VERSION "HNNBNNNYNNNNNNNNNNNNNNNNNNNNNNNNNNNNNNNNNN/4/%%%/4/'%**4NNN///"

NS_ :

BS_:

BU_: AWC BAP_Tester BMC_MLBevo BMS_MV BMS_NV DCDC_800V_PAG DCDC_HV DCDC_HV_02 DCDC_IHEV FCU_MLBevo_FCEV Gateway Gateway_PAG Ladegeraet_2 Ladegeraet_Konzern LE1 LE2 LE2_3_MLBevo_LB LE_MLBevo LE_MLBevo_LB Sub_Gateway TME

BO_ 2589283856 DC_MV_Komponentenfehler_03: 8 DCDC_IHEV
 SG_ DC_MV_Komponentenfehler_63 : 0|2@1+ (1,0) [0|3] "" Vector__XXX
 SG_ DC_MV_Komponentenfehler_64 : 2|2@1+ (1,0) [0|3] "" Vector__XXX
 SG_ DC_MV_Komponentenfehler_65 : 4|2@1+ (1,0) [0|3] "" Vector__XXX
 SG_ DC_MV_Komponentenfehler_66 : 6|2@1+ (1,0) [0|3] "" Vector__XXX
 SG_ DC_MV_Komponentenfehler_67 : 8|2@1+ (1,0) [0|3] "" Vector__XXX
 SG_ DC_MV_Komponentenfehler_68 : 10|2@1+ (1,0) [0|3] "" Vector__XXX
 SG_ DC_MV_Komponentenfehler_69 : 12|2@1+ (1,0) [0|3] "" Vector__XXX
 SG_ DC_MV_Komponentenfehler_70 : 14|2@1+ (1,0) [0|3] "" Vector__XXX
 SG_ DC_MV_Komponentenfehler_71 : 16|2@1+ (1,0) [0|3] "" Vector__XXX
 SG_ DC_MV_Komponentenfehler_72 : 18|2@1+ (1,0) [0|3] "" Vector__XXX
 SG_ DC_MV_Komponentenfehler_73 : 20|2@1+ (1,0) [0|3] "" Vector__XXX
 SG_ DC_MV_Komponentenfehler_74 : 22|2@1+ (1,0) [0|3] "" Vector__XXX
 SG_ DC_MV_Komponentenfehler_75 : 24|2@1+ (1,0) [0|3] "" Vector__XXX
 SG_ DC_MV_Komponentenfehler_76 : 26|2@1+ (1,0) [0|3] "" Vector__XXX
 SG_ DC_MV_Komponentenfehler_77 : 28|2@1+ (1,0) [0|3] "" Vector__XXX
 SG_ DC_MV_Komponentenfehler_78 : 30|2@1+ (1,0) [0|3] "" Vector__XXX
 SG_ DC_MV_Komponentenfehler_79 : 32|2@1+ (1,0) [0|3] "" Vector__XXX
 SG_ DC_MV_Komponentenfehler_80 : 34|2@1+ (1,0) [0|3] "" Vector__XXX
 SG_ DC_MV_Komponentenfehler_81 : 36|2@1+ (1,0) [0|3] "" Vector__XXX
 SG_ DC_MV_Komponentenfehler_82 : 38|2@1+ (1,0) [0|3] "" Vector__XXX
 SG_ DC_MV_Komponentenfehler_83 : 40|2@1+ (1,0) [0|3] "" Vector__XXX
 SG_ DC_MV_Komponentenfehler_84 : 42|2@1+ (1,0) [0|3] "" Vector__XXX
 SG_ DC_MV_Komponentenfehler_85 : 44|2@1+ (1,0) [0|3] "" Vector__XXX
 SG_ DC_MV_Komponentenfehler_86 : 46|2@1+ (1,0) [0|3] "" Vector__XXX
 SG_ DC_MV_Komponentenfehler_87 : 48|2@1+ (1,0) [0|3] "" Vector__XXX
 SG_ DC_MV_Komponentenfehler_88 : 50|2@1+ (1,0) [0|3] "" Vector__XXX
 SG_ DC_MV_Komponentenfehler_89 : 52|2@1+ (1,0) [0|3] "" Vector__XXX
 SG_ DC_MV_Komponentenfehler_90 : 54|2@1+ (1,0) [0|3] "" Vector__XXX
 SG_ DC_MV_Komponentenfehler_91 : 56|2@1+ (1,0) [0|3] "" Vector__XXX
 SG_ DC_MV_Komponentenfehler_92 : 58|2@1+ (1,0) [0|3] "" Vector__XXX
 SG_ DC_MV_Komponentenfehler_93 : 60|2@1+ (1,0) [0|3] "" Vector__XXX

BO_ 2589283857 DC_MV_Komponentenfehler_04: 8 DCDC_IHEV
 SG_ DC_MV_Komponentenfehler_94 : 0|2@1+ (1,0) [0|3] "" Vector__XXX
 SG_ DC_MV_Komponentenfehler_95 : 2|2@1+ (1,0) [0|3] "" Vector__XXX
 SG_ DC_MV_Komponentenfehler_96 : 4|2@1+ (1,0) [0|3] "" Vector__XXX
 SG_ DC_MV_Komponentenfehler_97 : 6|2@1+ (1,0) [0|3] "" Vector__XXX
 SG_ DC_MV_Komponentenfehler_98 : 8|2@1+ (1,0) [0|3] "" Vector__XXX
 SG_ DC_MV_Komponentenfehler_99 : 10|2@1+ (1,0) [0|3] "" Vector__XXX
 SG_ DC_MV_Komponentenfehler_100 : 12|2@1+ (1,0) [0|3] "" Vector__XXX
 SG_ DC_MV_Komponentenfehler_101 : 14|2@1+ (1,0) [0|3] "" Vector__XXX
 SG_ DC_MV_Komponentenfehler_102 : 16|2@1+ (1,0) [0|3] "" Vector__XXX
 SG_ DC_MV_Komponentenfehler_103 : 18|2@1+ (1,0) [0|3] "" Vector__XXX
 SG_ DC_MV_Komponentenfehler_104 : 20|2@1+ (1,0) [0|3] "" Vector__XXX
 SG_ DC_MV_Komponentenfehler_105 : 22|2@1+ (1,0) [0|3] "" Vector__XXX
 SG_ DC_MV_Komponentenfehler_106 : 24|2@1+ (1,0) [0|3] "" Vector__XXX
 SG_ DC_MV_Komponentenfehler_107 : 26|2@1+ (1,0) [0|3] "" Vector__XXX
 SG_ DC_MV_Komponentenfehler_108 : 28|2@1+ (1,0) [0|3] "" Vector__XXX
 SG_ DC_MV_Komponentenfehler_109 : 30|2@1+ (1,0) [0|3] "" Vector__XXX
 SG_ DC_MV_Komponentenfehler_110 : 32|2@1+ (1,0) [0|3] "" Vector__XXX
 SG_ DC_MV_Komponentenfehler_111 : 34|2@1+ (1,0) [0|3] "" Vector__XXX
 SG_ DC_MV_Komponentenfehler_112 : 36|2@1+ (1,0) [0|3] "" Vector__XXX
 SG_ DC_MV_Komponentenfehler_113 : 38|2@1+ (1,0) [0|3] "" Vector__XXX
 SG_ DC_MV_Komponentenfehler_114 : 40|2@1+ (1,0) [0|3] "" Vector__XXX
 SG_ DC_MV_Komponentenfehler_115 : 42|2@1+ (1,0) [0|3] "" Vector__XXX
 SG_ DC_MV_Komponentenfehler_116 : 44|2@1+ (1,0) [0|3] "" Vector__XXX
 SG_ DC_MV_Komponentenfehler_117 : 46|2@1+ (1,0) [0|3] "" Vector__XXX
 SG_ DC_MV_Komponentenfehler_118 : 48|2@1+ (1,0) [0|3] "" Vector__XXX
 SG_ DC_MV_Komponentenfehler_119 : 50|2@1+ (1,0) [0|3] "" Vector__XXX
 SG_ DC_MV_Komponentenfehler_120 : 52|2@1+ (1,0) [0|3] "" Vector__XXX
 SG_ DC_MV_Komponentenfehler_121 : 54|2@1+ (1,0) [0|3] "" Vector__XXX
 SG_ DC_MV_Komponentenfehler_122 : 56|2@1+ (1,0) [0|3] "" Vector__XXX
 SG_ DC_MV_Komponentenfehler_123 : 58|2@1+ (1,0) [0|3] "" Vector__XXX
 SG_ DC_MV_Komponentenfehler_124 : 60|2@1+ (1,0) [0|3] "" Vector__XXX

BO_ 2589283858 DC_MV_Komponentenfehler_05: 8 DCDC_IHEV
 SG_ DC_MV_Komponentenfehler_125 : 0|2@1+ (1,0) [0|3] "" Vector__XXX
 SG_ DC_MV_Komponentenfehler_126 : 2|2@1+ (1,0) [0|3] "" Vector__XXX
 SG_ DC_MV_Komponentenfehler_127 : 4|2@1+ (1,0) [0|3] "" Vector__XXX
 SG_ DC_MV_Komponentenfehler_128 : 6|2@1+ (1,0) [0|3] "" Vector__XXX
 SG_ DC_MV_Komponentenfehler_129 : 8|2@1+ (1,0) [0|3] "" Vector__XXX
 SG_ DC_MV_Komponentenfehler_130 : 10|2@1+ (1,0) [0|3] "" Vector__XXX
 SG_ DC_MV_Komponentenfehler_131 : 12|2@1+ (1,0) [0|3] "" Vector__XXX
 SG_ DC_MV_Komponentenfehler_132 : 14|2@1+ (1,0) [0|3] "" Vector__XXX
 SG_ DC_MV_Komponentenfehler_133 : 16|2@1+ (1,0) [0|3] "" Vector__XXX
 SG_ DC_MV_Komponentenfehler_134 : 18|2@1+ (1,0) [0|3] "" Vector__XXX
 SG_ DC_MV_Komponentenfehler_135 : 20|2@1+ (1,0) [0|3] "" Vector__XXX
 SG_ DC_MV_Komponentenfehler_136 : 22|2@1+ (1,0) [0|3] "" Vector__XXX
 SG_ DC_MV_Komponentenfehler_137 : 24|2@1+ (1,0) [0|3] "" Vector__XXX
 SG_ DC_MV_Komponentenfehler_138 : 26|2@1+ (1,0) [0|3] "" Vector__XXX
 SG_ DC_MV_Komponentenfehler_139 : 28|2@1+ (1,0) [0|3] "" Vector__XXX
 SG_ DC_MV_Komponentenfehler_140 : 30|2@1+ (1,0) [0|3] "" Vector__XXX
 SG_ DC_MV_Komponentenfehler_141 : 32|2@1+ (1,0) [0|3] "" Vector__XXX
 SG_ DC_MV_Komponentenfehler_142 : 34|2@1+ (1,0) [0|3] "" Vector__XXX
 SG_ DC_MV_Komponentenfehler_143 : 36|2@1+ (1,0) [0|3] "" Vector__XXX
 SG_ DC_MV_Komponentenfehler_144 : 38|2@1+ (1,0) [0|3] "" Vector__XXX
 SG_ DC_MV_Komponentenfehler_145 : 40|2@1+ (1,0) [0|3] "" Vector__XXX

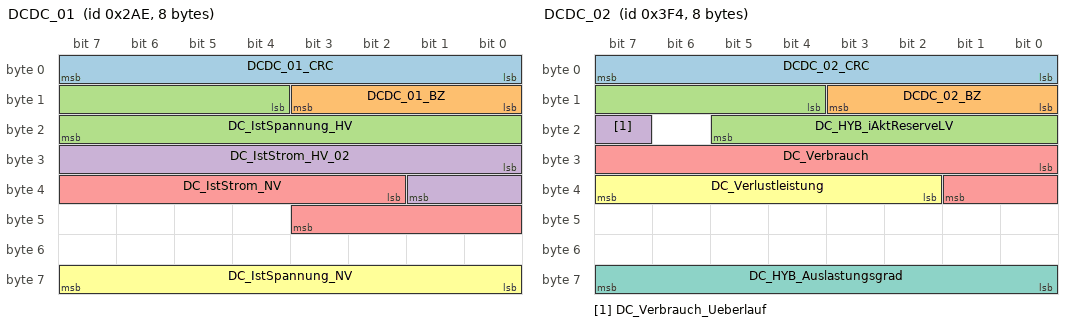
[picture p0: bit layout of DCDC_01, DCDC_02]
BO_ 686 DCDC_01: 8 DCDC_800V_PAG
 SG_ DCDC_01_CRC : 0|8@1+ (1,0) [0|255] ""  Gateway,Gateway_PAG
 SG_ DCDC_01_BZ : 8|4@1+ (1,0) [0|15] ""  Gateway,Gateway_PAG
 SG_ DC_IstSpannung_HV : 12|12@1+ (0.25,0) [0|1023.25] "Unit_Volt"  BMC_MLBevo,DCDC_HV_02,Gateway,Gateway_PAG,TME
 SG_ DC_IstStrom_HV_02 : 24|10@1+ (0.4,-204) [-204|204] "Unit_Amper"  DCDC_HV_02,Gateway,Gateway_PAG,Ladegeraet_Konzern,TME
 SG_ DC_IstStrom_NV : 34|10@1+ (1,-511) [-511|510] "Unit_Amper"  Gateway,Gateway_PAG
 SG_ DC_IstSpannung_NV : 56|8@1+ (0.1,0) [0|25.3] "Unit_Volt"  AWC,Gateway,Gateway_PAG,Ladegeraet_2,Ladegeraet_Konzern

BO_ 1012 DCDC_02: 8 DCDC_800V_PAG
 SG_ DCDC_02_CRC : 0|8@1+ (1,0) [0|255] ""  Gateway,Gateway_PAG
 SG_ DCDC_02_BZ : 8|4@1+ (1,0) [0|15] ""  Gateway,Gateway_PAG
 SG_ DC_HYB_iAktReserveLV : 12|10@1+ (1,-511) [-511|510] "Unit_Amper"  Gateway,Gateway_PAG
 SG_ DC_Verbrauch_Ueberlauf : 23|1@1+ (1,0) [0|1] ""  Gateway,Gateway_PAG
 SG_ DC_Verbrauch : 24|10@1+ (1,0) [0|1023] "Unit_WattSecond"  Gateway,Gateway_PAG
 SG_ DC_Verlustleistung : 34|6@1+ (5,0) [0|305] "Unit_Watt"  Gateway,Gateway_PAG,TME
 SG_ DC_HYB_Auslastungsgrad : 56|8@1+ (0.4,0) [0|100] "Unit_PerCent"  Gateway,Gateway_PAG,TME

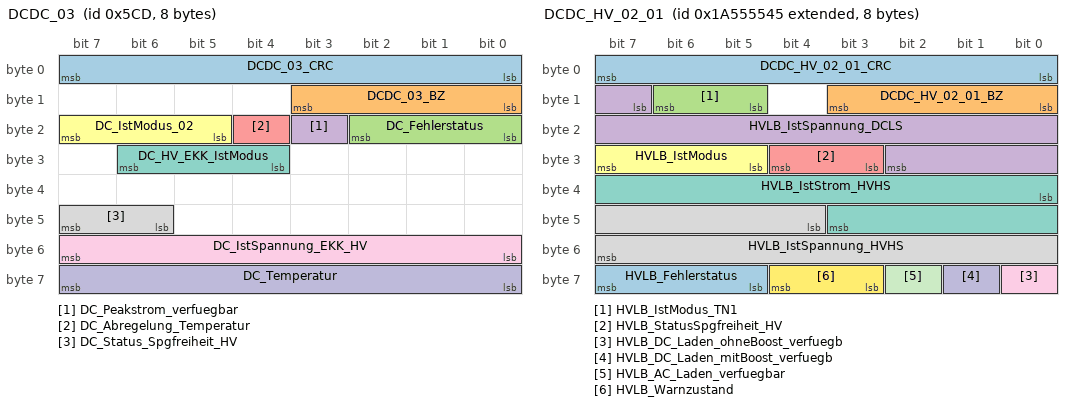
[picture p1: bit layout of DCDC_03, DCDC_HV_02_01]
BO_ 1485 DCDC_03: 8 DCDC_800V_PAG
 SG_ DCDC_03_CRC : 0|8@1+ (1,0) [0|255] ""  Gateway,Gateway_PAG,Sub_Gateway
 SG_ DCDC_03_BZ : 8|4@1+ (1,0) [0|15] ""  Gateway,Gateway_PAG,Sub_Gateway
 SG_ DC_Fehlerstatus : 16|3@1+ (1,0) [0|7] ""  Gateway,Gateway_PAG,Sub_Gateway
 SG_ DC_Peakstrom_verfuegbar : 19|1@1+ (1,0) [0|1] ""  Gateway,Gateway_PAG,Sub_Gateway
 SG_ DC_Abregelung_Temperatur : 20|1@1+ (1,0) [0|1] ""  Gateway_PAG,Sub_Gateway,TME
 SG_ DC_IstModus_02 : 21|3@1+ (1,0) [0|7] ""  DCDC_HV_02,Gateway,Gateway_PAG,Ladegeraet_Konzern,Sub_Gateway,TME
 SG_ DC_HV_EKK_IstModus : 28|3@1+ (1,0) [0|7] ""  Gateway,Gateway_PAG,Sub_Gateway,TME
 SG_ DC_Status_Spgfreiheit_HV : 46|2@1+ (1,0) [0|3] ""  Gateway,Gateway_PAG,Sub_Gateway
 SG_ DC_IstSpannung_EKK_HV : 48|8@1+ (2,0) [0|508] "Unit_Volt"  Gateway,Gateway_PAG,Sub_Gateway
 SG_ DC_Temperatur : 56|8@1+ (1,-40) [-40|213] "Unit_DegreCelsi"  Gateway,Gateway_PAG,Sub_Gateway,TME

BO_ 2527679744 DCDC_FC_03: 8 FCU_MLBevo_FCEV
 SG_ DCDC_FC_IstModus : 12|4@1+ (1,0) [0|15] "" Vector__XXX
 SG_ DCDC_FC_Abschaltung_Ges : 16|1@1+ (1,0) [0|1] "" Vector__XXX
 SG_ DCDC_FC_Abschaltung_Prim : 17|1@1+ (1,0) [0|1] "" Vector__XXX
 SG_ DCDC_FC_Anf_Abschaltung_Ges : 18|1@1+ (1,0) [0|1] "" Vector__XXX
 SG_ DCDC_FC_Anf_Abschaltung_Prim : 19|1@1+ (1,0) [0|1] "" Vector__XXX
 SG_ DCDC_FC_Begrenz_MaxSpannung_Prim : 20|1@1+ (1,0) [0|1] "" Vector__XXX
 SG_ DCDC_FC_Begrenz_MaxSpannung_Sek : 21|1@1+ (1,0) [0|1] "" Vector__XXX
 SG_ DCDC_FC_Begrenz_MaxStrom_Prim : 22|1@1+ (1,0) [0|1] "" Vector__XXX
 SG_ DCDC_FC_Begrenz_MaxStrom_Sek : 23|1@1+ (1,0) [0|1] "" Vector__XXX
 SG_ DCDC_FC_Begrenz_MinSpannung_Prim : 24|1@1+ (1,0) [0|1] "" Vector__XXX
 SG_ DCDC_FC_Begrenz_MinSpannung_Sek : 25|1@1+ (1,0) [0|1] "" Vector__XXX
 SG_ DCDC_FC_Begrenz_MinStrom_Prim : 26|1@1+ (1,0) [0|1] "" Vector__XXX
 SG_ DCDC_FC_Begrenz_Temp : 27|1@1+ (1,0) [0|1] "" Vector__XXX
 SG_ DCDC_FC_Diodenbetrieb : 28|1@1+ (1,0) [0|1] "" Vector__XXX
 SG_ DCDC_FC_Fehlerstatus : 29|3@1+ (1,0) [0|7] "" Vector__XXX
 SG_ DCDC_FC_Status_HVSwitch : 32|3@1+ (1,0) [0|7] "" Vector__XXX
 SG_ DCDC_FC_Status_Interlock : 35|2@1+ (1,0) [0|3] ""  Gateway
 SG_ DCDC_FC_Status_Isowaechter_Netz2 : 37|3@1+ (1,0) [0|7] ""  Gateway
 SG_ DCDC_FC_Status_Kl15c : 40|2@1+ (1,0) [0|3] "" Vector__XXX
 SG_ DCDC_FC_Status_Kl30C : 42|2@1+ (1,0) [0|3] "" Vector__XXX
 SG_ DCDC_FC_Temperatur : 56|8@1+ (1,-40) [-40|213] "Unit_DegreCelsi"  TME

BO_ 2589283653 DCDC_HV_02_01: 8 DCDC_HV_02
 SG_ DCDC_HV_02_01_CRC : 0|8@1+ (1,0) [0|255] ""  Gateway,Gateway_PAG,Ladegeraet_Konzern
 SG_ DCDC_HV_02_01_BZ : 8|4@1+ (1,0) [0|15] ""  Gateway,Gateway_PAG,Ladegeraet_Konzern
 SG_ HVLB_IstModus_TN1 : 13|2@1+ (1,0) [0|3] ""  Gateway,Gateway_PAG
 SG_ HVLB_IstSpannung_DCLS : 15|12@1+ (0.25,0) [0|1023.25] "Unit_Volt"  Ladegeraet_Konzern
 SG_ HVLB_StatusSpgfreiheit_HV : 27|2@1+ (1,0) [0|3] ""  Gateway,Gateway_PAG
 SG_ HVLB_IstModus : 29|3@1+ (1,0) [0|7] ""  Ladegeraet_Konzern,TME
 SG_ HVLB_IstStrom_HVHS : 32|12@1+ (0.25,-512) [-512|511.25] "Unit_Amper"  Ladegeraet_Konzern
 SG_ HVLB_IstSpannung_HVHS : 44|12@1+ (0.25,0) [0|1023.25] "Unit_Volt"  Gateway,Gateway_PAG,Ladegeraet_Konzern
 SG_ HVLB_DC_Laden_ohneBoost_verfuegb : 56|1@1+ (1,0) [0|1] ""  Ladegeraet_Konzern
 SG_ HVLB_DC_Laden_mitBoost_verfuegb : 57|1@1+ (1,0) [0|1] ""  Ladegeraet_Konzern
 SG_ HVLB_AC_Laden_verfuegbar : 58|1@1+ (1,0) [0|1] ""  Ladegeraet_Konzern
 SG_ HVLB_Warnzustand : 59|2@1+ (1,0) [0|3] ""  Ladegeraet_Konzern
 SG_ HVLB_Fehlerstatus : 61|3@1+ (1,0) [0|7] ""  Gateway,Gateway_PAG,Ladegeraet_Konzern

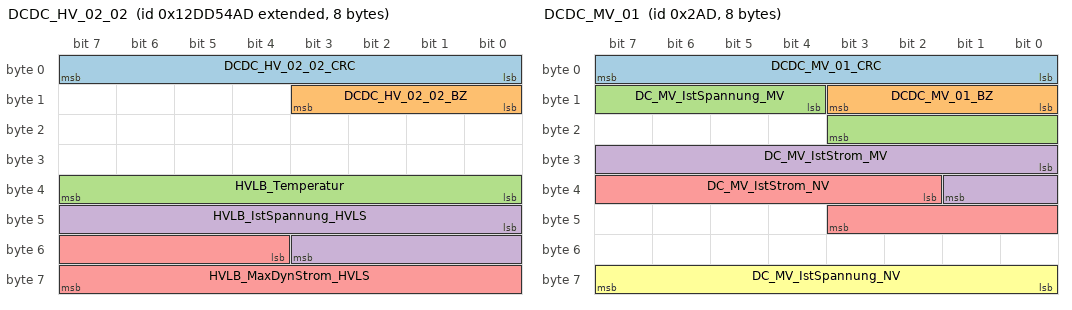
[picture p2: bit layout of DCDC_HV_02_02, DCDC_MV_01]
BO_ 2463978669 DCDC_HV_02_02: 8 DCDC_HV_02
 SG_ DCDC_HV_02_02_CRC : 0|8@1+ (1,0) [0|255] ""  Gateway_PAG,Ladegeraet_Konzern
 SG_ DCDC_HV_02_02_BZ : 8|4@1+ (1,0) [0|15] ""  Gateway_PAG,Ladegeraet_Konzern
 SG_ HVLB_Temperatur : 32|8@1+ (1,-40) [-40|213] "Unit_DegreCelsi"  Gateway_PAG,TME
 SG_ HVLB_IstSpannung_HVLS : 40|12@1+ (0.25,0) [0|1023.25] "Unit_Volt"  Gateway_PAG,Ladegeraet_Konzern
 SG_ HVLB_MaxDynStrom_HVLS : 52|12@1+ (0.25,-512) [-512|511.25] "Unit_Amper"  Gateway_PAG,Ladegeraet_Konzern

BO_ 2589283662 DCDC_HV_02_03: 8 DCDC_HV_02
 SG_ HVLB_PlanAntw_Verlustleistung : 48|12@1+ (50,0) [0|204650] "Unit_Watt"  Ladegeraet_Konzern,TME
 SG_ HVLB_PlanAntw_Zaehler : 60|4@1+ (1,0) [0|13] "Unit_None"  Ladegeraet_Konzern,TME

BO_ 685 DCDC_MV_01: 8 DCDC_800V_PAG
 SG_ DCDC_MV_01_CRC : 0|8@1+ (1,0) [0|255] ""  Gateway,Gateway_PAG
 SG_ DCDC_MV_01_BZ : 8|4@1+ (1,0) [0|15] ""  Gateway,Gateway_PAG
 SG_ DC_MV_IstSpannung_MV : 12|8@1+ (0.25,0) [0|63.25] "Unit_Volt"  Gateway,Gateway_PAG
 SG_ DC_MV_IstStrom_MV : 24|10@1+ (0.4,-204) [-204|204] "Unit_Amper"  Gateway,Gateway_PAG
 SG_ DC_MV_IstStrom_NV : 34|10@1+ (1,-511) [-511|510] "Unit_Amper"  Gateway,Gateway_PAG
 SG_ DC_MV_IstSpannung_NV : 56|8@1+ (0.1,0) [0|25.3] "Unit_Volt"  Gateway,Gateway_PAG

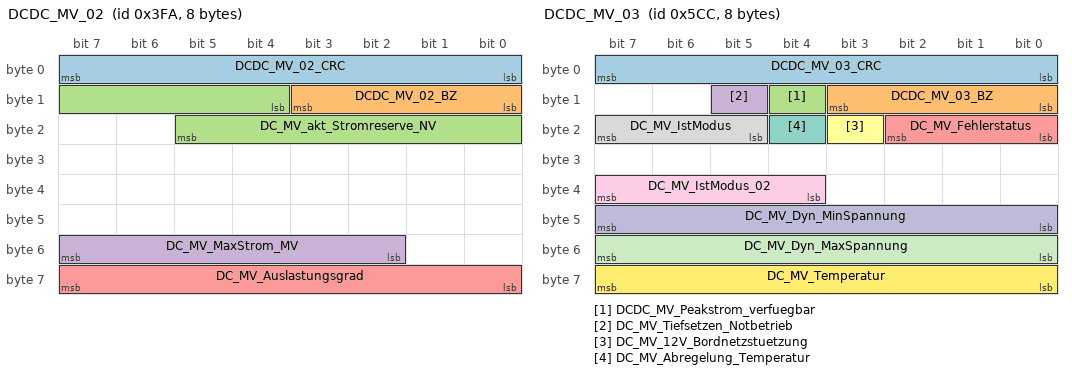
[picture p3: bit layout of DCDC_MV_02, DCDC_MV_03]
BO_ 1018 DCDC_MV_02: 8 DCDC_800V_PAG
 SG_ DCDC_MV_02_CRC : 0|8@1+ (1,0) [0|255] ""  Gateway,Gateway_PAG
 SG_ DCDC_MV_02_BZ : 8|4@1+ (1,0) [0|15] ""  Gateway,Gateway_PAG
 SG_ DC_MV_akt_Stromreserve_NV : 12|10@1+ (1,-511) [-511|510] "Unit_Amper"  Gateway,Gateway_PAG
 SG_ DC_MV_MaxStrom_MV : 50|6@1+ (2.5,-152.5) [-152.5|0] "Unit_Amper"  Gateway,Gateway_PAG
 SG_ DC_MV_Auslastungsgrad : 56|8@1+ (0.4,0) [0|100] "Unit_PerCent"  Gateway,Gateway_PAG

BO_ 1484 DCDC_MV_03: 8 DCDC_800V_PAG
 SG_ DCDC_MV_03_CRC : 0|8@1+ (1,0) [0|255] ""  Gateway,Gateway_PAG,Sub_Gateway
 SG_ DCDC_MV_03_BZ : 8|4@1+ (1,0) [0|15] ""  Gateway,Gateway_PAG,Sub_Gateway
 SG_ DCDC_MV_Peakstrom_verfuegbar : 12|1@1+ (1,0) [0|1] ""  Gateway,Gateway_PAG,Sub_Gateway
 SG_ DC_MV_Tiefsetzen_Notbetrieb : 13|1@1+ (1,0) [0|1] ""  Gateway,Gateway_PAG,Sub_Gateway
 SG_ DC_MV_Fehlerstatus : 16|3@1+ (1,0) [0|7] ""  Gateway,Gateway_PAG,Sub_Gateway
 SG_ DC_MV_12V_Bordnetzstuetzung : 19|1@1+ (1,0) [0|1] ""  Gateway,Gateway_PAG,Sub_Gateway
 SG_ DC_MV_Abregelung_Temperatur : 20|1@1+ (1,0) [0|1] ""  Gateway_PAG,Sub_Gateway,TME
 SG_ DC_MV_IstModus : 21|3@1+ (1,0) [0|7] ""  Gateway,Gateway_PAG,Sub_Gateway
 SG_ DC_MV_IstModus_02 : 36|4@1+ (1,0) [0|15] ""  Gateway,Gateway_PAG,Sub_Gateway
 SG_ DC_MV_Dyn_MinSpannung : 40|8@1+ (0.25,0) [0|63.25] "Unit_Volt"  Gateway,Gateway_PAG,Sub_Gateway
 SG_ DC_MV_Dyn_MaxSpannung : 48|8@1+ (0.25,0) [0|63.25] "Unit_Volt"  Gateway,Gateway_PAG,Sub_Gateway
 SG_ DC_MV_Temperatur : 56|8@1+ (1,-40) [-40|213] "Unit_DegreCelsi"  Gateway_PAG,Sub_Gateway,TME

BO_ 2617015040 DEV_AWC_Resp_00: 8 AWC
 SG_ DEV_AWC_Resp_00_Data : 0|64@1+ (1,0) [0|1.84467440737096E+019] "" Vector__XXX

BO_ 2617015295 DEV_AWC_Resp_FF: 8 AWC
 SG_ DEV_AWC_Resp_FF_Data : 0|64@1+ (1,0) [0|1.84467440737096E+019] "" Vector__XXX

BO_ 2617078528 DEV_BattRegelung_Req_00: 8 Vector__XXX
 SG_ DEV_BattRegelung_Req_00_Data : 0|64@1+ (1,0) [0|1.84467440737096E+019] ""  BMS_NV

BO_ 2617078783 DEV_BattRegelung_Resp_FF: 8 BMS_NV
 SG_ DEV_BattRegelung_Resp_FF_Data : 0|64@1+ (1,0) [0|1.84467440737096E+019] "" Vector__XXX

BO_ 2617041664 DEV_BMS_MV_Resp_00: 8 Vector__XXX
 SG_ DEV_BMS_MV_Resp_00_Data : 0|64@1+ (1,0) [0|1.84467440737096E+019] "" Vector__XXX

BO_ 2617041919 DEV_BMS_MV_Resp_FF: 8 Vector__XXX
 SG_ DEV_BMS_MV_Resp_FF_Data : 0|64@1+ (1,0) [0|1.84467440737096E+019] "" Vector__XXX

BO_ 2617235968 DEV_BMS_Resp_00: 8 BMC_MLBevo
 SG_ DEV_BMS_Resp_00_Data : 0|64@1+ (1,0) [0|1.84467440737096E+019] "" Vector__XXX

BO_ 2617236223 DEV_BMS_Resp_FF: 8 BMC_MLBevo
 SG_ DEV_BMS_Resp_FF_Data : 0|64@1+ (1,0) [0|1.84467440737096E+019] "" Vector__XXX

BO_ 2617129728 DEV_DCDC_HV_02_Req_01: 8 Vector__XXX
 SG_ DEV_DCDC_HV_02_Req_01_Data : 0|64@1+ (1,0) [0|1.84467440737096E+019] ""  DCDC_HV_02

BO_ 2617129729 DEV_DCDC_HV_02_Resp_01: 8 DCDC_HV_02
 SG_ DEV_DCDC_HV_02_Resp_01_Data : 0|64@1+ (1,0) [0|1.84467440737096E+019] "" Vector__XXX

BO_ 2617129983 DEV_DCDC_HV_02_Resp_FF: 8 DCDC_HV_02
 SG_ DEV_DCDC_HV_02_Resp_FF_Data : 0|64@1+ (1,0) [0|1.84467440737096E+019] "" Vector__XXX

BO_ 2617096960 DEV_DCDC_HV_Resp_00: 8 DCDC_800V_PAG
 SG_ DEV_DCDC_HV_Resp_00_Data : 0|64@1+ (1,0) [0|1.84467440737096E+019] "" Vector__XXX

BO_ 2617097215 DEV_DCDC_HV_Resp_FF: 8 DCDC_800V_PAG
 SG_ DEV_DCDC_HV_Resp_FF_Data : 0|64@1+ (1,0) [0|1.84467440737096E+019] "" Vector__XXX

BO_ 2617117184 DEV_DCDC_Resp_00: 8 DCDC_IHEV
 SG_ DEV_DCDC_Resp_00_Data : 0|64@1+ (1,0) [0|1.84467440737096E+019] "" Vector__XXX

BO_ 2617117439 DEV_DCDC_Resp_FF: 8 DCDC_IHEV
 SG_ DEV_DCDC_Resp_FF_Data : 0|64@1+ (1,0) [0|1.84467440737096E+019] "" Vector__XXX

BO_ 2617092864 DEV_FCU_Req_01: 8 Vector__XXX
 SG_ DEV_FCU_Req_01_Data : 0|64@1+ (1,0) [0|1.84467440737096E+019] ""  FCU_MLBevo_FCEV

BO_ 2617093119 DEV_FCU_Resp_FF: 8 FCU_MLBevo_FCEV
 SG_ DEV_FCU_Resp_FF_Data : 0|64@1+ (1,0) [0|1.84467440737096E+019] "" Vector__XXX

BO_ 2617193216 DEV_Ladegeraet_2_Req_01: 8 Vector__XXX
 SG_ DEV_Ladegeraet_2_Req_01_Data : 0|64@1+ (1,0) [0|1.84467440737096E+019] ""  Ladegeraet_2

BO_ 2617193217 DEV_Ladegeraet_2_Resp_01: 8 Ladegeraet_2
 SG_ DEV_Ladegeraet_2_Resp_01_Data : 0|64@1+ (1,0) [0|1.84467440737096E+019] "" Vector__XXX

BO_ 2617193471 DEV_Ladegeraet_2_Resp_FF: 8 Ladegeraet_2
 SG_ DEV_Ladegeraet_2_Resp_FF_Data : 0|64@1+ (1,0) [0|1.84467440737096E+019] "" Vector__XXX

BO_ 2617123328 DEV_Ladegeraet_Req_01: 8 Vector__XXX
 SG_ DEV_Ladegeraet_Req_01_Data : 0|64@1+ (1,0) [0|1.84467440737096E+019] ""  Ladegeraet_Konzern

BO_ 2617123329 DEV_Ladegeraet_Resp_01: 8 Ladegeraet_Konzern
 SG_ DEV_Ladegeraet_Resp_01_Data : 0|64@1+ (1,0) [0|1.84467440737096E+019] "" Vector__XXX

BO_ 2617123583 DEV_Ladegeraet_Resp_FF: 8 Ladegeraet_Konzern
 SG_ DEV_Ladegeraet_Resp_FF_Data : 0|64@1+ (1,0) [0|1.84467440737096E+019] "" Vector__XXX

BO_ 2617238016 DEV_LEH_01_Resp_00: 8 DCDC_HV
 SG_ DEV_LEH_01_Resp_00_Data : 0|64@1+ (1,0) [0|1.84467440737096E+019] "" Vector__XXX

BO_ 2617238271 DEV_LEH_01_Resp_FF: 8 DCDC_HV
 SG_ DEV_LEH_01_Resp_FF_Data : 0|64@1+ (1,0) [0|1.84467440737096E+019] "" Vector__XXX

BO_ 2617119232 DEV_TME_Resp_00: 8 TME
 SG_ DEV_TME_Resp_00_Data : 0|64@1+ (1,0) [0|1.84467440737096E+019] "" Vector__XXX

BO_ 2617119487 DEV_TME_Resp_FF: 8 TME
 SG_ DEV_TME_Resp_FF_Data : 0|64@1+ (1,0) [0|1.84467440737096E+019] "" Vector__XXX

BO_ 2549880528 DIA_BJB_Req: 8 Gateway
 SG_ DIA_BJB_Req_Data : 0|64@1+ (1,0) [0|1.84467440737096E+019] ""  BMC_MLBevo

BO_ 2550011600 DIA_BJB_Resp: 8 BMC_MLBevo
 SG_ DIA_BJB_Resp_Data : 0|64@1+ (1,0) [0|1.84467440737096E+019] ""  Gateway,Gateway_PAG

BO_ 2549880529 DIA_CMC_01_Req: 8 Gateway
 SG_ DIA_CMC_01_Req_Data : 0|64@1+ (1,0) [0|1.84467440737096E+019] ""  BMC_MLBevo

BO_ 2550011601 DIA_CMC_01_Resp: 8 BMC_MLBevo
 SG_ DIA_CMC_01_Resp_Data : 0|64@1+ (1,0) [0|1.84467440737096E+019] ""  Gateway,Gateway_PAG

BO_ 2549880530 DIA_CMC_02_Req: 8 Gateway
 SG_ DIA_CMC_02_Req_Data : 0|64@1+ (1,0) [0|1.84467440737096E+019] ""  BMC_MLBevo

BO_ 2550011602 DIA_CMC_02_Resp: 8 BMC_MLBevo
 SG_ DIA_CMC_02_Resp_Data : 0|64@1+ (1,0) [0|1.84467440737096E+019] ""  Gateway,Gateway_PAG

BO_ 2549880531 DIA_CMC_03_Req: 8 Gateway
 SG_ DIA_CMC_03_Req_Data : 0|64@1+ (1,0) [0|1.84467440737096E+019] ""  BMC_MLBevo

BO_ 2550011603 DIA_CMC_03_Resp: 8 BMC_MLBevo
 SG_ DIA_CMC_03_Resp_Data : 0|64@1+ (1,0) [0|1.84467440737096E+019] ""  Gateway,Gateway_PAG

BO_ 2549880532 DIA_CMC_04_Req: 8 Gateway
 SG_ DIA_CMC_04_Req_Data : 0|64@1+ (1,0) [0|1.84467440737096E+019] ""  BMC_MLBevo

BO_ 2550011604 DIA_CMC_04_Resp: 8 BMC_MLBevo
 SG_ DIA_CMC_04_Resp_Data : 0|64@1+ (1,0) [0|1.84467440737096E+019] ""  Gateway,Gateway_PAG

BO_ 2549880533 DIA_CMC_05_Req: 8 Gateway
 SG_ DIA_CMC_05_Req_Data : 0|64@1+ (1,0) [0|1.84467440737096E+019] ""  BMC_MLBevo

BO_ 2550011605 DIA_CMC_05_Resp: 8 BMC_MLBevo
 SG_ DIA_CMC_05_Resp_Data : 0|64@1+ (1,0) [0|1.84467440737096E+019] ""  Gateway,Gateway_PAG

BO_ 2549880534 DIA_CMC_06_Req: 8 Gateway
 SG_ DIA_CMC_06_Req_Data : 0|64@1+ (1,0) [0|1.84467440737096E+019] ""  BMC_MLBevo

BO_ 2550011606 DIA_CMC_06_Resp: 8 BMC_MLBevo
 SG_ DIA_CMC_06_Resp_Data : 0|64@1+ (1,0) [0|1.84467440737096E+019] ""  Gateway,Gateway_PAG

BO_ 2549880535 DIA_CMC_07_Req: 8 Gateway
 SG_ DIA_CMC_07_Req_Data : 0|64@1+ (1,0) [0|1.84467440737096E+019] ""  BMC_MLBevo

BO_ 2550011607 DIA_CMC_07_Resp: 8 BMC_MLBevo
 SG_ DIA_CMC_07_Resp_Data : 0|64@1+ (1,0) [0|1.84467440737096E+019] ""  Gateway,Gateway_PAG

BO_ 2549880536 DIA_CMC_08_Req: 8 Gateway
 SG_ DIA_CMC_08_Req_Data : 0|64@1+ (1,0) [0|1.84467440737096E+019] ""  BMC_MLBevo

BO_ 2550011608 DIA_CMC_08_Resp: 8 BMC_MLBevo
 SG_ DIA_CMC_08_Resp_Data : 0|64@1+ (1,0) [0|1.84467440737096E+019] ""  Gateway,Gateway_PAG

BO_ 2549880537 DIA_CMC_09_Req: 8 Gateway
 SG_ DIA_CMC_09_Req_Data : 0|64@1+ (1,0) [0|1.84467440737096E+019] ""  BMC_MLBevo

BO_ 2550011609 DIA_CMC_09_Resp: 8 BMC_MLBevo
 SG_ DIA_CMC_09_Resp_Data : 0|64@1+ (1,0) [0|1.84467440737096E+019] ""  Gateway,Gateway_PAG

BO_ 2549880538 DIA_CMC_10_Req: 8 Gateway
 SG_ DIA_CMC_10_Req_Data : 0|64@1+ (1,0) [0|1.84467440737096E+019] ""  BMC_MLBevo

BO_ 2550011610 DIA_CMC_10_Resp: 8 BMC_MLBevo
 SG_ DIA_CMC_10_Resp_Data : 0|64@1+ (1,0) [0|1.84467440737096E+019] ""  Gateway,Gateway_PAG

BO_ 2549880539 DIA_CMC_11_Req: 8 Gateway
 SG_ DIA_CMC_11_Req_Data : 0|64@1+ (1,0) [0|1.84467440737096E+019] ""  BMC_MLBevo

BO_ 2550011611 DIA_CMC_11_Resp: 8 BMC_MLBevo
 SG_ DIA_CMC_11_Resp_Data : 0|64@1+ (1,0) [0|1.84467440737096E+019] ""  Gateway,Gateway_PAG

BO_ 2549880540 DIA_CMC_12_Req: 8 Gateway
 SG_ DIA_CMC_12_Req_Data : 0|64@1+ (1,0) [0|1.84467440737096E+019] ""  BMC_MLBevo

BO_ 2550011612 DIA_CMC_12_Resp: 8 BMC_MLBevo
 SG_ DIA_CMC_12_Resp_Data : 0|64@1+ (1,0) [0|1.84467440737096E+019] ""  Gateway,Gateway_PAG

BO_ 2549880561 DIA_CMC_13_Req: 8 Gateway
 SG_ DIA_CMC_13_Req_Data : 0|64@1+ (1,0) [0|1.84467440737096E+019] ""  BMC_MLBevo

BO_ 2550011633 DIA_CMC_13_Resp: 8 BMC_MLBevo
 SG_ DIA_CMC_13_Resp_Data : 0|64@1+ (1,0) [0|1.84467440737096E+019] ""  Gateway,Gateway_PAG

BO_ 2549880562 DIA_CMC_14_Req: 8 Gateway
 SG_ DIA_CMC_14_Req_Data : 0|64@1+ (1,0) [0|1.84467440737096E+019] ""  BMC_MLBevo

BO_ 2550011634 DIA_CMC_14_Resp: 8 BMC_MLBevo
 SG_ DIA_CMC_14_Resp_Data : 0|64@1+ (1,0) [0|1.84467440737096E+019] ""  Gateway,Gateway_PAG

BO_ 2549880563 DIA_CMC_15_Req: 8 Gateway
 SG_ DIA_CMC_15_Req_Data : 0|64@1+ (1,0) [0|1.84467440737096E+019] ""  BMC_MLBevo

BO_ 2550011635 DIA_CMC_15_Resp: 8 BMC_MLBevo
 SG_ DIA_CMC_15_Resp_Data : 0|64@1+ (1,0) [0|1.84467440737096E+019] ""  Gateway,Gateway_PAG

BO_ 2549880717 DIA_eBooster2_Req: 8 Gateway
 SG_ DIA_eBooster2_Req_Data : 0|64@1+ (1,0) [0|1.84467440737096E+019] ""  FCU_MLBevo_FCEV

BO_ 2550011789 DIA_eBooster2_Resp: 8 FCU_MLBevo_FCEV
 SG_ DIA_eBooster2_Resp_Data : 0|64@1+ (1,0) [0|1.84467440737096E+019] ""  Gateway

BO_ 2549880413 DIA_EKK_Req: 8 Gateway
 SG_ DIA_EKK_Req_Data : 0|64@1+ (1,0) [0|1.84467440737096E+019] ""  TME

BO_ 2550011485 DIA_EKK_Resp: 8 TME
 SG_ DIA_EKK_Resp_Data : 0|64@1+ (1,0) [0|1.84467440737096E+019] ""  Gateway,Gateway_PAG

BO_ 2549880512 DIA_HV_H2_Req: 8 Gateway
 SG_ DIA_HV_H2_Req_Data : 0|64@1+ (1,0) [0|1.84467440737096E+019] ""  FCU_MLBevo_FCEV,TME

BO_ 2550011584 DIA_HV_H2_Resp: 8 FCU_MLBevo_FCEV
 SG_ DIA_HV_H2_Resp_Data : 0|64@1+ (1,0) [0|1.84467440737096E+019] ""  Gateway,Gateway_PAG

BO_ 2549880714 DIA_PumpKM_2_Req: 8 Gateway
 SG_ DIA_PumpKM_2_Req_Data : 0|64@1+ (1,0) [0|1.84467440737096E+019] ""  FCU_MLBevo_FCEV

BO_ 2550011786 DIA_PumpKM_2_Resp: 8 FCU_MLBevo_FCEV
 SG_ DIA_PumpKM_2_Resp_Data : 0|64@1+ (1,0) [0|1.84467440737096E+019] ""  Gateway

BO_ 2549880570 DIA_PumpWSt_Req: 8 Gateway
 SG_ DIA_PumpWSt_Req_Data : 0|64@1+ (1,0) [0|1.84467440737096E+019] ""  FCU_MLBevo_FCEV

BO_ 2550011642 DIA_PumpWSt_Resp: 8 FCU_MLBevo_FCEV
 SG_ DIA_PumpWSt_Resp_Data : 0|64@1+ (1,0) [0|1.84467440737096E+019] ""  Gateway

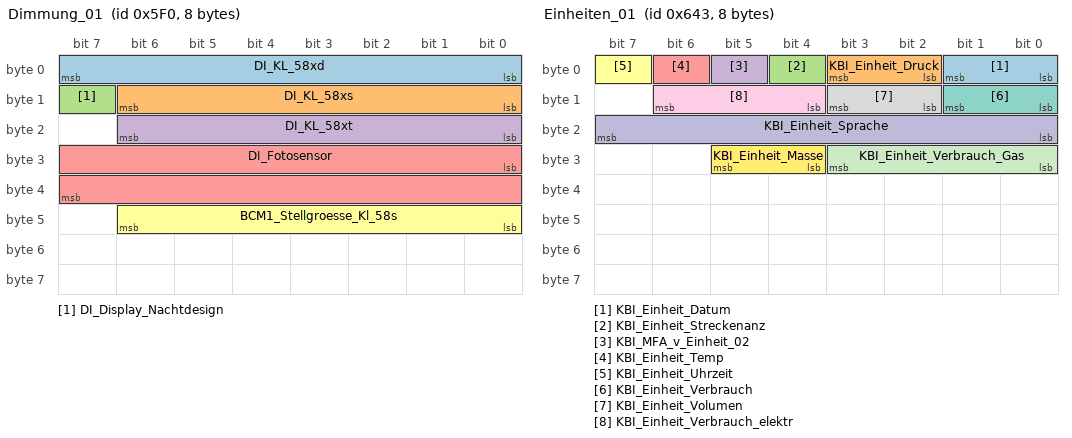
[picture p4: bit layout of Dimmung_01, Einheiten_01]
BO_ 1520 Dimmung_01: 8 Gateway
 SG_ DI_KL_58xd : 0|8@1+ (1,0) [0|253] ""  Ladegeraet_Konzern
 SG_ DI_KL_58xs : 8|7@1+ (1,0) [0|100] "Unit_PerCent"  Ladegeraet_Konzern
 SG_ DI_Display_Nachtdesign : 15|1@1+ (1,0) [0|1] "" Vector__XXX
 SG_ DI_KL_58xt : 16|7@1+ (1,0) [0|100] "Unit_PerCent"  Ladegeraet_Konzern
 SG_ DI_Fotosensor : 24|16@1+ (1,0) [0|65535] "" Vector__XXX
 SG_ BCM1_Stellgroesse_Kl_58s : 40|7@1+ (1,0) [0|100] "" Vector__XXX

BO_ 1603 Einheiten_01: 8 Gateway
 SG_ KBI_Einheit_Datum : 0|2@1+ (1,0) [0|3] "" Vector__XXX
 SG_ KBI_Einheit_Druck : 2|2@1+ (1,0) [0|3] "" Vector__XXX
 SG_ KBI_Einheit_Streckenanz : 4|1@1+ (1,0) [0|1] ""  Ladegeraet_Konzern
 SG_ KBI_MFA_v_Einheit_02 : 5|1@1+ (1,0) [0|1] "" Vector__XXX
 SG_ KBI_Einheit_Temp : 6|1@1+ (1,0) [0|1] ""  TME
 SG_ KBI_Einheit_Uhrzeit : 7|1@1+ (1,0) [0|1] ""  Ladegeraet_Konzern
 SG_ KBI_Einheit_Verbrauch : 8|2@1+ (1,0) [0|3] "" Vector__XXX
 SG_ KBI_Einheit_Volumen : 10|2@1+ (1,0) [0|3] "" Vector__XXX
 SG_ KBI_Einheit_Verbrauch_elektr : 12|3@1+ (1,0) [0|7] "" Vector__XXX
 SG_ KBI_Einheit_Sprache : 16|8@1+ (1,0) [0|255] "" Vector__XXX
 SG_ KBI_Einheit_Verbrauch_Gas : 24|4@1+ (1,0) [0|15] "" Vector__XXX
 SG_ KBI_Einheit_Masse : 28|2@1+ (1,0) [0|3] "" Vector__XXX

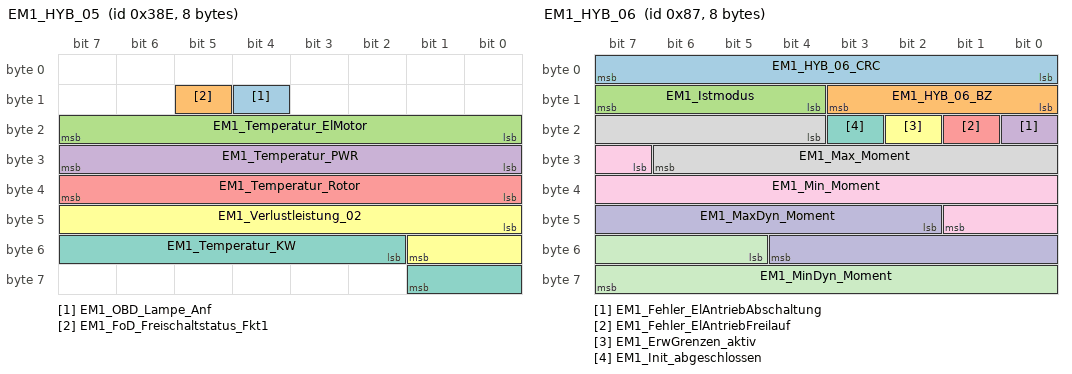
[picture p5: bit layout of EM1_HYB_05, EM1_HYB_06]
BO_ 910 EM1_HYB_05: 8 Gateway
 SG_ EM1_OBD_Lampe_Anf : 12|1@1+ (1,0) [0|1] ""  Sub_Gateway
 SG_ EM1_FoD_Freischaltstatus_Fkt1 : 13|1@1+ (1,0) [0|1] ""  Sub_Gateway
 SG_ EM1_Temperatur_ElMotor : 16|8@1+ (1,-40) [-40|213] "Unit_DegreCelsi"  Sub_Gateway,TME
 SG_ EM1_Temperatur_PWR : 24|8@1+ (1,-40) [-40|213] "Unit_DegreCelsi"  Sub_Gateway,TME
 SG_ EM1_Temperatur_Rotor : 32|8@1+ (1,-40) [-40|213] "Unit_DegreCelsi"  Sub_Gateway,TME
 SG_ EM1_Verlustleistung_02 : 40|10@1+ (80,0) [0|81680] "Unit_Watt"  Sub_Gateway,TME
 SG_ EM1_Temperatur_KW : 50|8@1+ (0.75,-48) [-48|141.75] "Unit_DegreCelsi"  Sub_Gateway

BO_ 135 EM1_HYB_06: 8 Gateway
 SG_ EM1_HYB_06_CRC : 0|8@1+ (1,0) [0|255] ""  Sub_Gateway
 SG_ EM1_HYB_06_BZ : 8|4@1+ (1,0) [0|15] ""  Sub_Gateway
 SG_ EM1_Istmodus : 12|4@1+ (1,0) [0|15] ""  Sub_Gateway
 SG_ EM1_Fehler_ElAntriebAbschaltung : 16|1@1+ (1,0) [0|1] ""  Sub_Gateway
 SG_ EM1_Fehler_ElAntriebFreilauf : 17|1@1+ (1,0) [0|1] ""  Sub_Gateway
 SG_ EM1_ErwGrenzen_aktiv : 18|1@1+ (1,0) [0|1] ""  Sub_Gateway
 SG_ EM1_Init_abgeschlossen : 19|1@1+ (1,0) [0|1] ""  Sub_Gateway
 SG_ EM1_Max_Moment : 20|11@1+ (1,-1023) [-1023|1022] "Unit_NewtoMeter"  Sub_Gateway
 SG_ EM1_Min_Moment : 31|11@1+ (1,-1023) [-1023|1022] "Unit_NewtoMeter"  Sub_Gateway
 SG_ EM1_MaxDyn_Moment : 42|11@1+ (1,-1023) [-1023|1022] "Unit_NewtoMeter"  Sub_Gateway
 SG_ EM1_MinDyn_Moment : 53|11@1+ (1,-1023) [-1023|1022] "Unit_NewtoMeter"  Sub_Gateway

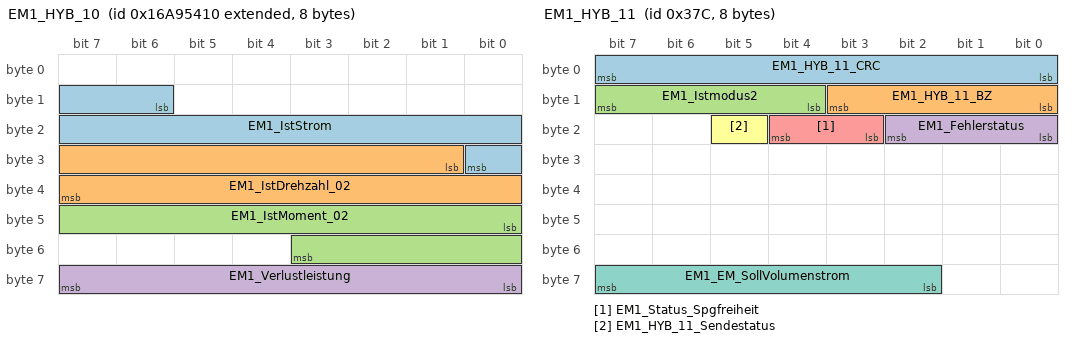
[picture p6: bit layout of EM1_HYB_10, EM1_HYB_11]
BO_ 2527679504 EM1_HYB_10: 8 LE_MLBevo
 SG_ EM1_IstStrom : 14|11@1+ (1,-1023) [-1023|1022] "Unit_Amper"  Sub_Gateway,TME
 SG_ EM1_IstDrehzahl_02 : 25|15@1+ (1,-10000) [-10000|22765] "Unit_MinutInver"  BMC_MLBevo,Sub_Gateway,TME
 SG_ EM1_IstMoment_02 : 40|12@1+ (0.5,-1023) [-1023|1023.5] "Unit_NewtoMeter"  Sub_Gateway,TME
 SG_ EM1_Verlustleistung : 56|8@1+ (20,0) [0|5000] "Unit_Watt"  Sub_Gateway,TME

BO_ 892 EM1_HYB_11: 8 Gateway
 SG_ EM1_HYB_11_CRC : 0|8@1+ (1,0) [0|255] ""  Gateway,Gateway_PAG,Sub_Gateway
 SG_ EM1_HYB_11_BZ : 8|4@1+ (1,0) [0|15] ""  Gateway,Gateway_PAG,Sub_Gateway
 SG_ EM1_Istmodus2 : 12|4@1+ (1,0) [0|15] ""  BMC_MLBevo,Ladegeraet_Konzern,Sub_Gateway,TME
 SG_ EM1_Fehlerstatus : 16|3@1+ (1,0) [0|7] ""  Gateway,Gateway_PAG,Sub_Gateway
 SG_ EM1_Status_Spgfreiheit : 19|2@1+ (1,0) [0|3] ""  Gateway,Gateway_PAG,Sub_Gateway
 SG_ EM1_HYB_11_Sendestatus : 21|1@1+ (1,0) [0|1] ""  Sub_Gateway
 SG_ EM1_EM_SollVolumenstrom : 58|6@1+ (0.5,0) [0|30.5] "Unit_LiterPerMinut"  Sub_Gateway,TME

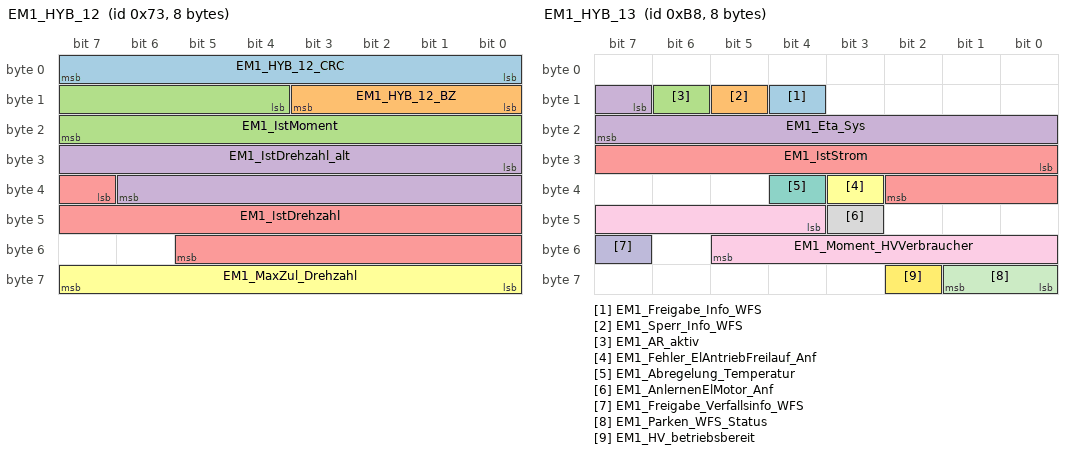
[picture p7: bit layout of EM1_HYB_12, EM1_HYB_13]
BO_ 115 EM1_HYB_12: 8 Gateway
 SG_ EM1_HYB_12_CRC : 0|8@1+ (1,0) [0|255] ""  Sub_Gateway
 SG_ EM1_HYB_12_BZ : 8|4@1+ (1,0) [0|15] ""  Sub_Gateway
 SG_ EM1_IstMoment : 12|12@1+ (0.5,-1023) [-1023|1023.5] "Unit_NewtoMeter"  Sub_Gateway
 SG_ EM1_IstDrehzahl_alt : 24|15@1+ (1,-10000) [-10000|22765] "Unit_MinutInver"  Sub_Gateway
 SG_ EM1_IstDrehzahl : 39|15@1+ (1,-10000) [-10000|22765] "Unit_MinutInver"  Sub_Gateway
 SG_ EM1_MaxZul_Drehzahl : 56|8@1+ (80,0) [0|20240] "Unit_RevPerMinute"  Sub_Gateway

BO_ 184 EM1_HYB_13: 8 Gateway
 SG_ EM1_Freigabe_Info_WFS : 12|1@1+ (1,0) [0|1] ""  Sub_Gateway
 SG_ EM1_Sperr_Info_WFS : 13|1@1+ (1,0) [0|1] ""  Sub_Gateway
 SG_ EM1_AR_aktiv : 14|1@1+ (1,0) [0|1] ""  Sub_Gateway
 SG_ EM1_Eta_Sys : 15|9@1+ (0.2,0) [0|101.8] "Unit_PerCent"  Sub_Gateway
 SG_ EM1_IstStrom : 24|11@1+ (1,-1023) [-1023|1022] "Unit_Amper"  Sub_Gateway
 SG_ EM1_Fehler_ElAntriebFreilauf_Anf : 35|1@1+ (1,0) [0|1] ""  Sub_Gateway
 SG_ EM1_Abregelung_Temperatur : 36|1@1+ (1,0) [0|1] ""  Sub_Gateway
 SG_ EM1_AnlernenElMotor_Anf : 43|1@1+ (1,0) [0|1] ""  Sub_Gateway
 SG_ EM1_Moment_HVVerbraucher : 44|10@1+ (1,-511) [-511|511] "Unit_NewtoMeter"  Sub_Gateway
 SG_ EM1_Freigabe_Verfallsinfo_WFS : 55|1@1+ (1,0) [0|1] ""  Sub_Gateway
 SG_ EM1_Parken_WFS_Status : 56|2@1+ (1,0) [0|3] ""  Sub_Gateway
 SG_ EM1_HV_betriebsbereit : 58|1@1+ (1,0) [0|1] ""  Sub_Gateway

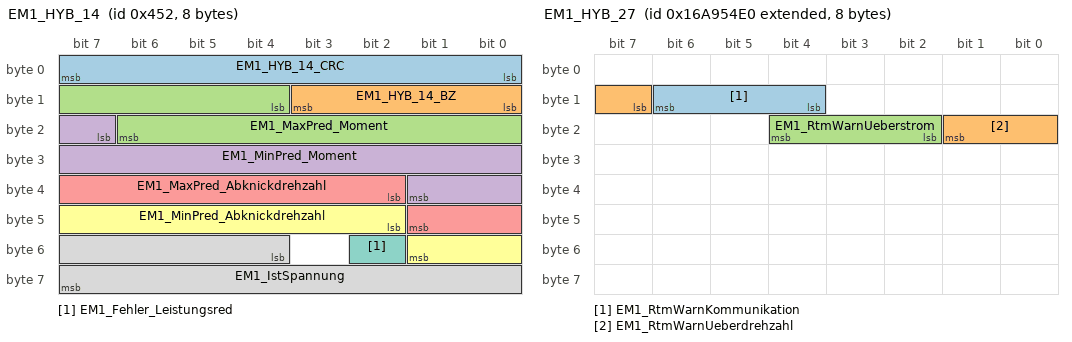
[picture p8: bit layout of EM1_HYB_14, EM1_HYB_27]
BO_ 1106 EM1_HYB_14: 8 Gateway
 SG_ EM1_HYB_14_CRC : 0|8@1+ (1,0) [0|255] ""  Sub_Gateway
 SG_ EM1_HYB_14_BZ : 8|4@1+ (1,0) [0|15] ""  Sub_Gateway
 SG_ EM1_MaxPred_Moment : 12|11@1+ (1,-1023) [-1023|1022] "Unit_NewtoMeter"  Sub_Gateway
 SG_ EM1_MinPred_Moment : 23|11@1+ (1,-1023) [-1023|1022] "Unit_NewtoMeter"  Sub_Gateway
 SG_ EM1_MaxPred_Abknickdrehzahl : 34|8@1+ (50,0) [0|12700] "Unit_MinutInver"  Sub_Gateway
 SG_ EM1_MinPred_Abknickdrehzahl : 42|8@1+ (50,0) [0|12700] "Unit_MinutInver"  Sub_Gateway
 SG_ EM1_Fehler_Leistungsred : 50|1@1+ (1,0) [0|1] ""  Sub_Gateway
 SG_ EM1_IstSpannung : 52|12@1+ (0.25,0) [0|1023.25] "Unit_Volt"  Sub_Gateway

BO_ 2527679712 EM1_HYB_27: 8 Gateway
 SG_ EM1_RtmWarnKommunikation : 12|3@1+ (1,0) [0|7] ""  Sub_Gateway
 SG_ EM1_RtmWarnUeberdrehzahl : 15|3@1+ (1,0) [0|7] ""  Sub_Gateway
 SG_ EM1_RtmWarnUeberstrom : 18|3@1+ (1,0) [0|7] ""  Sub_Gateway

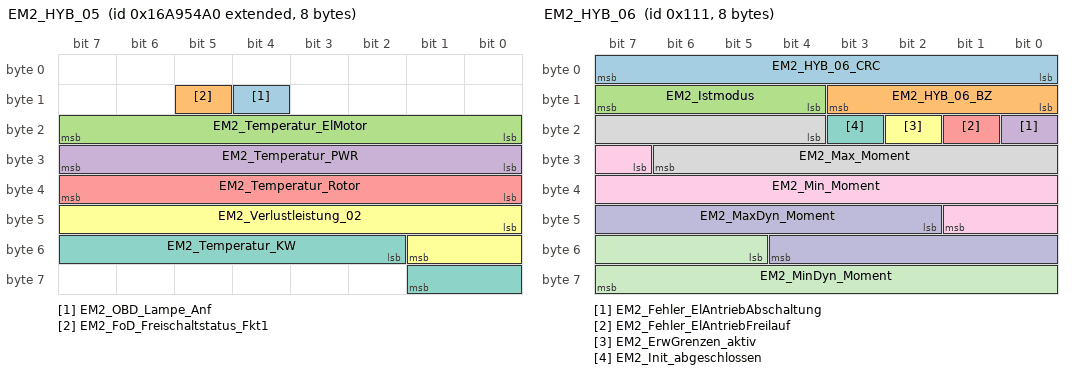
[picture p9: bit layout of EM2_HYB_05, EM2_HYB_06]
BO_ 2527679648 EM2_HYB_05: 8 Gateway
 SG_ EM2_OBD_Lampe_Anf : 12|1@1+ (1,0) [0|1] ""  Sub_Gateway
 SG_ EM2_FoD_Freischaltstatus_Fkt1 : 13|1@1+ (1,0) [0|1] ""  Sub_Gateway
 SG_ EM2_Temperatur_ElMotor : 16|8@1+ (1,-40) [-40|213] "Unit_DegreCelsi"  Sub_Gateway,TME
 SG_ EM2_Temperatur_PWR : 24|8@1+ (1,-40) [-40|213] "Unit_DegreCelsi"  Sub_Gateway,TME
 SG_ EM2_Temperatur_Rotor : 32|8@1+ (1,-40) [-40|213] "Unit_DegreCelsi"  Sub_Gateway,TME
 SG_ EM2_Verlustleistung_02 : 40|10@1+ (80,0) [0|81680] "Unit_Watt"  Sub_Gateway,TME
 SG_ EM2_Temperatur_KW : 50|8@1+ (0.75,-48) [-48|141.75] "Unit_DegreCelsi"  Sub_Gateway

BO_ 273 EM2_HYB_06: 8 Gateway
 SG_ EM2_HYB_06_CRC : 0|8@1+ (1,0) [0|255] ""  Sub_Gateway
 SG_ EM2_HYB_06_BZ : 8|4@1+ (1,0) [0|15] ""  Sub_Gateway
 SG_ EM2_Istmodus : 12|4@1+ (1,0) [0|15] ""  Sub_Gateway
 SG_ EM2_Fehler_ElAntriebAbschaltung : 16|1@1+ (1,0) [0|1] ""  Sub_Gateway
 SG_ EM2_Fehler_ElAntriebFreilauf : 17|1@1+ (1,0) [0|1] ""  Sub_Gateway
 SG_ EM2_ErwGrenzen_aktiv : 18|1@1+ (1,0) [0|1] ""  Sub_Gateway
 SG_ EM2_Init_abgeschlossen : 19|1@1+ (1,0) [0|1] ""  Sub_Gateway
 SG_ EM2_Max_Moment : 20|11@1+ (1,-1023) [-1023|1022] "Unit_NewtoMeter"  Sub_Gateway
 SG_ EM2_Min_Moment : 31|11@1+ (1,-1023) [-1023|1022] "Unit_NewtoMeter"  Sub_Gateway
 SG_ EM2_MaxDyn_Moment : 42|11@1+ (1,-1023) [-1023|1022] "Unit_NewtoMeter"  Sub_Gateway
 SG_ EM2_MinDyn_Moment : 53|11@1+ (1,-1023) [-1023|1022] "Unit_NewtoMeter"  Sub_Gateway

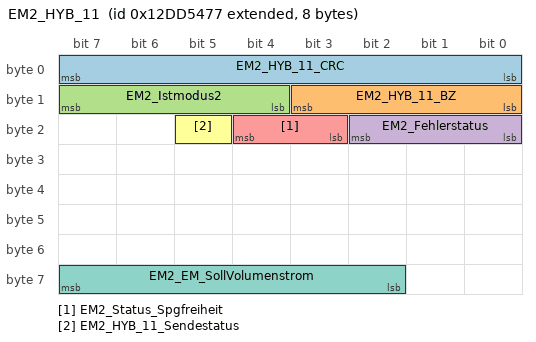
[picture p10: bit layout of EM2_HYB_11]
BO_ 2463978615 EM2_HYB_11: 8 Gateway
 SG_ EM2_HYB_11_CRC : 0|8@1+ (1,0) [0|255] ""  Gateway,Sub_Gateway
 SG_ EM2_HYB_11_BZ : 8|4@1+ (1,0) [0|15] ""  Gateway,Sub_Gateway
 SG_ EM2_Istmodus2 : 12|4@1+ (1,0) [0|15] ""  Sub_Gateway,TME
 SG_ EM2_Fehlerstatus : 16|3@1+ (1,0) [0|7] ""  Gateway,Sub_Gateway
 SG_ EM2_Status_Spgfreiheit : 19|2@1+ (1,0) [0|3] ""  Gateway,Sub_Gateway
 SG_ EM2_HYB_11_Sendestatus : 21|1@1+ (1,0) [0|1] ""  Sub_Gateway
 SG_ EM2_EM_SollVolumenstrom : 58|6@1+ (0.5,0) [0|30.5] "Unit_LiterPerMinut"  Sub_Gateway,TME

BO_TX_BU_ 686 : DCDC_800V_PAG,DCDC_HV,LE_MLBevo;
BO_TX_BU_ 1012 : DCDC_800V_PAG,DCDC_HV,LE_MLBevo;
BO_TX_BU_ 1485 : DCDC_800V_PAG,DCDC_HV,LE_MLBevo;
BO_TX_BU_ 685 : DCDC_800V_PAG,DCDC_IHEV;
BO_TX_BU_ 1018 : DCDC_800V_PAG,DCDC_IHEV;
BO_TX_BU_ 1484 : DCDC_800V_PAG,DCDC_IHEV;
BO_TX_BU_ 2617238016 : DCDC_HV,LE_MLBevo,LE_MLBevo_LB;
BO_TX_BU_ 2617238271 : DCDC_HV,LE_MLBevo,LE_MLBevo_LB;
BO_TX_BU_ 2549880528 : Gateway,Gateway_PAG;
BO_TX_BU_ 2549880529 : Gateway,Gateway_PAG;
BO_TX_BU_ 2549880530 : Gateway,Gateway_PAG;
BO_TX_BU_ 2549880531 : Gateway,Gateway_PAG;
BO_TX_BU_ 2549880532 : Gateway,Gateway_PAG;
BO_TX_BU_ 2549880533 : Gateway,Gateway_PAG;
BO_TX_BU_ 2549880534 : Gateway,Gateway_PAG;
BO_TX_BU_ 2549880535 : Gateway,Gateway_PAG;
BO_TX_BU_ 2549880536 : Gateway,Gateway_PAG;
BO_TX_BU_ 2549880537 : Gateway,Gateway_PAG;
BO_TX_BU_ 2549880538 : Gateway,Gateway_PAG;
BO_TX_BU_ 2549880539 : Gateway,Gateway_PAG;
BO_TX_BU_ 2549880540 : Gateway,Gateway_PAG;
BO_TX_BU_ 2549880561 : Gateway,Gateway_PAG;
BO_TX_BU_ 2549880562 : Gateway,Gateway_PAG;
BO_TX_BU_ 2549880563 : Gateway,Gateway_PAG;
BO_TX_BU_ 2549880413 : Gateway,Gateway_PAG;
BO_TX_BU_ 2549880512 : Gateway,Gateway_PAG;
BO_TX_BU_ 2550011584 : FCU_MLBevo_FCEV,TME;
BO_TX_BU_ 1520 : Gateway,Gateway_PAG;
BO_TX_BU_ 1603 : Gateway,Gateway_PAG;
BO_TX_BU_ 910 : Gateway,Gateway_PAG,LE_MLBevo;
BO_TX_BU_ 135 : Gateway,Gateway_PAG;
BO_TX_BU_ 892 : Gateway,LE1,LE_MLBevo;
BO_TX_BU_ 115 : Gateway,Gateway_PAG;
BO_TX_BU_ 184 : Gateway,Gateway_PAG;
BO_TX_BU_ 1106 : Gateway,Gateway_PAG;
BO_TX_BU_ 2527679712 : Gateway,Gateway_PAG;
BO_TX_BU_ 2527679648 : Gateway,Gateway_PAG;
BO_TX_BU_ 273 : Gateway,Gateway_PAG;
BO_TX_BU_ 2463978615 : Gateway,Gateway_PAG,LE2;
CM_ SG_ 2589283856 DC_MV_Komponentenfehler_63 "Übertragung OBD relevanter Fehlerpfade vom Secondary zum Primary Steuergerät. 
Zuordnung der generischen Komponentenfehler muss zwischen Sender und Empfänger abgestimmt werden.";
CM_ SG_ 2589283856 DC_MV_Komponentenfehler_64 "Übertragung OBD relevanter Fehlerpfade vom Secondary zum Primary Steuergerät. 
Zuordnung der generischen Komponentenfehler muss zwischen Sender und Empfänger abgestimmt werden.";
CM_ SG_ 2589283856 DC_MV_Komponentenfehler_65 "Übertragung OBD relevanter Fehlerpfade vom Secondary zum Primary Steuergerät. 
Zuordnung der generischen Komponentenfehler muss zwischen Sender und Empfänger abgestimmt werden.";
CM_ SG_ 2589283856 DC_MV_Komponentenfehler_66 "Übertragung OBD relevanter Fehlerpfade vom Secondary zum Primary Steuergerät. 
Zuordnung der generischen Komponentenfehler muss zwischen Sender und Empfänger abgestimmt werden.";
CM_ SG_ 2589283856 DC_MV_Komponentenfehler_67 "Übertragung OBD relevanter Fehlerpfade vom Secondary zum Primary Steuergerät. 
Zuordnung der generischen Komponentenfehler muss zwischen Sender und Empfänger abgestimmt werden.";
CM_ SG_ 2589283856 DC_MV_Komponentenfehler_68 "Übertragung OBD relevanter Fehlerpfade vom Secondary zum Primary Steuergerät. 
Zuordnung der generischen Komponentenfehler muss zwischen Sender und Empfänger abgestimmt werden.";
CM_ SG_ 2589283856 DC_MV_Komponentenfehler_69 "Übertragung OBD relevanter Fehlerpfade vom Secondary zum Primary Steuergerät. 
Zuordnung der generischen Komponentenfehler muss zwischen Sender und Empfänger abgestimmt werden.";
CM_ SG_ 2589283856 DC_MV_Komponentenfehler_70 "Übertragung OBD relevanter Fehlerpfade vom Secondary zum Primary Steuergerät. 
Zuordnung der generischen Komponentenfehler muss zwischen Sender und Empfänger abgestimmt werden.";
CM_ SG_ 2589283856 DC_MV_Komponentenfehler_71 "Übertragung OBD relevanter Fehlerpfade vom Secondary zum Primary Steuergerät. 
Zuordnung der generischen Komponentenfehler muss zwischen Sender und Empfänger abgestimmt werden.";
CM_ SG_ 2589283856 DC_MV_Komponentenfehler_72 "Übertragung OBD relevanter Fehlerpfade vom Secondary zum Primary Steuergerät. 
Zuordnung der generischen Komponentenfehler muss zwischen Sender und Empfänger abgestimmt werden.";
CM_ SG_ 2589283856 DC_MV_Komponentenfehler_73 "Übertragung OBD relevanter Fehlerpfade vom Secondary zum Primary Steuergerät. 
Zuordnung der generischen Komponentenfehler muss zwischen Sender und Empfänger abgestimmt werden.";
CM_ SG_ 2589283856 DC_MV_Komponentenfehler_74 "Übertragung OBD relevanter Fehlerpfade vom Secondary zum Primary Steuergerät. 
Zuordnung der generischen Komponentenfehler muss zwischen Sender und Empfänger abgestimmt werden.";
CM_ SG_ 2589283856 DC_MV_Komponentenfehler_75 "Übertragung OBD relevanter Fehlerpfade vom Secondary zum Primary Steuergerät. 
Zuordnung der generischen Komponentenfehler muss zwischen Sender und Empfänger abgestimmt werden.";
CM_ SG_ 2589283856 DC_MV_Komponentenfehler_76 "Übertragung OBD relevanter Fehlerpfade vom Secondary zum Primary Steuergerät. 
Zuordnung der generischen Komponentenfehler muss zwischen Sender und Empfänger abgestimmt werden.";
CM_ SG_ 2589283856 DC_MV_Komponentenfehler_77 "Übertragung OBD relevanter Fehlerpfade vom Secondary zum Primary Steuergerät. 
Zuordnung der generischen Komponentenfehler muss zwischen Sender und Empfänger abgestimmt werden.";
CM_ SG_ 2589283856 DC_MV_Komponentenfehler_78 "Übertragung OBD relevanter Fehlerpfade vom Secondary zum Primary Steuergerät. 
Zuordnung der generischen Komponentenfehler muss zwischen Sender und Empfänger abgestimmt werden.";
CM_ SG_ 2589283856 DC_MV_Komponentenfehler_79 "Übertragung OBD relevanter Fehlerpfade vom Secondary zum Primary Steuergerät. 
Zuordnung der generischen Komponentenfehler muss zwischen Sender und Empfänger abgestimmt werden.";
CM_ SG_ 2589283856 DC_MV_Komponentenfehler_80 "Übertragung OBD relevanter Fehlerpfade vom Secondary zum Primary Steuergerät. 
Zuordnung der generischen Komponentenfehler muss zwischen Sender und Empfänger abgestimmt werden.";
CM_ SG_ 2589283856 DC_MV_Komponentenfehler_81 "Übertragung OBD relevanter Fehlerpfade vom Secondary zum Primary Steuergerät. 
Zuordnung der generischen Komponentenfehler muss zwischen Sender und Empfänger abgestimmt werden.";
CM_ SG_ 2589283856 DC_MV_Komponentenfehler_82 "Übertragung OBD relevanter Fehlerpfade vom Secondary zum Primary Steuergerät. 
Zuordnung der generischen Komponentenfehler muss zwischen Sender und Empfänger abgestimmt werden.";
CM_ SG_ 2589283856 DC_MV_Komponentenfehler_83 "Übertragung OBD relevanter Fehlerpfade vom Secondary zum Primary Steuergerät. 
Zuordnung der generischen Komponentenfehler muss zwischen Sender und Empfänger abgestimmt werden.";
CM_ SG_ 2589283856 DC_MV_Komponentenfehler_84 "Übertragung OBD relevanter Fehlerpfade vom Secondary zum Primary Steuergerät. 
Zuordnung der generischen Komponentenfehler muss zwischen Sender und Empfänger abgestimmt werden.";
CM_ SG_ 2589283856 DC_MV_Komponentenfehler_85 "Übertragung OBD relevanter Fehlerpfade vom Secondary zum Primary Steuergerät. 
Zuordnung der generischen Komponentenfehler muss zwischen Sender und Empfänger abgestimmt werden.";
CM_ SG_ 2589283856 DC_MV_Komponentenfehler_86 "Übertragung OBD relevanter Fehlerpfade vom Secondary zum Primary Steuergerät. 
Zuordnung der generischen Komponentenfehler muss zwischen Sender und Empfänger abgestimmt werden.";
CM_ SG_ 2589283856 DC_MV_Komponentenfehler_87 "Übertragung OBD relevanter Fehlerpfade vom Secondary zum Primary Steuergerät. 
Zuordnung der generischen Komponentenfehler muss zwischen Sender und Empfänger abgestimmt werden.";
CM_ SG_ 2589283856 DC_MV_Komponentenfehler_88 "Übertragung OBD relevanter Fehlerpfade vom Secondary zum Primary Steuergerät. 
Zuordnung der generischen Komponentenfehler muss zwischen Sender und Empfänger abgestimmt werden.";
CM_ SG_ 2589283856 DC_MV_Komponentenfehler_89 "Übertragung OBD relevanter Fehlerpfade vom Secondary zum Primary Steuergerät. 
Zuordnung der generischen Komponentenfehler muss zwischen Sender und Empfänger abgestimmt werden.";
CM_ SG_ 2589283856 DC_MV_Komponentenfehler_90 "Übertragung OBD relevanter Fehlerpfade vom Secondary zum Primary Steuergerät. 
Zuordnung der generischen Komponentenfehler muss zwischen Sender und Empfänger abgestimmt werden.";
CM_ SG_ 2589283856 DC_MV_Komponentenfehler_91 "Übertragung OBD relevanter Fehlerpfade vom Secondary zum Primary Steuergerät. 
Zuordnung der generischen Komponentenfehler muss zwischen Sender und Empfänger abgestimmt werden.";
CM_ SG_ 2589283856 DC_MV_Komponentenfehler_92 "Übertragung OBD relevanter Fehlerpfade vom Secondary zum Primary Steuergerät. 
Zuordnung der generischen Komponentenfehler muss zwischen Sender und Empfänger abgestimmt werden.";
CM_ SG_ 2589283856 DC_MV_Komponentenfehler_93 "Übertragung OBD relevanter Fehlerpfade vom Secondary zum Primary Steuergerät. 
Zuordnung der generischen Komponentenfehler muss zwischen Sender und Empfänger abgestimmt werden.";
CM_ SG_ 2589283857 DC_MV_Komponentenfehler_94 "Übertragung OBD relevanter Fehlerpfade vom Secondary zum Primary Steuergerät. 
Zuordnung der generischen Komponentenfehler muss zwischen Sender und Empfänger abgestimmt werden.";
CM_ SG_ 2589283857 DC_MV_Komponentenfehler_95 "Übertragung OBD relevanter Fehlerpfade vom Secondary zum Primary Steuergerät. 
Zuordnung der generischen Komponentenfehler muss zwischen Sender und Empfänger abgestimmt werden.";
CM_ SG_ 2589283857 DC_MV_Komponentenfehler_96 "Übertragung OBD relevanter Fehlerpfade vom Secondary zum Primary Steuergerät. 
Zuordnung der generischen Komponentenfehler muss zwischen Sender und Empfänger abgestimmt werden.";
CM_ SG_ 2589283857 DC_MV_Komponentenfehler_97 "Übertragung OBD relevanter Fehlerpfade vom Secondary zum Primary Steuergerät. 
Zuordnung der generischen Komponentenfehler muss zwischen Sender und Empfänger abgestimmt werden.";
CM_ SG_ 2589283857 DC_MV_Komponentenfehler_98 "Übertragung OBD relevanter Fehlerpfade vom Secondary zum Primary Steuergerät. 
Zuordnung der generischen Komponentenfehler muss zwischen Sender und Empfänger abgestimmt werden.";
CM_ SG_ 2589283857 DC_MV_Komponentenfehler_99 "Übertragung OBD relevanter Fehlerpfade vom Secondary zum Primary Steuergerät. 
Zuordnung der generischen Komponentenfehler muss zwischen Sender und Empfänger abgestimmt werden.";
CM_ SG_ 2589283857 DC_MV_Komponentenfehler_100 "Übertragung OBD relevanter Fehlerpfade vom Secondary zum Primary Steuergerät. 
Zuordnung der generischen Komponentenfehler muss zwischen Sender und Empfänger abgestimmt werden.";
CM_ SG_ 2589283857 DC_MV_Komponentenfehler_101 "Übertragung OBD relevanter Fehlerpfade vom Secondary zum Primary Steuergerät. 
Zuordnung der generischen Komponentenfehler muss zwischen Sender und Empfänger abgestimmt werden.";
CM_ SG_ 2589283857 DC_MV_Komponentenfehler_102 "Übertragung OBD relevanter Fehlerpfade vom Secondary zum Primary Steuergerät. 
Zuordnung der generischen Komponentenfehler muss zwischen Sender und Empfänger abgestimmt werden.";
CM_ SG_ 2589283857 DC_MV_Komponentenfehler_103 "Übertragung OBD relevanter Fehlerpfade vom Secondary zum Primary Steuergerät. 
Zuordnung der generischen Komponentenfehler muss zwischen Sender und Empfänger abgestimmt werden.";
CM_ SG_ 2589283857 DC_MV_Komponentenfehler_104 "Übertragung OBD relevanter Fehlerpfade vom Secondary zum Primary Steuergerät. 
Zuordnung der generischen Komponentenfehler muss zwischen Sender und Empfänger abgestimmt werden.";
CM_ SG_ 2589283857 DC_MV_Komponentenfehler_105 "Übertragung OBD relevanter Fehlerpfade vom Secondary zum Primary Steuergerät. 
Zuordnung der generischen Komponentenfehler muss zwischen Sender und Empfänger abgestimmt werden.";
CM_ SG_ 2589283857 DC_MV_Komponentenfehler_106 "Übertragung OBD relevanter Fehlerpfade vom Secondary zum Primary Steuergerät. 
Zuordnung der generischen Komponentenfehler muss zwischen Sender und Empfänger abgestimmt werden.";
CM_ SG_ 2589283857 DC_MV_Komponentenfehler_107 "Übertragung OBD relevanter Fehlerpfade vom Secondary zum Primary Steuergerät. 
Zuordnung der generischen Komponentenfehler muss zwischen Sender und Empfänger abgestimmt werden.";
CM_ SG_ 2589283857 DC_MV_Komponentenfehler_108 "Übertragung OBD relevanter Fehlerpfade vom Secondary zum Primary Steuergerät. 
Zuordnung der generischen Komponentenfehler muss zwischen Sender und Empfänger abgestimmt werden.";
CM_ SG_ 2589283857 DC_MV_Komponentenfehler_109 "Übertragung OBD relevanter Fehlerpfade vom Secondary zum Primary Steuergerät. 
Zuordnung der generischen Komponentenfehler muss zwischen Sender und Empfänger abgestimmt werden.";
CM_ SG_ 2589283857 DC_MV_Komponentenfehler_110 "Übertragung OBD relevanter Fehlerpfade vom Secondary zum Primary Steuergerät. 
Zuordnung der generischen Komponentenfehler muss zwischen Sender und Empfänger abgestimmt werden.";
CM_ SG_ 2589283857 DC_MV_Komponentenfehler_111 "Übertragung OBD relevanter Fehlerpfade vom Secondary zum Primary Steuergerät. 
Zuordnung der generischen Komponentenfehler muss zwischen Sender und Empfänger abgestimmt werden.";
CM_ SG_ 2589283857 DC_MV_Komponentenfehler_112 "Übertragung OBD relevanter Fehlerpfade vom Secondary zum Primary Steuergerät. 
Zuordnung der generischen Komponentenfehler muss zwischen Sender und Empfänger abgestimmt werden.";
CM_ SG_ 2589283857 DC_MV_Komponentenfehler_113 "Übertragung OBD relevanter Fehlerpfade vom Secondary zum Primary Steuergerät. 
Zuordnung der generischen Komponentenfehler muss zwischen Sender und Empfänger abgestimmt werden.";
CM_ SG_ 2589283857 DC_MV_Komponentenfehler_114 "Übertragung OBD relevanter Fehlerpfade vom Secondary zum Primary Steuergerät. 
Zuordnung der generischen Komponentenfehler muss zwischen Sender und Empfänger abgestimmt werden.";
CM_ SG_ 2589283857 DC_MV_Komponentenfehler_115 "Übertragung OBD relevanter Fehlerpfade vom Secondary zum Primary Steuergerät. 
Zuordnung der generischen Komponentenfehler muss zwischen Sender und Empfänger abgestimmt werden.";
CM_ SG_ 2589283857 DC_MV_Komponentenfehler_116 "Übertragung OBD relevanter Fehlerpfade vom Secondary zum Primary Steuergerät. 
Zuordnung der generischen Komponentenfehler muss zwischen Sender und Empfänger abgestimmt werden.";
CM_ SG_ 2589283857 DC_MV_Komponentenfehler_117 "Übertragung OBD relevanter Fehlerpfade vom Secondary zum Primary Steuergerät. 
Zuordnung der generischen Komponentenfehler muss zwischen Sender und Empfänger abgestimmt werden.";
CM_ SG_ 2589283857 DC_MV_Komponentenfehler_118 "Übertragung OBD relevanter Fehlerpfade vom Secondary zum Primary Steuergerät. 
Zuordnung der generischen Komponentenfehler muss zwischen Sender und Empfänger abgestimmt werden.";
CM_ SG_ 2589283857 DC_MV_Komponentenfehler_119 "Übertragung OBD relevanter Fehlerpfade vom Secondary zum Primary Steuergerät. 
Zuordnung der generischen Komponentenfehler muss zwischen Sender und Empfänger abgestimmt werden.";
CM_ SG_ 2589283857 DC_MV_Komponentenfehler_120 "Übertragung OBD relevanter Fehlerpfade vom Secondary zum Primary Steuergerät. 
Zuordnung der generischen Komponentenfehler muss zwischen Sender und Empfänger abgestimmt werden.";
CM_ SG_ 2589283857 DC_MV_Komponentenfehler_121 "Übertragung OBD relevanter Fehlerpfade vom Secondary zum Primary Steuergerät. 
Zuordnung der generischen Komponentenfehler muss zwischen Sender und Empfänger abgestimmt werden.";
CM_ SG_ 2589283857 DC_MV_Komponentenfehler_122 "Übertragung OBD relevanter Fehlerpfade vom Secondary zum Primary Steuergerät. 
Zuordnung der generischen Komponentenfehler muss zwischen Sender und Empfänger abgestimmt werden.";
CM_ SG_ 2589283857 DC_MV_Komponentenfehler_123 "Übertragung OBD relevanter Fehlerpfade vom Secondary zum Primary Steuergerät. 
Zuordnung der generischen Komponentenfehler muss zwischen Sender und Empfänger abgestimmt werden.";
CM_ SG_ 2589283857 DC_MV_Komponentenfehler_124 "Übertragung OBD relevanter Fehlerpfade vom Secondary zum Primary Steuergerät. 
Zuordnung der generischen Komponentenfehler muss zwischen Sender und Empfänger abgestimmt werden.";
CM_ SG_ 2589283858 DC_MV_Komponentenfehler_125 "Übertragung OBD relevanter Fehlerpfade vom Secondary zum Primary Steuergerät. 
Zuordnung der generischen Komponentenfehler muss zwischen Sender und Empfänger abgestimmt werden.";
CM_ SG_ 2589283858 DC_MV_Komponentenfehler_126 "Übertragung OBD relevanter Fehlerpfade vom Secondary zum Primary Steuergerät. 
Zuordnung der generischen Komponentenfehler muss zwischen Sender und Empfänger abgestimmt werden.";
CM_ SG_ 2589283858 DC_MV_Komponentenfehler_127 "Übertragung OBD relevanter Fehlerpfade vom Secondary zum Primary Steuergerät. 
Zuordnung der generischen Komponentenfehler muss zwischen Sender und Empfänger abgestimmt werden.";
CM_ SG_ 2589283858 DC_MV_Komponentenfehler_128 "Übertragung OBD relevanter Fehlerpfade vom Secondary zum Primary Steuergerät. 
Zuordnung der generischen Komponentenfehler muss zwischen Sender und Empfänger abgestimmt werden.";
CM_ SG_ 2589283858 DC_MV_Komponentenfehler_129 "Übertragung OBD relevanter Fehlerpfade vom Secondary zum Primary Steuergerät. 
Zuordnung der generischen Komponentenfehler muss zwischen Sender und Empfänger abgestimmt werden.";
CM_ SG_ 2589283858 DC_MV_Komponentenfehler_130 "Übertragung OBD relevanter Fehlerpfade vom Secondary zum Primary Steuergerät. 
Zuordnung der generischen Komponentenfehler muss zwischen Sender und Empfänger abgestimmt werden.";
CM_ SG_ 2589283858 DC_MV_Komponentenfehler_131 "Übertragung OBD relevanter Fehlerpfade vom Secondary zum Primary Steuergerät. 
Zuordnung der generischen Komponentenfehler muss zwischen Sender und Empfänger abgestimmt werden.";
CM_ SG_ 2589283858 DC_MV_Komponentenfehler_132 "Übertragung OBD relevanter Fehlerpfade vom Secondary zum Primary Steuergerät. 
Zuordnung der generischen Komponentenfehler muss zwischen Sender und Empfänger abgestimmt werden.";
CM_ SG_ 2589283858 DC_MV_Komponentenfehler_133 "Übertragung OBD relevanter Fehlerpfade vom Secondary zum Primary Steuergerät. 
Zuordnung der generischen Komponentenfehler muss zwischen Sender und Empfänger abgestimmt werden.";
CM_ SG_ 2589283858 DC_MV_Komponentenfehler_134 "Übertragung OBD relevanter Fehlerpfade vom Secondary zum Primary Steuergerät. 
Zuordnung der generischen Komponentenfehler muss zwischen Sender und Empfänger abgestimmt werden.";
CM_ SG_ 2589283858 DC_MV_Komponentenfehler_135 "Übertragung OBD relevanter Fehlerpfade vom Secondary zum Primary Steuergerät. 
Zuordnung der generischen Komponentenfehler muss zwischen Sender und Empfänger abgestimmt werden.";
CM_ SG_ 2589283858 DC_MV_Komponentenfehler_136 "Übertragung OBD relevanter Fehlerpfade vom Secondary zum Primary Steuergerät. 
Zuordnung der generischen Komponentenfehler muss zwischen Sender und Empfänger abgestimmt werden.";
CM_ SG_ 2589283858 DC_MV_Komponentenfehler_137 "Übertragung OBD relevanter Fehlerpfade vom Secondary zum Primary Steuergerät. 
Zuordnung der generischen Komponentenfehler muss zwischen Sender und Empfänger abgestimmt werden.";
CM_ SG_ 2589283858 DC_MV_Komponentenfehler_138 "Übertragung OBD relevanter Fehlerpfade vom Secondary zum Primary Steuergerät. 
Zuordnung der generischen Komponentenfehler muss zwischen Sender und Empfänger abgestimmt werden.";
CM_ SG_ 2589283858 DC_MV_Komponentenfehler_139 "Übertragung OBD relevanter Fehlerpfade vom Secondary zum Primary Steuergerät. 
Zuordnung der generischen Komponentenfehler muss zwischen Sender und Empfänger abgestimmt werden.";
CM_ SG_ 2589283858 DC_MV_Komponentenfehler_140 "Übertragung OBD relevanter Fehlerpfade vom Secondary zum Primary Steuergerät. 
Zuordnung der generischen Komponentenfehler muss zwischen Sender und Empfänger abgestimmt werden.";
CM_ SG_ 2589283858 DC_MV_Komponentenfehler_141 "Übertragung OBD relevanter Fehlerpfade vom Secondary zum Primary Steuergerät. 
Zuordnung der generischen Komponentenfehler muss zwischen Sender und Empfänger abgestimmt werden.";
CM_ SG_ 2589283858 DC_MV_Komponentenfehler_142 "Übertragung OBD relevanter Fehlerpfade vom Secondary zum Primary Steuergerät. 
Zuordnung der generischen Komponentenfehler muss zwischen Sender und Empfänger abgestimmt werden.";
CM_ SG_ 2589283858 DC_MV_Komponentenfehler_143 "Übertragung OBD relevanter Fehlerpfade vom Secondary zum Primary Steuergerät. 
Zuordnung der generischen Komponentenfehler muss zwischen Sender und Empfänger abgestimmt werden.";
CM_ SG_ 2589283858 DC_MV_Komponentenfehler_144 "Übertragung OBD relevanter Fehlerpfade vom Secondary zum Primary Steuergerät. 
Zuordnung der generischen Komponentenfehler muss zwischen Sender und Empfänger abgestimmt werden.";
CM_ SG_ 2589283858 DC_MV_Komponentenfehler_145 "Übertragung OBD relevanter Fehlerpfade vom Secondary zum Primary Steuergerät. 
Zuordnung der generischen Komponentenfehler muss zwischen Sender und Empfänger abgestimmt werden.";
CM_ SG_ 686 DCDC_01_CRC "Für MLB:
'Berechnung siehe Lastenheft 'Kommunikationsabsicherung für FlexRay und CAN''

Ab MQB und MLBevo:
'Berechnung siehe Lastenheft 'End-to-End Kommunikationsabsicherung''

Endwerte siehe Begleitdokument 'S-PDU Kennungsfolgen'";
CM_ SG_ 686 DC_IstSpannung_HV "Momentanwert:  Hochspannung am DC/DC Wandler";
CM_ SG_ 686 DC_IstStrom_HV_02 "Aktueller Strom des DC/DC-Wandlers Höherspannungsseitig.

Tiefsetzen - positiv
Hochsetzen - negativ";
CM_ SG_ 686 DC_IstStrom_NV "Momentanwert: Strom vom DC/DC in das Bordnetz
Tiefsetzen - positiv
Hochsetzen - negativ";
CM_ SG_ 686 DC_IstSpannung_NV "Momentanwert: Bordnetzspannung am DC/DC Wandler";
CM_ SG_ 1012 DCDC_02_CRC "Für MLB:
'Berechnung siehe Lastenheft 'Kommunikationsabsicherung für FlexRay und CAN''

Ab MQB und MLBevo:
'Berechnung siehe Lastenheft 'End-to-End Kommunikationsabsicherung''

Endwerte siehe Begleitdokument 'S-PDU Kennungsfolgen'";
CM_ SG_ 1012 DC_HYB_iAktReserveLV "Momentanwert: Stromreserve vom DC/DC-Wandler in Richtung 12V-Bordnetz
Im MLBevo nur positiver Bereich genutzt

Tiefsetzen - positiv
Hochsetzen - negativ";
CM_ SG_ 1012 DC_Verbrauch_Ueberlauf "Überlauf-Bit für das Signal DC_Verbrauch";
CM_ SG_ 1012 DC_Verbrauch "Energieverbrauch vom DCDC für Versorgung 12V-Bordnetz inkl. seines eigenen Wirkungsgrads (bspw.: HV_Strom*HV_Spannung*t)";
CM_ SG_ 1012 DC_Verlustleistung "Aktuelle Verlustleistung des DC/DC-Wandlers.";
CM_ SG_ 1012 DC_HYB_Auslastungsgrad "Momentanwert: Auslastung DC/DC (DFM Signal), entspricht I_akt / I_max
(Vorhalt für MQB)";
CM_ SG_ 1485 DCDC_03_CRC "Für MLB:
'Berechnung siehe Lastenheft 'Kommunikationsabsicherung für FlexRay und CAN''

Ab MQB und MLBevo:
'Berechnung siehe Lastenheft 'End-to-End Kommunikationsabsicherung''

Endwerte siehe Begleitdokument 'S-PDU Kennungsfolgen'";
CM_ SG_ 1485 DC_Fehlerstatus "aktueller Fehlerstatus des DCDC-Wandler:";
CM_ SG_ 1485 DC_Peakstrom_verfuegbar "Peakstrom verfügbar/nicht verfügbar";
CM_ SG_ 1485 DC_Abregelung_Temperatur "Abregelung aufgrund Übertemperatur im Leistungsteil (Hochtemperatur-Abregelung)";
CM_ SG_ 1485 DC_IstModus_02 "aktuelle Betriebsart des DC/DC Wandlers;
0: Standby; Kommunikation aktiv
1: HV_On_Vorladen
2: Tiefsetzen
3: Hochsetzen
4: Pruefimpuls_12V
5: interner Fehler DC/DC-Wandler / angeforderter Sollmodus kann nicht eingestellt werden
6: reserve
7: Initia";
CM_ SG_ 1485 DC_HV_EKK_IstModus "Aktuelle Betriebsart des DC/DC Wandlers 800V/400V;
0: Standby
1: Reserve
2: Tiefsetzen
3: Hochsetzen
4: Reserve
5: Fehler
6: Reserve
7: Initialisierung";
CM_ SG_ 1485 DC_Status_Spgfreiheit_HV "HV DC/DC-Wandler Status HV-Spannungsfreiheit";
CM_ SG_ 1485 DC_IstSpannung_EKK_HV "Ausgangsspannung des Kombiwandlers am 400V-Anschluss";
CM_ SG_ 1485 DC_Temperatur "Momentanwert: Temperatur des DC/DC Wandlers";
CM_ SG_ 2527679744 DCDC_FC_IstModus "Ist-Modus des DCDC_FC";
CM_ SG_ 2527679744 DCDC_FC_Abschaltung_Ges "BZW schaltet sofort ab und fordert die Abschaltung des Gesamtsystems.";
CM_ SG_ 2527679744 DCDC_FC_Abschaltung_Prim "BZW schaltet sofort ab und fordert die Abschaltung des primären HV-Netzes.";
CM_ SG_ 2527679744 DCDC_FC_Anf_Abschaltung_Ges "BZW ist noch aktiv und fordert die Abschaltung des Gesamtsystems.";
CM_ SG_ 2527679744 DCDC_FC_Anf_Abschaltung_Prim "BZW ist noch aktiv und fordert die Abschaltung des primären HV-Netzes.";
CM_ SG_ 2527679744 DCDC_FC_Begrenz_MaxSpannung_Prim "Begrenzung aufgrund Überschreitung der vorgegebenen maximalen Eingangsspannung.";
CM_ SG_ 2527679744 DCDC_FC_Begrenz_MaxSpannung_Sek "Begrenzung aufgrund Überschreitung der vorgegebenen maximalen Ausgangsspannung.";
CM_ SG_ 2527679744 DCDC_FC_Begrenz_MaxStrom_Prim "Begrenzung aufgrund Überschreitung des vorgegebenen maximalen Eingangsstroms.";
CM_ SG_ 2527679744 DCDC_FC_Begrenz_MaxStrom_Sek "Begrenzung aufgrund Überschreitung des vorgegebenen maximalen Ausgangsstroms.";
CM_ SG_ 2527679744 DCDC_FC_Begrenz_MinSpannung_Prim "Begrenzung aufgrund Unterschreitung der vorgegebenen minimalen Eingangsspannung.";
CM_ SG_ 2527679744 DCDC_FC_Begrenz_MinSpannung_Sek "Begrenzung aufgrund Unterschreitung der vorgegebenen minimalen Ausgangsspannung.";
CM_ SG_ 2527679744 DCDC_FC_Begrenz_MinStrom_Prim "Begrenzung aufgrund Unterschreitung des vorgegebenen minimalen Eingangsstroms.";
CM_ SG_ 2527679744 DCDC_FC_Begrenz_Temp "Begrenzung aufgrund Überschreitung BZW-interner Temperaturgrenzen";
CM_ SG_ 2527679744 DCDC_FC_Diodenbetrieb "Diodenbetrieb des DCDC_FC, ungereglter Stromfluss über die Diode";
CM_ SG_ 2527679744 DCDC_FC_Fehlerstatus "Fehlerstatus des DCDC_FC";
CM_ SG_ 2527679744 DCDC_FC_Status_HVSwitch "Status der HV-Schaltelemente im BZW zur Abtrennung des Brennstoffzellenstacks";
CM_ SG_ 2527679744 DCDC_FC_Status_Interlock "Status Signal Interlock";
CM_ SG_ 2527679744 DCDC_FC_Status_Isowaechter_Netz2 "Status des Isowächters im DCDC_FC";
CM_ SG_ 2527679744 DCDC_FC_Status_Kl15c "Status Signal Kl15c";
CM_ SG_ 2527679744 DCDC_FC_Status_Kl30C "Status Signal Kl30C";
CM_ SG_ 2527679744 DCDC_FC_Temperatur "Ist-Temperatur des DCDC_FC";
CM_ SG_ 2589283653 DCDC_HV_02_01_CRC "Für MLB:
Berechnung siehe Lastenheft 'Kommunikationsabsicherung für FlexRay und CAN'
Ab MQB und MLBevo:
Berechnung siehe Lastenheft 'End-to-End Kommunikationsabsicherung'

Endwerte siehe Begleitdokument 'S-PDU Kennungsfolgen'";
CM_ SG_ 2589283653 DCDC_HV_02_01_BZ "4bit Botschaftszähler, wird mit jeder Sendebotschaft inkrementiert";
CM_ SG_ 2589283653 HVLB_IstModus_TN1 "Rueckmeldung Istmodus der Steuereinheit für das Schuetz des Teilnetz1 'Ladepfad':
0 : HV_Off                                
1 : HV_On (Schuetz geschlossen)                
2 : Fehler
3 : Init   (CAN-Initialisierung)";
CM_ SG_ 2589283653 HVLB_IstSpannung_DCLS "HV-Lade-Booster IstSpannung DC-Ladesäule";
CM_ SG_ 2589283653 HVLB_StatusSpgfreiheit_HV "HV-Lade-Booster Status HV-Spannungsfreiheit";
CM_ SG_ 2589283653 HVLB_IstModus "IstModus HV-Lade-Booster";
CM_ SG_ 2589283653 HVLB_IstStrom_HVHS "HV-Lade-Booster IstStrom Ausgangsseite";
CM_ SG_ 2589283653 HVLB_IstSpannung_HVHS "HV-Lade-Booster IstSpannung Ausgangsseite";
CM_ SG_ 2589283653 HVLB_DC_Laden_ohneBoost_verfuegb "Status DC-Laden ohne Booster";
CM_ SG_ 2589283653 HVLB_DC_Laden_mitBoost_verfuegb "Status DC-Laden mit Booster";
CM_ SG_ 2589283653 HVLB_AC_Laden_verfuegbar "Status Verfügbarkeit AC-Laden , Freigabe Schützansteuerung";
CM_ SG_ 2589283653 HVLB_Warnzustand "Warnzustand HV-Lade-Booster";
CM_ SG_ 2589283653 HVLB_Fehlerstatus "Fehlerstatus HV-Booster";
CM_ SG_ 2463978669 DCDC_HV_02_02_CRC "Für MLB:
Berechnung siehe Lastenheft 'Kommunikationsabsicherung für FlexRay und CAN'
Ab MQB und MLBevo:
Berechnung siehe Lastenheft 'End-to-End Kommunikationsabsicherung'

Endwerte siehe Begleitdokument 'S-PDU Kennungsfolgen'";
CM_ SG_ 2463978669 DCDC_HV_02_02_BZ "4bit Botschaftszähler, wird mit jeder Sendebotschaft inkrementiert";
CM_ SG_ 2463978669 HVLB_Temperatur "HV-Lade-Booster Temperatur";
CM_ SG_ 2463978669 HVLB_IstSpannung_HVLS "HV-Lade-Booster IstSpannung Eingangsseite";
CM_ SG_ 2463978669 HVLB_MaxDynStrom_HVLS "HV-Lade Booster, maximal zulässiger Strom Eingangsseite";
CM_ SG_ 2589283662 HVLB_PlanAntw_Verlustleistung "Antwort auf die Ladeplan-Anfrage für die Ladeplanung: Verlustleistung";
CM_ SG_ 2589283662 HVLB_PlanAntw_Zaehler "Antwort auf die Ladeplan-Anfrage für die Ladeplanung: Zähler";
CM_ SG_ 685 DCDC_MV_01_CRC "Für MLB:
Berechnung siehe Lastenheft 'Kommunikationsabsicherung für FlexRay und CAN'
Ab MQB und MLBevo:
Berechnung siehe Lastenheft 'End-to-End Kommunikationsabsicherung'

Endwerte siehe Begleitdokument 'S-PDU Kennungsfolgen'";
CM_ SG_ 685 DCDC_MV_01_BZ "4bit Botschaftszähler, wird mit jeder Sendebotschaft inkrementiert";
CM_ SG_ 685 DC_MV_IstSpannung_MV "Momentanwert:  Hochspannung am DC/DC Wandler";
CM_ SG_ 685 DC_MV_IstStrom_MV "Aktueller Strom des DC/DC-Wandlers Höherspannungsseitig.

Tiefsetzen - positiv
Hochsetzen - negativ";
CM_ SG_ 685 DC_MV_IstStrom_NV "Momentanwert: Strom vom DC/DC in das Bordnetz
Tiefsetzen - positiv
Hochsetzen - negativ";
CM_ SG_ 685 DC_MV_IstSpannung_NV "Momentanwert: Bordnetzspannung am DC/DC Wandler";
CM_ SG_ 1018 DCDC_MV_02_CRC "Für MLB:
Berechnung siehe Lastenheft 'Kommunikationsabsicherung für FlexRay und CAN'
Ab MQB und MLBevo:
Berechnung siehe Lastenheft 'End-to-End Kommunikationsabsicherung'

Endwerte siehe Begleitdokument 'S-PDU Kennungsfolgen'";
CM_ SG_ 1018 DCDC_MV_02_BZ "4bit Botschaftszähler, wird mit jeder Sendebotschaft inkrementiert";
CM_ SG_ 1018 DC_MV_akt_Stromreserve_NV "Momentanwert: Stromreserve vom DC/DC-Wandler in Richtung 12V-Bordnetz
Im MLBevo nur positiver Bereich genutzt

Tiefsetzen - positiv
Hochsetzen - negativ";
CM_ SG_ 1018 DC_MV_MaxStrom_MV "Momentanwert: maximaler Strom vom DC/DC-Wandler in Richtung MV-Bordnetz;
abhängig von Eingangsspannung und BT-Temperatur";
CM_ SG_ 1018 DC_MV_Auslastungsgrad "Momentanwert: Auslastung DC/DC (DFM Signal), entspricht I_aktuell / I_verfügbar * 100%";
CM_ SG_ 1484 DCDC_MV_03_CRC "Für MLB:
Berechnung siehe Lastenheft 'Kommunikationsabsicherung für FlexRay und CAN'
Ab MQB und MLBevo:
Berechnung siehe Lastenheft 'End-to-End Kommunikationsabsicherung'

Endwerte siehe Begleitdokument 'S-PDU Kennungsfolgen'";
CM_ SG_ 1484 DCDC_MV_03_BZ "4bit Botschaftszähler, wird mit jeder Sendebotschaft inkrementiert";
CM_ SG_ 1484 DCDC_MV_Peakstrom_verfuegbar "Peakstrom verfügbar/nicht verfügbar";
CM_ SG_ 1484 DC_MV_Tiefsetzen_Notbetrieb "DCDC-Wandler arbeitet im Notbetrieb; ungeregelter Betrieb mit festem Tastverhältnis";
CM_ SG_ 1484 DC_MV_Fehlerstatus "aktueller Fehlerstatus des DCDC-Wandler:";
CM_ SG_ 1484 DC_MV_12V_Bordnetzstuetzung "DC/DC-Wandler befindet sich im Betriebsmodus Bordnetzstützung";
CM_ SG_ 1484 DC_MV_Abregelung_Temperatur "Abregelung aufgrund Übertemperatur im Leistungsteil (Hochtemperatur-Abregelung)";
CM_ SG_ 1484 DC_MV_IstModus "aktuelle Betriebsart des DC/DC Wandlers;";
CM_ SG_ 1484 DC_MV_IstModus_02 "aktuelle Betriebsart des DC/DC Wandlers";
CM_ SG_ 1484 DC_MV_Dyn_MinSpannung "Spannungsgrenze, um eine Leistungsbeschränkung des eAWS-Systems in einem speicherlosen 48V-Netz durchführen zu können";
CM_ SG_ 1484 DC_MV_Dyn_MaxSpannung "Spannungsgrenze, um eine Leistungsbeschränkung des eAWS-Systems in einem speicherlosen 48V-Netz durchführen zu können";
CM_ SG_ 1484 DC_MV_Temperatur "Momentanwert: Temperatur des DC/DC Wandlers";
CM_ SG_ 2549880528 DIA_BJB_Req_Data "Diagnosezugriff & Flashen Batterie Junction Box";
CM_ SG_ 2550011600 DIA_BJB_Resp_Data "Diagnosezugriff & Flashen Batterie Junction Box";
CM_ SG_ 2549880529 DIA_CMC_01_Req_Data "Diagnosezugriff & Flashen Cell Module Controller";
CM_ SG_ 2550011601 DIA_CMC_01_Resp_Data "Diagnosezugriff & Flashen Cell Module Controller";
CM_ SG_ 2549880530 DIA_CMC_02_Req_Data "Diagnosezugriff & Flashen Cell Module Controller";
CM_ SG_ 2550011602 DIA_CMC_02_Resp_Data "Diagnosezugriff & Flashen Cell Module Controller";
CM_ SG_ 2549880531 DIA_CMC_03_Req_Data "Diagnosezugriff & Flashen Cell Module Controller";
CM_ SG_ 2550011603 DIA_CMC_03_Resp_Data "Diagnosezugriff & Flashen Cell Module Controller";
CM_ SG_ 2549880532 DIA_CMC_04_Req_Data "Diagnosezugriff & Flashen Cell Module Controller";
CM_ SG_ 2550011604 DIA_CMC_04_Resp_Data "Diagnosezugriff & Flashen Cell Module Controller";
CM_ SG_ 2549880533 DIA_CMC_05_Req_Data "Diagnosezugriff & Flashen Cell Module Controller";
CM_ SG_ 2550011605 DIA_CMC_05_Resp_Data "Diagnosezugriff & Flashen Cell Module Controller";
CM_ SG_ 2549880534 DIA_CMC_06_Req_Data "Diagnosezugriff & Flashen Cell Module Controller";
CM_ SG_ 2550011606 DIA_CMC_06_Resp_Data "Diagnosezugriff & Flashen Cell Module Controller";
CM_ SG_ 2549880535 DIA_CMC_07_Req_Data "Diagnosezugriff & Flashen Cell Module Controller";
CM_ SG_ 2550011607 DIA_CMC_07_Resp_Data "Diagnosezugriff & Flashen Cell Module Controller";
CM_ SG_ 2549880536 DIA_CMC_08_Req_Data "Diagnosezugriff & Flashen Cell Module Controller";
CM_ SG_ 2550011608 DIA_CMC_08_Resp_Data "Diagnosezugriff & Flashen Cell Module Controller";
CM_ SG_ 2549880537 DIA_CMC_09_Req_Data "Diagnosezugriff & Flashen Cell Module Controller";
CM_ SG_ 2550011609 DIA_CMC_09_Resp_Data "Diagnosezugriff & Flashen Cell Module Controller";
CM_ SG_ 2549880538 DIA_CMC_10_Req_Data "Diagnosezugriff & Flashen Cell Module Controller";
CM_ SG_ 2550011610 DIA_CMC_10_Resp_Data "Diagnosezugriff & Flashen Cell Module Controller";
CM_ SG_ 2549880539 DIA_CMC_11_Req_Data "Diagnosezugriff & Flashen Cell Module Controller";
CM_ SG_ 2550011611 DIA_CMC_11_Resp_Data "Diagnosezugriff & Flashen Cell Module Controller";
CM_ SG_ 2549880540 DIA_CMC_12_Req_Data "Diagnosezugriff & Flashen Cell Module Controller";
CM_ SG_ 2550011612 DIA_CMC_12_Resp_Data "Diagnosezugriff & Flashen Cell Module Controller";
CM_ SG_ 2549880561 DIA_CMC_13_Req_Data "Diagnosezugriff & Flashen Cell Module Controller";
CM_ SG_ 2550011633 DIA_CMC_13_Resp_Data "Diagnosezugriff & Flashen Cell Module Controller";
CM_ SG_ 2549880562 DIA_CMC_14_Req_Data "Diagnosezugriff & Flashen Cell Module Controller";
CM_ SG_ 2550011634 DIA_CMC_14_Resp_Data "Diagnosezugriff & Flashen Cell Module Controller";
CM_ SG_ 2549880563 DIA_CMC_15_Req_Data "Diagnosezugriff & Flashen Cell Module Controller";
CM_ SG_ 2550011635 DIA_CMC_15_Resp_Data "Diagnosezugriff & Flashen Cell Module Controller";
CM_ SG_ 2549880717 DIA_eBooster2_Req_Data "Diagnosezugriff & Flashen Turbolader mit HV-Elektroantrieb";
CM_ SG_ 2550011789 DIA_eBooster2_Resp_Data "Diagnosezugriff & Flashen Turbolader mit HV-Elektroantrieb";
CM_ SG_ 2549880413 DIA_EKK_Req_Data "Diagnosezugriff & Flashen elektrischer Klimakompressor";
CM_ SG_ 2550011485 DIA_EKK_Resp_Data "Diagnosezugriff & Flashen elektrischer Klimakompressor";
CM_ SG_ 2549880512 DIA_HV_H2_Req_Data "Diagnosezugriff & Flashen Hochvolt Wasserheizer";
CM_ SG_ 2550011584 DIA_HV_H2_Resp_Data "Diagnosezugriff & Flashen Hochvolt Wasserheizer";
CM_ SG_ 2549880714 DIA_PumpKM_2_Req_Data "Diagnosezugriff & Flashen Pumpe 2 für Kühlmittel";
CM_ SG_ 2550011786 DIA_PumpKM_2_Resp_Data "Diagnosezugriff & Flashen Pumpe 2 für Kühlmittel";
CM_ SG_ 2549880570 DIA_PumpWSt_Req_Data "Diagnosezugriff & Flashen Pumpe für Wasserstoff";
CM_ SG_ 2550011642 DIA_PumpWSt_Resp_Data "Diagnosezugriff & Flashen Pumpe für Wasserstoff";
CM_ BO_ 1520 "ab MQB nach abgestimmten FLH Dimmung";
CM_ SG_ 1520 DI_KL_58xd "Klemme 58xd Display- und Funktionsbeleuchtung
Mit der Klemme 58xd wird die Helligkeit der Display- und der Funktionsbeleuchtungen der Schalter gesteuert.
Im Detail beschrieben im 'Funktionslastenheft Dimmung MQB'.";
CM_ SG_ 1520 DI_KL_58xs "Suchbeleuchtung Schalter
EIN-AUS-Schaltalgorithmus der allgemeinen Schaltersuchbeleuchtung. 
Im Detail beschrieben im 'Funktionslastenheft Dimmung MQB'.
";
CM_ SG_ 1520 DI_Display_Nachtdesign "Für Displays sind oft  automatische Umschaltungen von Tag-/Nachtdesign vorgesehen.
Es gibt jedoch Zustände, an denen auch tagsüber das Abblendlicht eingeschaltet ist.
z.B. Dauerfahrlicht, Geschwindigkeitsabhängiges 'Licht-An-Bei-Autobahn', 'Regenlicht',";
CM_ SG_ 1520 DI_KL_58xt "Timergesteuerte Suchbeleuchtung
Der EIN-AUS-Schaltalgorithmus für die vor- und nachlaufende Schaltersuchbeleuchtungen beim Ein- & Aussteigen; z.B.: Start/Stop-Taster.
Im Detail beschrieben im 'Funktionslastenheft Dimmung MQB'.";
CM_ SG_ 1520 DI_Fotosensor "Helligkeitswert Fotosensor
Für die Dimmung relevanter Wert zur Sensierung der Umgebungshelligkeit
Im Detail beschrieben im 'Funktionslastenheft Dimmung MQB'.";
CM_ SG_ 1520 BCM1_Stellgroesse_Kl_58s "Rohwert Dimmpoti";
CM_ BO_ 1603 "ab MQB mit 8 Byte";
CM_ SG_ 1603 KBI_Einheit_Datum "Anzeigevariante des Datums";
CM_ SG_ 1603 KBI_Einheit_Druck "Einheit des Druckes";
CM_ SG_ 1603 KBI_Einheit_Streckenanz "Einheit der Streckenanzeige";
CM_ SG_ 1603 KBI_MFA_v_Einheit_02 "Einheit der Geschwindigkeit, die vom Fahrer im Car-Menü gewählt wurde. Veränderliche Grösse, im Gegensatz zur Einheit des Tachokranzes.

Redundant in der Einheiten_01 Botschaft definiert, um Konsistenz zur BAP-Festlegung zu haben.";
CM_ SG_ 1603 KBI_Einheit_Temp "Einheit der Temperatur";
CM_ SG_ 1603 KBI_Einheit_Uhrzeit "Anzeigevariante der Uhrzeit";
CM_ SG_ 1603 KBI_Einheit_Verbrauch "Einheit der Verbrauchs";
CM_ SG_ 1603 KBI_Einheit_Volumen "Einheit des Volumens";
CM_ SG_ 1603 KBI_Einheit_Verbrauch_elektr "Einheit elektrischer Verbrauch";
CM_ SG_ 1603 KBI_Einheit_Sprache "Siehe BAP-Datenfestlegung UnitMaster";
CM_ SG_ 1603 KBI_Einheit_Verbrauch_Gas "Unterscheidung zwischen M3/h und kg/h für Komfortverbrauchsberechnung.";
CM_ SG_ 1603 KBI_Einheit_Masse "Einheit der Masse (Verwendung z.B. ASTA)";
CM_ BO_ 910 "CAN-Botschaft";
CM_ SG_ 910 EM1_OBD_Lampe_Anf "In allen VW-/Audi-Fahrzeugen ist ein MIL-Master-Konzept umgesetzt. Dazu ermittelt jedes OBD-Steuergerät den eigenen MIL-Status. Eine MIL-Ansteuerung wird vom betroffenen OBD-Steuergerät per MIL-Request über CAN an den MIL-Master weitergegeben. Der MIL-Mas";
CM_ SG_ 910 EM1_FoD_Freischaltstatus_Fkt1 "zeigt den Status der FoD-Freischaltung für das Performanz Paket an";
CM_ SG_ 910 EM1_Temperatur_ElMotor "Momentanwert: Temperatur der E-Maschine";
CM_ SG_ 910 EM1_Temperatur_PWR "Momentanwert: Temperatur des PWR";
CM_ SG_ 910 EM1_Temperatur_Rotor "Momentanwert: Temperatur des Rotors";
CM_ SG_ 910 EM1_Verlustleistung_02 "Instantaneous power loss of electrical drive EM1 / Momentane Verlustleistung elektischer Antrieb EM1";
CM_ SG_ 910 EM1_Temperatur_KW "Aktueller Ist-Wert Kuehlwassertemperatur Leistungselektronik / E-Machine 1";
CM_ SG_ 135 EM1_HYB_06_CRC "Für MLB:
'Berechnung siehe Lastenheft 'Kommunikationsabsicherung für FlexRay und CAN''

Ab MQB und MLBevo:
'Berechnung siehe Lastenheft 'End-to-End Kommunikationsabsicherung''

Endwerte siehe Begleitdokument 'S-PDU Kennungsfolgen'";
CM_ SG_ 135 EM1_HYB_06_BZ "Botschaft asynchron geroutet. Zählerwert kann springen.";
CM_ SG_ 135 EM1_Istmodus "aktuelle Betriebsart der E-Maschine...
0: Standby; Kommunikation aktiv; PSM: Aktiver Kurzschluss eingenommen
1: Momentenreglung
2: Drehzahlregeung (interner Regelkreis)
3: Spannungsregelung
4: Drehzahlregelung (externer Regelkreis)
5: interner Inver";
CM_ SG_ 135 EM1_Fehler_ElAntriebAbschaltung "Fehler: PWR befindet sich im aktiven Kurzschluss
alle vom EMS gesendeten Max- und Min-Momente und das aktuelle EM-Moment nehmen in diesem Zustand den Wert des für die aktuelle Drehzahl entsprechenden Schleppmoments der E-Maschine an";
CM_ SG_ 135 EM1_Fehler_ElAntriebFreilauf "Fehler: EM im Freilauf; Leistungselektronik fordert Begrenzung der maximalen Drehzahl an, um Überspannung im HV-Zwischenkreis zu vermeiden";
CM_ SG_ 135 EM1_ErwGrenzen_aktiv "Die absoluten Momentengrenzen sind für die Durchführung eines VKM-Starts ggf. aufgeweitet";
CM_ SG_ 135 EM1_Init_abgeschlossen "Status PWR-SG:
0: PWR-SG befindet sich in Init- oder Nachlaufphase; CAN-Signalwerte entsprechen den Init-Werten (Init), den physikalischen Werten (Nachlauf)
1: PWR-SG befindet sich im aktiven Zustand außerhalb Init oder Nachlauf; CAN-Signalwerte sind ph";
CM_ SG_ 135 EM1_Max_Moment "maximal darstellbares Moment für eine im Funktionslastenheft definierte Dauer

Die Berechnung der Momentengrenzen wird projektspezifisch festgelegt";
CM_ SG_ 135 EM1_Min_Moment "minimal darstellbares Moment für eine im Funktionslastenheft definierte Dauer

Die Berechnung der Momentengrenzen wird projektspezifisch festgelegt
";
CM_ SG_ 135 EM1_MaxDyn_Moment "maximal darstellbares Moment für eine im Funktionslastenheft definierte Dauer

Die Berechnung der Momentengrenzen wird projektspezifisch festgelegt";
CM_ SG_ 135 EM1_MinDyn_Moment "minimal darstellbares Moment für eine im Funktionslastenheft definierte Dauer

Die Berechnung der Momentengrenzen wird projektspezifisch festgelegt
";
CM_ SG_ 2527679504 EM1_IstStrom "Momentanwert: Strom über PWR";
CM_ SG_ 2527679504 EM1_IstDrehzahl_02 "Momentanwert: E-Maschinen Drehzahl";
CM_ SG_ 2527679504 EM1_IstMoment_02 "Momentanwert: E-Maschinen Moment";
CM_ SG_ 2527679504 EM1_Verlustleistung "Momentane Verlustleistung Pulswechselrichter und DCDC-Wandler";
CM_ SG_ 892 EM1_HYB_11_CRC "Für MLB:
'Berechnung siehe Lastenheft 'Kommunikationsabsicherung für FlexRay und CAN''

Ab MQB und MLBevo:
'Berechnung siehe Lastenheft 'End-to-End Kommunikationsabsicherung''

Endwerte siehe Begleitdokument 'S-PDU Kennungsfolgen'";
CM_ SG_ 892 EM1_HYB_11_BZ "Fehlende Beschreibung (Import)";
CM_ SG_ 892 EM1_Istmodus2 "aktuelle Betriebsart der E-Maschine...
0: Standby; Kommunikation aktiv; aktiver Kurzschluss
1: Momentenreglung
2: Drezahlregeung (interner Regelkreis)
3: Spannungsregelung
4: Drehzahlregelung (externer Regelkreis)
5: interner Inverter Fehler; angefo";
CM_ SG_ 892 EM1_Fehlerstatus "aktueller Fehlerstatus der LEH1. Anzeige von Fehlern der HV-Sicherheitsfunktionen.";
CM_ SG_ 892 EM1_Status_Spgfreiheit "0 = Init (ohne Funktion)
1 = Leistungselektronik HV-Komponenten spannungsfrei (U_Zwkr < 20V)
2 = Leistungselektronik HV_Komponenten nicht spannungsfrei (U_Zwkr >= 20V)
3 = Fehler (z. B. Fehler in der Sensorik)";
CM_ SG_ 892 EM1_HYB_11_Sendestatus "Gibt den Sendestatus der Botschaft EM1_HYB_11 an (notwendig für IL-Unterstützung)
Dauer hängt von gesetzem HVK_Istmodus_Anf ab.";
CM_ SG_ 892 EM1_EM_SollVolumenstrom "Für die Kühlung der E-Maschine aktuell mindestens benötigter Kühlwasservolumenstrom


MQB/MEB: funktional 500ms (Cyclic) Zykluszeit notwendig

MLBevo: funktional 50ms (OnChange) Zykluszeit notwendig";
CM_ SG_ 115 EM1_HYB_12_CRC "Für MLB:
'Berechnung siehe Lastenheft 'Kommunikationsabsicherung für FlexRay und CAN''

Ab MQB und MLBevo:
'Berechnung siehe Lastenheft 'End-to-End Kommunikationsabsicherung''

Endwerte siehe Begleitdokument 'S-PDU Kennungsfolgen'";
CM_ SG_ 115 EM1_HYB_12_BZ "Botschaft asynchron geroutet. Zählerwert kann springen.";
CM_ SG_ 115 EM1_IstMoment "Momentanwert: E-Maschinen Moment";
CM_ SG_ 115 EM1_IstDrehzahl_alt "Momentanwert: E-Maschinen Drehzahl vor 2,5ms zur Aussetzerdiagnose";
CM_ SG_ 115 EM1_IstDrehzahl "Momentanwert: E-Maschinen Drehzahl";
CM_ SG_ 115 EM1_MaxZul_Drehzahl "EM1_MaxZul_Drehzahl stellt die maximale Drehzahlgrenze für LE bzw. EM dar die im Freilauf zulässig ist. Für Drehzahlen größer dieser Grenze wird die LE zum Komponentenschutz unabhängig von der Kommandierung in den AKS umschalten.";
CM_ SG_ 184 EM1_Freigabe_Info_WFS "WFS-Freigabeinformation";
CM_ SG_ 184 EM1_Sperr_Info_WFS "WFS-Sperrinformation
";
CM_ SG_ 184 EM1_AR_aktiv "Ruckeldämpfer aktiv";
CM_ SG_ 184 EM1_Eta_Sys "Instantaneous efficiency of electrical drive EM1 / Momentaner Wirkungsgrad elektrischer Antrieb EM1";
CM_ SG_ 184 EM1_IstStrom "Momentanwert: Strom über PWR";
CM_ SG_ 184 EM1_Fehler_ElAntriebFreilauf_Anf "Wird gesetzt um den zwingenden Bedarf einer Umschaltung in den Freilauf anzuzeigen. Vergleiche Signal EM1_MaxZul_Drehzahl.";
CM_ SG_ 184 EM1_Abregelung_Temperatur "Leistungsbegrenzung aufgrund Übertemperatur der E-Maschine / des PWR";
CM_ SG_ 184 EM1_AnlernenElMotor_Anf "Diagnoseanforderung von E-Maschine/PWR: Hybrid-Controller schaltet über MO_EM_Sollmodus=6 bzw. MY3_EM_modeReq=6 E-Maschine/PWR aktiv in den Kalibriermodus (Strategie muss sicherstellen, dass kein Moment bei der EM angefordert wird.)";
CM_ SG_ 184 EM1_Moment_HVVerbraucher "rechnerisch benötigtes Generator-Moment, um den Bedarf der el. Nebenverbraucher incl. Batterieladung abzudecken";
CM_ SG_ 184 EM1_Freigabe_Verfallsinfo_WFS "WFS";
CM_ SG_ 184 EM1_Parken_WFS_Status "Status der Limitierung";
CM_ SG_ 184 EM1_HV_betriebsbereit "1: Ready_HV / 1: HV-Netz Spannung im Betriebsbereich";
CM_ SG_ 1106 EM1_HYB_14_CRC "Für MLB:
Berechnung siehe Lastenheft 'Kommunikationsabsicherung für FlexRay und CAN'
Ab MQB und MLBevo:
Berechnung siehe Lastenheft 'End-to-End Kommunikationsabsicherung'

Endwerte siehe Begleitdokument 'S-PDU Kennungsfolgen'";
CM_ SG_ 1106 EM1_HYB_14_BZ "4bit Botschaftszähler, wird mit jeder Sendebotschaft inkrementiert
Botschaft asynchron geroutet. Zählerwert kann springen.";
CM_ SG_ 1106 EM1_MaxPred_Moment "maximal darstellbares Moment für eine im Funktionslastenheft definierte Dauer

Die Berechnung der Momentengrenzen wird projektspezifisch festgelegt";
CM_ SG_ 1106 EM1_MinPred_Moment "minimal darstellbares Moment für eine im Funktionslastenheft definierte Dauer

Die Berechnung der Momentengrenzen wird projektspezifisch festgelegt";
CM_ SG_ 1106 EM1_MaxPred_Abknickdrehzahl "rechnerischer Wert: Abknickdrehzahl für maximales motorisches Moment nach Definition Funktionslastenheft";
CM_ SG_ 1106 EM1_MinPred_Abknickdrehzahl "rechnerischer Wert: Abknickdrehzahl für minimales generatorisches Moment nach Definition Funktionslastenheft";
CM_ SG_ 1106 EM1_Fehler_Leistungsred "Eingeschränkte Leistungsfähigkeit auf Grund eins internen Fehlers";
CM_ SG_ 1106 EM1_IstSpannung "Momentanwert: HV-Spannung am PWR";
CM_ SG_ 2527679712 EM1_RtmWarnKommunikation "Real Time Monitoring EM1 bus communication fault";
CM_ SG_ 2527679712 EM1_RtmWarnUeberdrehzahl "RTM Signal overspeed warning EM1";
CM_ SG_ 2527679712 EM1_RtmWarnUeberstrom "RTM Signal over-current warning EM1";
CM_ BO_ 2527679648 "CAN-Botschaft";
CM_ SG_ 2527679648 EM2_OBD_Lampe_Anf "In allen VW-/Audi-Fahrzeugen ist ein MIL-Master-Konzept umgesetzt. Dazu ermittelt jedes OBD-Steuergerät den eigenen MIL-Status. Eine MIL-Ansteuerung wird vom betroffenen OBD-Steuergerät per MIL-Request über CAN an den MIL-Master weitergegeben. Der MIL-Mas";
CM_ SG_ 2527679648 EM2_FoD_Freischaltstatus_Fkt1 "zeigt den Status der FoD-Freischaltung für das Performanz Paket an";
CM_ SG_ 2527679648 EM2_Temperatur_ElMotor "Momentanwert: Temperatur der E-Maschine";
CM_ SG_ 2527679648 EM2_Temperatur_PWR "Momentanwert: Temperatur des PWR";
CM_ SG_ 2527679648 EM2_Temperatur_Rotor "Momentanwert: Temperatur des Rotors";
CM_ SG_ 2527679648 EM2_Verlustleistung_02 "Instantaneous power loss of electrical drive EM2 / Momentane Verlustleistung elektischer Antrieb EM2";
CM_ SG_ 2527679648 EM2_Temperatur_KW "Aktueller Ist-Wert Kuehlwassertemperatur Leistungselektronik / E-Machine 2";
CM_ SG_ 273 EM2_HYB_06_CRC "Für MLB:
'Berechnung siehe Lastenheft 'Kommunikationsabsicherung für FlexRay und CAN''

Ab MQB und MLBevo:
'Berechnung siehe Lastenheft 'End-to-End Kommunikationsabsicherung''

Endwerte siehe Begleitdokument 'S-PDU Kennungsfolgen'";
CM_ SG_ 273 EM2_HYB_06_BZ "Botschaft asynchron geroutet. Zählerwert kann springen.";
CM_ SG_ 273 EM2_Istmodus "aktuelle Betriebsart der E-Maschine...
0: Standby; Kommunikation aktiv; PSM: Aktiver Kurzschluss eingenommen
1: Momentenreglung
2: Drezahlregeung (interner Regelkreis)
3: Spannungsregelung
4: Drehzahlregelung (externer Regelkreis)
5: interner Invert";
CM_ SG_ 273 EM2_Fehler_ElAntriebAbschaltung "Fehler: PWR befindet sich im aktiven Kurzschluss
alle vom EMS gesendeten Max- und Min-Momente und das aktuelle EM-Moment nehmen in diesem Zustand den Wert des für die aktuelle Drehzahl entsprechenden Schleppmoments der E-Maschine an";
CM_ SG_ 273 EM2_Fehler_ElAntriebFreilauf "Fehler: EM im Freilauf; Leistungselektronik fordert Begrenzung der maximalen Drehzahl an, um Überspannung im HV-Zwischenkreis zu vermeiden";
CM_ SG_ 273 EM2_ErwGrenzen_aktiv "Die absoluten Momentengrenzen sind für die Durchführung eines VKM-Starts ggf. aufgeweitet";
CM_ SG_ 273 EM2_Init_abgeschlossen "Status PWR-SG:
0: PWR-SG befindet sich in Init- oder Nachlaufphase; CAN-Signalwerte entsprechen den Init-Werten (Init), den physikalischen Werten (Nachlauf)
1: PWR-SG befindet sich im aktiven Zustand außerhalb Init oder Nachlauf; CAN-Signalwerte sind ph";
CM_ SG_ 273 EM2_Max_Moment "maximal darstellbares Moment für eine im Funktionslastenheft definierte Dauer

Die Berechnung der Momentengrenzen wird projektspezifisch festgelegt
";
CM_ SG_ 273 EM2_Min_Moment "minimal darstellbares Moment für eine im Funktionslastenheft definierte Dauer

Die Berechnung der Momentengrenzen wird projektspezifisch festgelegt
";
CM_ SG_ 273 EM2_MaxDyn_Moment "maximal darstellbares Moment für eine im Funktionslastenheft definierte Dauer

Die Berechnung der Momentengrenzen wird projektspezifisch festgelegt
";
CM_ SG_ 273 EM2_MinDyn_Moment "minimal darstellbares Moment für eine im Funktionslastenheft definierte Dauer

Die Berechnung der Momentengrenzen wird projektspezifisch festgelegt
";
CM_ SG_ 2463978615 EM2_HYB_11_CRC "Für MLB:
'Berechnung siehe Lastenheft 'Kommunikationsabsicherung für FlexRay und CAN''

Ab MQB und MLBevo:
'Berechnung siehe Lastenheft 'End-to-End Kommunikationsabsicherung''

Endwerte siehe Begleitdokument 'S-PDU Kennungsfolgen'";
CM_ SG_ 2463978615 EM2_HYB_11_BZ "Fehlende Beschreibung (Import)";
CM_ SG_ 2463978615 EM2_Istmodus2 "aktuelle Betriebsart der E-Maschine...
0: Standby; Kommunikation aktiv; aktiver Kurzschluss
1: Momentenreglung
2: Drezahlregeung (interner Regelkreis)
3: Spannungsregelung
4: Drehzahlregelung (externer Regelkreis)
5: interner Inverter Fehler; angefo";
CM_ SG_ 2463978615 EM2_Fehlerstatus "aktueller Fehlerstatus der LE2. Anzeige von Fehlern der HV-Sicherheitsfunktionen.";
CM_ SG_ 2463978615 EM2_Status_Spgfreiheit "0 = Init (ohne Funktion)
1 = Leistungselektronik HV-Komponenten spannungsfrei (U_Zwkr < 20V)
2 = Leistungselektronik HV_Komponenten nicht spannungsfrei (U_Zwkr >= 20V)
3 = Fehler (z. B. Fehler in der Sensorik)";
CM_ SG_ 2463978615 EM2_HYB_11_Sendestatus "Gibt den Sendestatus der Botschaft EM2_HYB_11 an (notwendig für IL-Unterstützung)
Dauer hängt von gesetzem HVK_Istmodus_Anf ab.";
CM_ SG_ 2463978615 EM2_EM_SollVolumenstrom "Für die Kühlung der E-Maschine aktuell mindestens benötigter Kühlwasservolumenstrom


MQB/MEB: funktional 500ms (Cyclic) Zykluszeit notwendig

MLBevo: funktional 50ms (OnChange) Zykluszeit notwendig";
BA_DEF_ BO_  "DiagRequest" ENUM  "No","Yes";
BA_DEF_ BO_  "DiagResponse" ENUM  "No","Yes";
BA_DEF_ BO_  "DiagState" ENUM  "No","Yes";
BA_DEF_ BO_  "GenMsgChkConstant" HEX 0 4095;
BA_DEF_ BO_  "GenMsgCycleTime" INT 0 65535;
BA_DEF_ BO_  "GenMsgCycleTimeFast" INT 0 65535;
BA_DEF_ BO_  "GenMsgDelayTime" INT 0 100000;
BA_DEF_ BO_  "GenMsgILSupport" ENUM  "No","Yes";
BA_DEF_ BO_  "GenMsgNrOfRepetition" INT 0 100;
BA_DEF_ BO_  "GenMsgPDUConstants" STRING ;
BA_DEF_ BO_  "GenMsgSendType" ENUM  "Cyclic","not_used","not_used","not_used","not_used","not_used","not_used","IfActive","NoMsgSendType";
BA_DEF_ BO_  "GenMsgStartDelayTime" INT 0 100000;
BA_DEF_ BO_  "NmMessage" ENUM  "No","Yes";
BA_DEF_ BO_  "NmhMessage" ENUM  "No","Yes";
BA_DEF_ BO_  "MsgType" ENUM  "Application","NM ","NMH","TP2.0","ISO-TP ","BAP","EID","KS","XCP_PRE_CONFIGURED","XCP_RUNTIME_CONFIGURED";
BA_DEF_ BO_  "VAGTP20_API" HEX 0 255;
BA_DEF_ BO_  "VAGTP20_DynConnection" ENUM  "No","Yes";
BA_DEF_ BO_  "VAGTP20_DynSetup" ENUM  "No","Yes";
BA_DEF_ BO_  "VAGTP20_StatConnection" ENUM  "No","Yes";
BA_DEF_ SG_  "GenSigActiveRepetitions" INT -2147483648 2147483647;
BA_DEF_ SG_  "GenSigInactiveValue" INT -2147483648 2147483647;
BA_DEF_ SG_  "GenSigSendType" ENUM  "Cyclic","OnWrite","OnWriteWithRepetition","OnChange","OnChangeWithRepetition","IfActive","IfActiveWithRepetition","NoSigSendType","OnChangeAndIfActive","OnChangeAndIfActiveWithRepetition";
BA_DEF_ SG_  "GenSigStartValue" INT -2147483648 2147483647;
BA_DEF_ SG_  "NWM-WakeupAllowed" ENUM  "No","Yes";
BA_DEF_ SG_  "GenSigFuncType" ENUM  "NoFunction","MsgCounter","CRC-8","XOR","XOR-2","DatedBit","SW-Kl15","CHK","Constant","Protocol","CRC-8-SAE_J1850","CRC-32","DataLength","DataID","MsgCounter16","SOK-Signatur","Cluster";
BA_DEF_ SG_  "GenSigSwitchedByIgnition" ENUM  "No","Yes";
BA_DEF_ SG_  "Fehlerwert" HEX 0 2147483647;
BA_DEF_ SG_  "GenSigMissingSourceValue" HEX 0 2147483647;
BA_DEF_REL_ BU_SG_REL_  "GenSigTimeoutTime" INT 0 65535;
BA_DEF_DEF_REL_ "GenSigTimeoutTime" 0;
BA_DEF_DEF_  "DiagRequest" "No";
BA_DEF_DEF_  "DiagResponse" "No";
BA_DEF_DEF_  "DiagState" "No";
BA_DEF_DEF_  "GenMsgChkConstant" 0;
BA_DEF_DEF_  "GenMsgCycleTime" 0;
BA_DEF_DEF_  "GenMsgCycleTimeFast" 0;
BA_DEF_DEF_  "GenMsgDelayTime" 0;
BA_DEF_DEF_  "GenMsgILSupport" "No";
BA_DEF_DEF_  "GenMsgNrOfRepetition" 0;
BA_DEF_DEF_  "GenMsgPDUConstants" "";
BA_DEF_DEF_  "GenMsgSendType" "NoMsgSendType";
BA_DEF_DEF_  "GenMsgStartDelayTime" 0;
BA_DEF_DEF_  "NmMessage" "No";
BA_DEF_DEF_  "NmhMessage" "No";
BA_DEF_DEF_  "MsgType" "Application";
BA_DEF_DEF_  "VAGTP20_API" 0;
BA_DEF_DEF_  "VAGTP20_DynConnection" "No";
BA_DEF_DEF_  "VAGTP20_DynSetup" "No";
BA_DEF_DEF_  "VAGTP20_StatConnection" "No";
BA_DEF_DEF_  "GenSigActiveRepetitions" 0;
BA_DEF_DEF_  "GenSigInactiveValue" 0;
BA_DEF_DEF_  "GenSigSendType" "NoSigSendType";
BA_DEF_DEF_  "GenSigStartValue" 0;
BA_DEF_DEF_  "NWM-WakeupAllowed" "No";
BA_DEF_DEF_  "GenSigFuncType" "NoFunction";
BA_DEF_DEF_  "GenSigSwitchedByIgnition" "Yes";
BA_DEF_DEF_  "Fehlerwert" 0;
BA_DEF_DEF_  "GenSigMissingSourceValue" 0;
BA_ "GenMsgSendType" BO_ 2589283856 0;
BA_ "GenMsgILSupport" BO_ 2589283856 1;
BA_ "GenMsgCycleTime" BO_ 2589283856 500;
BA_ "GenMsgSendType" BO_ 2589283857 0;
BA_ "GenMsgILSupport" BO_ 2589283857 1;
BA_ "GenMsgCycleTime" BO_ 2589283857 500;
BA_ "GenMsgSendType" BO_ 2589283858 0;
BA_ "GenMsgILSupport" BO_ 2589283858 1;
BA_ "GenMsgCycleTime" BO_ 2589283858 500;
BA_ "GenMsgSendType" BO_ 686 0;
BA_ "GenMsgPDUConstants" BO_ 686 "0x83,0x50,0xbf,0x5d,0x67,0x68,0x2f,0x4b,0x32,0x4e,0x1a,0xba,0xc4,0x39,0xf5,0xdb";
BA_ "GenMsgILSupport" BO_ 686 1;
BA_ "GenMsgCycleTime" BO_ 686 50;
BA_ "GenMsgSendType" BO_ 1012 0;
BA_ "GenMsgPDUConstants" BO_ 1012 "0x26,0xe4,0xc5,0x16,0xcf,0x20,0x65,0xad,0xed,0x6a,0xa3,0x49,0x02,0x6b,0xb2,0xbd";
BA_ "GenMsgILSupport" BO_ 1012 1;
BA_ "GenMsgCycleTime" BO_ 1012 100;
BA_ "GenMsgSendType" BO_ 1485 0;
BA_ "GenMsgPDUConstants" BO_ 1485 "0x93,0x04,0x18,0x69,0xce,0x8f,0xb1,0x53,0x40,0x2d,0xe4,0xca,0x90,0x25,0x79,0x8c";
BA_ "GenMsgILSupport" BO_ 1485 1;
BA_ "GenMsgDelayTime" BO_ 1485 50;
BA_ "GenMsgCycleTime" BO_ 1485 500;
BA_ "GenMsgSendType" BO_ 2527679744 0;
BA_ "GenMsgILSupport" BO_ 2527679744 1;
BA_ "GenMsgDelayTime" BO_ 2527679744 10;
BA_ "GenMsgCycleTime" BO_ 2527679744 100;
BA_ "GenMsgSendType" BO_ 2589283653 0;
BA_ "GenMsgPDUConstants" BO_ 2589283653 "0xc2,0xe1,0xd3,0x20,0x42,0xce,0x68,0x05,0xa9,0x1b,0xa3,0xcc,0xe2,0xdd,0x14,0x08";
BA_ "GenMsgILSupport" BO_ 2589283653 1;
BA_ "GenMsgDelayTime" BO_ 2589283653 50;
BA_ "GenMsgCycleTime" BO_ 2589283653 500;
BA_ "GenMsgSendType" BO_ 2463978669 0;
BA_ "GenMsgPDUConstants" BO_ 2463978669 "0x02,0xf4,0x6f,0x42,0x4a,0x62,0xcd,0x1b,0xb4,0xa0,0x16,0x14,0xe8,0x0a,0x71,0xef";
BA_ "GenMsgILSupport" BO_ 2463978669 1;
BA_ "GenMsgCycleTime" BO_ 2463978669 100;
BA_ "GenMsgSendType" BO_ 2589283662 0;
BA_ "GenMsgILSupport" BO_ 2589283662 1;
BA_ "GenMsgDelayTime" BO_ 2589283662 50;
BA_ "GenMsgCycleTime" BO_ 2589283662 1000;
BA_ "GenMsgSendType" BO_ 685 0;
BA_ "GenMsgPDUConstants" BO_ 685 "0x7b,0xed,0xa6,0xd1,0x57,0x4b,0x69,0x9f,0x13,0x82,0x9e,0x19,0x3e,0x08,0x5e,0x78";
BA_ "GenMsgILSupport" BO_ 685 1;
BA_ "GenMsgCycleTime" BO_ 685 50;
BA_ "GenMsgSendType" BO_ 1018 0;
BA_ "GenMsgPDUConstants" BO_ 1018 "0x26,0xe3,0x43,0x0a,0x6d,0x29,0x22,0xd3,0x52,0x96,0xe4,0xaa,0xe8,0xeb,0xa9,0x89";
BA_ "GenMsgILSupport" BO_ 1018 1;
BA_ "GenMsgCycleTime" BO_ 1018 100;
BA_ "GenMsgSendType" BO_ 1484 0;
BA_ "GenMsgPDUConstants" BO_ 1484 "0x92,0x9d,0xb8,0x71,0xc4,0x40,0x3d,0x49,0x5b,0x4d,0xfa,0x94,0x6d,0x72,0xb3,0x46";
BA_ "GenMsgILSupport" BO_ 1484 1;
BA_ "GenMsgDelayTime" BO_ 1484 50;
BA_ "GenMsgCycleTime" BO_ 1484 500;
BA_ "MsgType" BO_ 2617015040 6;
BA_ "MsgType" BO_ 2617015295 6;
BA_ "MsgType" BO_ 2617078528 6;
BA_ "MsgType" BO_ 2617078783 6;
BA_ "MsgType" BO_ 2617041664 6;
BA_ "MsgType" BO_ 2617041919 6;
BA_ "MsgType" BO_ 2617235968 6;
BA_ "MsgType" BO_ 2617236223 6;
BA_ "MsgType" BO_ 2617129728 6;
BA_ "MsgType" BO_ 2617129729 6;
BA_ "MsgType" BO_ 2617129983 6;
BA_ "MsgType" BO_ 2617096960 6;
BA_ "MsgType" BO_ 2617097215 6;
BA_ "MsgType" BO_ 2617117184 6;
BA_ "MsgType" BO_ 2617117439 6;
BA_ "MsgType" BO_ 2617092864 6;
BA_ "MsgType" BO_ 2617093119 6;
BA_ "MsgType" BO_ 2617193216 6;
BA_ "MsgType" BO_ 2617193217 6;
BA_ "MsgType" BO_ 2617193471 6;
BA_ "MsgType" BO_ 2617123328 6;
BA_ "MsgType" BO_ 2617123329 6;
BA_ "MsgType" BO_ 2617123583 6;
BA_ "MsgType" BO_ 2617238016 6;
BA_ "MsgType" BO_ 2617238271 6;
BA_ "MsgType" BO_ 2617119232 6;
BA_ "MsgType" BO_ 2617119487 6;
BA_ "MsgType" BO_ 2549880528 4;
BA_ "DiagRequest" BO_ 2549880528 1;
BA_ "MsgType" BO_ 2550011600 4;
BA_ "DiagResponse" BO_ 2550011600 1;
BA_ "MsgType" BO_ 2549880529 4;
BA_ "DiagRequest" BO_ 2549880529 1;
BA_ "MsgType" BO_ 2550011601 4;
BA_ "DiagResponse" BO_ 2550011601 1;
BA_ "MsgType" BO_ 2549880530 4;
BA_ "DiagRequest" BO_ 2549880530 1;
BA_ "MsgType" BO_ 2550011602 4;
BA_ "DiagResponse" BO_ 2550011602 1;
BA_ "MsgType" BO_ 2549880531 4;
BA_ "DiagRequest" BO_ 2549880531 1;
BA_ "MsgType" BO_ 2550011603 4;
BA_ "DiagResponse" BO_ 2550011603 1;
BA_ "MsgType" BO_ 2549880532 4;
BA_ "DiagRequest" BO_ 2549880532 1;
BA_ "MsgType" BO_ 2550011604 4;
BA_ "DiagResponse" BO_ 2550011604 1;
BA_ "MsgType" BO_ 2549880533 4;
BA_ "DiagRequest" BO_ 2549880533 1;
BA_ "MsgType" BO_ 2550011605 4;
BA_ "DiagResponse" BO_ 2550011605 1;
BA_ "MsgType" BO_ 2549880534 4;
BA_ "DiagRequest" BO_ 2549880534 1;
BA_ "MsgType" BO_ 2550011606 4;
BA_ "DiagResponse" BO_ 2550011606 1;
BA_ "MsgType" BO_ 2549880535 4;
BA_ "DiagRequest" BO_ 2549880535 1;
BA_ "MsgType" BO_ 2550011607 4;
BA_ "DiagResponse" BO_ 2550011607 1;
BA_ "MsgType" BO_ 2549880536 4;
BA_ "DiagRequest" BO_ 2549880536 1;
BA_ "MsgType" BO_ 2550011608 4;
BA_ "DiagResponse" BO_ 2550011608 1;
BA_ "MsgType" BO_ 2549880537 4;
BA_ "DiagRequest" BO_ 2549880537 1;
BA_ "MsgType" BO_ 2550011609 4;
BA_ "DiagResponse" BO_ 2550011609 1;
BA_ "MsgType" BO_ 2549880538 4;
BA_ "DiagRequest" BO_ 2549880538 1;
BA_ "MsgType" BO_ 2550011610 4;
BA_ "DiagResponse" BO_ 2550011610 1;
BA_ "MsgType" BO_ 2549880539 4;
BA_ "DiagRequest" BO_ 2549880539 1;
BA_ "MsgType" BO_ 2550011611 4;
BA_ "DiagResponse" BO_ 2550011611 1;
BA_ "MsgType" BO_ 2549880540 4;
BA_ "DiagRequest" BO_ 2549880540 1;
BA_ "MsgType" BO_ 2550011612 4;
BA_ "DiagResponse" BO_ 2550011612 1;
BA_ "MsgType" BO_ 2549880561 4;
BA_ "DiagRequest" BO_ 2549880561 1;
BA_ "MsgType" BO_ 2550011633 4;
BA_ "DiagResponse" BO_ 2550011633 1;
BA_ "MsgType" BO_ 2549880562 4;
BA_ "DiagRequest" BO_ 2549880562 1;
BA_ "MsgType" BO_ 2550011634 4;
BA_ "DiagResponse" BO_ 2550011634 1;
BA_ "MsgType" BO_ 2549880563 4;
BA_ "DiagRequest" BO_ 2549880563 1;
BA_ "MsgType" BO_ 2550011635 4;
BA_ "DiagResponse" BO_ 2550011635 1;
BA_ "MsgType" BO_ 2549880717 4;
BA_ "DiagRequest" BO_ 2549880717 1;
BA_ "MsgType" BO_ 2550011789 4;
BA_ "DiagResponse" BO_ 2550011789 1;
BA_ "MsgType" BO_ 2549880413 4;
BA_ "DiagRequest" BO_ 2549880413 1;
BA_ "MsgType" BO_ 2550011485 4;
BA_ "DiagResponse" BO_ 2550011485 1;
BA_ "MsgType" BO_ 2549880512 4;
BA_ "DiagRequest" BO_ 2549880512 1;
BA_ "MsgType" BO_ 2550011584 4;
BA_ "DiagResponse" BO_ 2550011584 1;
BA_ "MsgType" BO_ 2549880714 4;
BA_ "DiagRequest" BO_ 2549880714 1;
BA_ "MsgType" BO_ 2550011786 4;
BA_ "DiagResponse" BO_ 2550011786 1;
BA_ "MsgType" BO_ 2549880570 4;
BA_ "DiagRequest" BO_ 2549880570 1;
BA_ "MsgType" BO_ 2550011642 4;
BA_ "DiagResponse" BO_ 2550011642 1;
BA_ "GenMsgSendType" BO_ 1520 0;
BA_ "GenMsgILSupport" BO_ 1520 1;
BA_ "GenMsgDelayTime" BO_ 1520 50;
BA_ "GenMsgCycleTime" BO_ 1520 200;
BA_ "GenMsgSendType" BO_ 1603 0;
BA_ "GenMsgILSupport" BO_ 1603 1;
BA_ "GenMsgDelayTime" BO_ 1603 100;
BA_ "GenMsgCycleTime" BO_ 1603 1000;
BA_ "GenMsgSendType" BO_ 910 0;
BA_ "GenMsgILSupport" BO_ 910 1;
BA_ "GenMsgCycleTime" BO_ 910 320;
BA_ "GenMsgSendType" BO_ 135 0;
BA_ "GenMsgPDUConstants" BO_ 135 "0x14,0x40,0x8b,0x7a,0x78,0x23,0xc6,0x13,0x1c,0x03,0xed,0xf4,0xcb,0xf8,0xf0,0xe5";
BA_ "GenMsgILSupport" BO_ 135 1;
BA_ "GenMsgCycleTime" BO_ 135 1000;
BA_ "GenMsgSendType" BO_ 2527679504 0;
BA_ "GenMsgILSupport" BO_ 2527679504 1;
BA_ "GenMsgCycleTime" BO_ 2527679504 320;
BA_ "GenMsgSendType" BO_ 892 0;
BA_ "GenMsgPDUConstants" BO_ 892 "0xed,0x03,0x1c,0x13,0xc6,0x23,0x78,0x7a,0x8b,0x40,0x14,0x51,0xbf,0x68,0x32,0xba";
BA_ "GenMsgNrOfRepetition" BO_ 892 5;
BA_ "GenMsgILSupport" BO_ 892 1;
BA_ "GenMsgDelayTime" BO_ 892 40;
BA_ "GenMsgCycleTimeFast" BO_ 892 40;
BA_ "GenMsgCycleTime" BO_ 892 480;
BA_ "GenMsgSendType" BO_ 115 0;
BA_ "GenMsgPDUConstants" BO_ 115 "0xdb,0x71,0x31,0xf9,0x26,0x43,0x6d,0x22,0x52,0xe4,0xe8,0xa9,0x73,0x1c,0xc5,0x67";
BA_ "GenMsgILSupport" BO_ 115 1;
BA_ "GenMsgCycleTime" BO_ 115 1000;
BA_ "GenMsgSendType" BO_ 184 0;
BA_ "GenMsgILSupport" BO_ 184 1;
BA_ "GenMsgCycleTime" BO_ 184 1000;
BA_ "GenMsgSendType" BO_ 1106 0;
BA_ "GenMsgPDUConstants" BO_ 1106 "0x74,0x4a,0x84,0x18,0xb9,0x14,0x9e,0x8f,0x0c,0xdf,0x29,0x40,0x63,0x1f,0xd4,0xca";
BA_ "GenMsgILSupport" BO_ 1106 1;
BA_ "GenMsgCycleTime" BO_ 1106 1000;
BA_ "GenMsgSendType" BO_ 2527679712 0;
BA_ "GenMsgILSupport" BO_ 2527679712 1;
BA_ "GenMsgCycleTime" BO_ 2527679712 960;
BA_ "GenMsgSendType" BO_ 2527679648 0;
BA_ "GenMsgILSupport" BO_ 2527679648 1;
BA_ "GenMsgCycleTime" BO_ 2527679648 320;
BA_ "GenMsgSendType" BO_ 273 0;
BA_ "GenMsgPDUConstants" BO_ 273 "0xb3,0xeb,0xe1,0xf7,0xba,0x9e,0x5f,0xd9,0xc2,0xec,0xf6,0xe9,0x24,0x18,0x48,0xed";
BA_ "GenMsgILSupport" BO_ 273 1;
BA_ "GenMsgCycleTime" BO_ 273 1000;
BA_ "GenMsgSendType" BO_ 2463978615 0;
BA_ "GenMsgPDUConstants" BO_ 2463978615 "0x41,0x5e,0x7f,0xc7,0xc3,0x04,0x0a,0x11,0x34,0x4d,0x9b,0x27,0xaf,0x0d,0x0f,0x31";
BA_ "GenMsgNrOfRepetition" BO_ 2463978615 5;
BA_ "GenMsgILSupport" BO_ 2463978615 1;
BA_ "GenMsgDelayTime" BO_ 2463978615 40;
BA_ "GenMsgCycleTimeFast" BO_ 2463978615 40;
BA_ "GenMsgCycleTime" BO_ 2463978615 480;
BA_ "GenSigSwitchedByIgnition" SG_ 2589283856 DC_MV_Komponentenfehler_63 0;
BA_ "GenSigSendType" SG_ 2589283856 DC_MV_Komponentenfehler_63 0;
BA_ "GenSigSwitchedByIgnition" SG_ 2589283856 DC_MV_Komponentenfehler_64 0;
BA_ "GenSigSendType" SG_ 2589283856 DC_MV_Komponentenfehler_64 0;
BA_ "GenSigSwitchedByIgnition" SG_ 2589283856 DC_MV_Komponentenfehler_65 0;
BA_ "GenSigSendType" SG_ 2589283856 DC_MV_Komponentenfehler_65 0;
BA_ "GenSigSwitchedByIgnition" SG_ 2589283856 DC_MV_Komponentenfehler_66 0;
BA_ "GenSigSendType" SG_ 2589283856 DC_MV_Komponentenfehler_66 0;
BA_ "GenSigSwitchedByIgnition" SG_ 2589283856 DC_MV_Komponentenfehler_67 0;
BA_ "GenSigSendType" SG_ 2589283856 DC_MV_Komponentenfehler_67 0;
BA_ "GenSigSwitchedByIgnition" SG_ 2589283856 DC_MV_Komponentenfehler_68 0;
BA_ "GenSigSendType" SG_ 2589283856 DC_MV_Komponentenfehler_68 0;
BA_ "GenSigSwitchedByIgnition" SG_ 2589283856 DC_MV_Komponentenfehler_69 0;
BA_ "GenSigSendType" SG_ 2589283856 DC_MV_Komponentenfehler_69 0;
BA_ "GenSigSwitchedByIgnition" SG_ 2589283856 DC_MV_Komponentenfehler_70 0;
BA_ "GenSigSendType" SG_ 2589283856 DC_MV_Komponentenfehler_70 0;
BA_ "GenSigSwitchedByIgnition" SG_ 2589283856 DC_MV_Komponentenfehler_71 0;
BA_ "GenSigSendType" SG_ 2589283856 DC_MV_Komponentenfehler_71 0;
BA_ "GenSigSwitchedByIgnition" SG_ 2589283856 DC_MV_Komponentenfehler_72 0;
BA_ "GenSigSendType" SG_ 2589283856 DC_MV_Komponentenfehler_72 0;
BA_ "GenSigSwitchedByIgnition" SG_ 2589283856 DC_MV_Komponentenfehler_73 0;
BA_ "GenSigSendType" SG_ 2589283856 DC_MV_Komponentenfehler_73 0;
BA_ "GenSigSwitchedByIgnition" SG_ 2589283856 DC_MV_Komponentenfehler_74 0;
BA_ "GenSigSendType" SG_ 2589283856 DC_MV_Komponentenfehler_74 0;
BA_ "GenSigSwitchedByIgnition" SG_ 2589283856 DC_MV_Komponentenfehler_75 0;
BA_ "GenSigSendType" SG_ 2589283856 DC_MV_Komponentenfehler_75 0;
BA_ "GenSigSwitchedByIgnition" SG_ 2589283856 DC_MV_Komponentenfehler_76 0;
BA_ "GenSigSendType" SG_ 2589283856 DC_MV_Komponentenfehler_76 0;
BA_ "GenSigSwitchedByIgnition" SG_ 2589283856 DC_MV_Komponentenfehler_77 0;
BA_ "GenSigSendType" SG_ 2589283856 DC_MV_Komponentenfehler_77 0;
BA_ "GenSigSwitchedByIgnition" SG_ 2589283856 DC_MV_Komponentenfehler_78 0;
BA_ "GenSigSendType" SG_ 2589283856 DC_MV_Komponentenfehler_78 0;
BA_ "GenSigSwitchedByIgnition" SG_ 2589283856 DC_MV_Komponentenfehler_79 0;
BA_ "GenSigSendType" SG_ 2589283856 DC_MV_Komponentenfehler_79 0;
BA_ "GenSigSwitchedByIgnition" SG_ 2589283856 DC_MV_Komponentenfehler_80 0;
BA_ "GenSigSendType" SG_ 2589283856 DC_MV_Komponentenfehler_80 0;
BA_ "GenSigSwitchedByIgnition" SG_ 2589283856 DC_MV_Komponentenfehler_81 0;
BA_ "GenSigSendType" SG_ 2589283856 DC_MV_Komponentenfehler_81 0;
BA_ "GenSigSwitchedByIgnition" SG_ 2589283856 DC_MV_Komponentenfehler_82 0;
BA_ "GenSigSendType" SG_ 2589283856 DC_MV_Komponentenfehler_82 0;
BA_ "GenSigSwitchedByIgnition" SG_ 2589283856 DC_MV_Komponentenfehler_83 0;
BA_ "GenSigSendType" SG_ 2589283856 DC_MV_Komponentenfehler_83 0;
BA_ "GenSigSwitchedByIgnition" SG_ 2589283856 DC_MV_Komponentenfehler_84 0;
BA_ "GenSigSendType" SG_ 2589283856 DC_MV_Komponentenfehler_84 0;
BA_ "GenSigSwitchedByIgnition" SG_ 2589283856 DC_MV_Komponentenfehler_85 0;
BA_ "GenSigSendType" SG_ 2589283856 DC_MV_Komponentenfehler_85 0;
BA_ "GenSigSwitchedByIgnition" SG_ 2589283856 DC_MV_Komponentenfehler_86 0;
BA_ "GenSigSendType" SG_ 2589283856 DC_MV_Komponentenfehler_86 0;
BA_ "GenSigSwitchedByIgnition" SG_ 2589283856 DC_MV_Komponentenfehler_87 0;
BA_ "GenSigSendType" SG_ 2589283856 DC_MV_Komponentenfehler_87 0;
BA_ "GenSigSwitchedByIgnition" SG_ 2589283856 DC_MV_Komponentenfehler_88 0;
BA_ "GenSigSendType" SG_ 2589283856 DC_MV_Komponentenfehler_88 0;
BA_ "GenSigSwitchedByIgnition" SG_ 2589283856 DC_MV_Komponentenfehler_89 0;
BA_ "GenSigSendType" SG_ 2589283856 DC_MV_Komponentenfehler_89 0;
BA_ "GenSigSwitchedByIgnition" SG_ 2589283856 DC_MV_Komponentenfehler_90 0;
BA_ "GenSigSendType" SG_ 2589283856 DC_MV_Komponentenfehler_90 0;
BA_ "GenSigSwitchedByIgnition" SG_ 2589283856 DC_MV_Komponentenfehler_91 0;
BA_ "GenSigSendType" SG_ 2589283856 DC_MV_Komponentenfehler_91 0;
BA_ "GenSigSwitchedByIgnition" SG_ 2589283856 DC_MV_Komponentenfehler_92 0;
BA_ "GenSigSendType" SG_ 2589283856 DC_MV_Komponentenfehler_92 0;
BA_ "GenSigSwitchedByIgnition" SG_ 2589283856 DC_MV_Komponentenfehler_93 0;
BA_ "GenSigSendType" SG_ 2589283856 DC_MV_Komponentenfehler_93 0;
BA_ "GenSigSwitchedByIgnition" SG_ 2589283857 DC_MV_Komponentenfehler_94 0;
BA_ "GenSigSendType" SG_ 2589283857 DC_MV_Komponentenfehler_94 0;
BA_ "GenSigSwitchedByIgnition" SG_ 2589283857 DC_MV_Komponentenfehler_95 0;
BA_ "GenSigSendType" SG_ 2589283857 DC_MV_Komponentenfehler_95 0;
BA_ "GenSigSwitchedByIgnition" SG_ 2589283857 DC_MV_Komponentenfehler_96 0;
BA_ "GenSigSendType" SG_ 2589283857 DC_MV_Komponentenfehler_96 0;
BA_ "GenSigSwitchedByIgnition" SG_ 2589283857 DC_MV_Komponentenfehler_97 0;
BA_ "GenSigSendType" SG_ 2589283857 DC_MV_Komponentenfehler_97 0;
BA_ "GenSigSwitchedByIgnition" SG_ 2589283857 DC_MV_Komponentenfehler_98 0;
BA_ "GenSigSendType" SG_ 2589283857 DC_MV_Komponentenfehler_98 0;
BA_ "GenSigSwitchedByIgnition" SG_ 2589283857 DC_MV_Komponentenfehler_99 0;
BA_ "GenSigSendType" SG_ 2589283857 DC_MV_Komponentenfehler_99 0;
BA_ "GenSigSwitchedByIgnition" SG_ 2589283857 DC_MV_Komponentenfehler_100 0;
BA_ "GenSigSendType" SG_ 2589283857 DC_MV_Komponentenfehler_100 0;
BA_ "GenSigSwitchedByIgnition" SG_ 2589283857 DC_MV_Komponentenfehler_101 0;
BA_ "GenSigSendType" SG_ 2589283857 DC_MV_Komponentenfehler_101 0;
BA_ "GenSigSwitchedByIgnition" SG_ 2589283857 DC_MV_Komponentenfehler_102 0;
BA_ "GenSigSendType" SG_ 2589283857 DC_MV_Komponentenfehler_102 0;
BA_ "GenSigSwitchedByIgnition" SG_ 2589283857 DC_MV_Komponentenfehler_103 0;
BA_ "GenSigSendType" SG_ 2589283857 DC_MV_Komponentenfehler_103 0;
BA_ "GenSigSwitchedByIgnition" SG_ 2589283857 DC_MV_Komponentenfehler_104 0;
BA_ "GenSigSendType" SG_ 2589283857 DC_MV_Komponentenfehler_104 0;
BA_ "GenSigSwitchedByIgnition" SG_ 2589283857 DC_MV_Komponentenfehler_105 0;
BA_ "GenSigSendType" SG_ 2589283857 DC_MV_Komponentenfehler_105 0;
BA_ "GenSigSwitchedByIgnition" SG_ 2589283857 DC_MV_Komponentenfehler_106 0;
BA_ "GenSigSendType" SG_ 2589283857 DC_MV_Komponentenfehler_106 0;
BA_ "GenSigSwitchedByIgnition" SG_ 2589283857 DC_MV_Komponentenfehler_107 0;
BA_ "GenSigSendType" SG_ 2589283857 DC_MV_Komponentenfehler_107 0;
BA_ "GenSigSwitchedByIgnition" SG_ 2589283857 DC_MV_Komponentenfehler_108 0;
BA_ "GenSigSendType" SG_ 2589283857 DC_MV_Komponentenfehler_108 0;
BA_ "GenSigSwitchedByIgnition" SG_ 2589283857 DC_MV_Komponentenfehler_109 0;
BA_ "GenSigSendType" SG_ 2589283857 DC_MV_Komponentenfehler_109 0;
BA_ "GenSigSwitchedByIgnition" SG_ 2589283857 DC_MV_Komponentenfehler_110 0;
BA_ "GenSigSendType" SG_ 2589283857 DC_MV_Komponentenfehler_110 0;
BA_ "GenSigSwitchedByIgnition" SG_ 2589283857 DC_MV_Komponentenfehler_111 0;
BA_ "GenSigSendType" SG_ 2589283857 DC_MV_Komponentenfehler_111 0;
BA_ "GenSigSwitchedByIgnition" SG_ 2589283857 DC_MV_Komponentenfehler_112 0;
BA_ "GenSigSendType" SG_ 2589283857 DC_MV_Komponentenfehler_112 0;
BA_ "GenSigSwitchedByIgnition" SG_ 2589283857 DC_MV_Komponentenfehler_113 0;
BA_ "GenSigSendType" SG_ 2589283857 DC_MV_Komponentenfehler_113 0;
BA_ "GenSigSwitchedByIgnition" SG_ 2589283857 DC_MV_Komponentenfehler_114 0;
BA_ "GenSigSendType" SG_ 2589283857 DC_MV_Komponentenfehler_114 0;
BA_ "GenSigSwitchedByIgnition" SG_ 2589283857 DC_MV_Komponentenfehler_115 0;
BA_ "GenSigSendType" SG_ 2589283857 DC_MV_Komponentenfehler_115 0;
BA_ "GenSigSwitchedByIgnition" SG_ 2589283857 DC_MV_Komponentenfehler_116 0;
BA_ "GenSigSendType" SG_ 2589283857 DC_MV_Komponentenfehler_116 0;
BA_ "GenSigSwitchedByIgnition" SG_ 2589283857 DC_MV_Komponentenfehler_117 0;
BA_ "GenSigSendType" SG_ 2589283857 DC_MV_Komponentenfehler_117 0;
BA_ "GenSigSwitchedByIgnition" SG_ 2589283857 DC_MV_Komponentenfehler_118 0;
BA_ "GenSigSendType" SG_ 2589283857 DC_MV_Komponentenfehler_118 0;
BA_ "GenSigSwitchedByIgnition" SG_ 2589283857 DC_MV_Komponentenfehler_119 0;
BA_ "GenSigSendType" SG_ 2589283857 DC_MV_Komponentenfehler_119 0;
BA_ "GenSigSwitchedByIgnition" SG_ 2589283857 DC_MV_Komponentenfehler_120 0;
BA_ "GenSigSendType" SG_ 2589283857 DC_MV_Komponentenfehler_120 0;
BA_ "GenSigSwitchedByIgnition" SG_ 2589283857 DC_MV_Komponentenfehler_121 0;
BA_ "GenSigSendType" SG_ 2589283857 DC_MV_Komponentenfehler_121 0;
BA_ "GenSigSwitchedByIgnition" SG_ 2589283857 DC_MV_Komponentenfehler_122 0;
BA_ "GenSigSendType" SG_ 2589283857 DC_MV_Komponentenfehler_122 0;
BA_ "GenSigSwitchedByIgnition" SG_ 2589283857 DC_MV_Komponentenfehler_123 0;
BA_ "GenSigSendType" SG_ 2589283857 DC_MV_Komponentenfehler_123 0;
BA_ "GenSigSwitchedByIgnition" SG_ 2589283857 DC_MV_Komponentenfehler_124 0;
BA_ "GenSigSendType" SG_ 2589283857 DC_MV_Komponentenfehler_124 0;
BA_ "GenSigSwitchedByIgnition" SG_ 2589283858 DC_MV_Komponentenfehler_125 0;
BA_ "GenSigSendType" SG_ 2589283858 DC_MV_Komponentenfehler_125 0;
BA_ "GenSigSwitchedByIgnition" SG_ 2589283858 DC_MV_Komponentenfehler_126 0;
BA_ "GenSigSendType" SG_ 2589283858 DC_MV_Komponentenfehler_126 0;
BA_ "GenSigSwitchedByIgnition" SG_ 2589283858 DC_MV_Komponentenfehler_127 0;
BA_ "GenSigSendType" SG_ 2589283858 DC_MV_Komponentenfehler_127 0;
BA_ "GenSigSwitchedByIgnition" SG_ 2589283858 DC_MV_Komponentenfehler_128 0;
BA_ "GenSigSendType" SG_ 2589283858 DC_MV_Komponentenfehler_128 0;
BA_ "GenSigSwitchedByIgnition" SG_ 2589283858 DC_MV_Komponentenfehler_129 0;
BA_ "GenSigSendType" SG_ 2589283858 DC_MV_Komponentenfehler_129 0;
BA_ "GenSigSwitchedByIgnition" SG_ 2589283858 DC_MV_Komponentenfehler_130 0;
BA_ "GenSigSendType" SG_ 2589283858 DC_MV_Komponentenfehler_130 0;
BA_ "GenSigSwitchedByIgnition" SG_ 2589283858 DC_MV_Komponentenfehler_131 0;
BA_ "GenSigSendType" SG_ 2589283858 DC_MV_Komponentenfehler_131 0;
BA_ "GenSigSwitchedByIgnition" SG_ 2589283858 DC_MV_Komponentenfehler_132 0;
BA_ "GenSigSendType" SG_ 2589283858 DC_MV_Komponentenfehler_132 0;
BA_ "GenSigSwitchedByIgnition" SG_ 2589283858 DC_MV_Komponentenfehler_133 0;
BA_ "GenSigSendType" SG_ 2589283858 DC_MV_Komponentenfehler_133 0;
BA_ "GenSigSwitchedByIgnition" SG_ 2589283858 DC_MV_Komponentenfehler_134 0;
BA_ "GenSigSendType" SG_ 2589283858 DC_MV_Komponentenfehler_134 0;
BA_ "GenSigSwitchedByIgnition" SG_ 2589283858 DC_MV_Komponentenfehler_135 0;
BA_ "GenSigSendType" SG_ 2589283858 DC_MV_Komponentenfehler_135 0;
BA_ "GenSigSwitchedByIgnition" SG_ 2589283858 DC_MV_Komponentenfehler_136 0;
BA_ "GenSigSendType" SG_ 2589283858 DC_MV_Komponentenfehler_136 0;
BA_ "GenSigSwitchedByIgnition" SG_ 2589283858 DC_MV_Komponentenfehler_137 0;
BA_ "GenSigSendType" SG_ 2589283858 DC_MV_Komponentenfehler_137 0;
BA_ "GenSigSwitchedByIgnition" SG_ 2589283858 DC_MV_Komponentenfehler_138 0;
BA_ "GenSigSendType" SG_ 2589283858 DC_MV_Komponentenfehler_138 0;
BA_ "GenSigSwitchedByIgnition" SG_ 2589283858 DC_MV_Komponentenfehler_139 0;
BA_ "GenSigSendType" SG_ 2589283858 DC_MV_Komponentenfehler_139 0;
BA_ "GenSigSwitchedByIgnition" SG_ 2589283858 DC_MV_Komponentenfehler_140 0;
BA_ "GenSigSendType" SG_ 2589283858 DC_MV_Komponentenfehler_140 0;
BA_ "GenSigSwitchedByIgnition" SG_ 2589283858 DC_MV_Komponentenfehler_141 0;
BA_ "GenSigSendType" SG_ 2589283858 DC_MV_Komponentenfehler_141 0;
BA_ "GenSigSwitchedByIgnition" SG_ 2589283858 DC_MV_Komponentenfehler_142 0;
BA_ "GenSigSendType" SG_ 2589283858 DC_MV_Komponentenfehler_142 0;
BA_ "GenSigSwitchedByIgnition" SG_ 2589283858 DC_MV_Komponentenfehler_143 0;
BA_ "GenSigSendType" SG_ 2589283858 DC_MV_Komponentenfehler_143 0;
BA_ "GenSigSwitchedByIgnition" SG_ 2589283858 DC_MV_Komponentenfehler_144 0;
BA_ "GenSigSendType" SG_ 2589283858 DC_MV_Komponentenfehler_144 0;
BA_ "GenSigSwitchedByIgnition" SG_ 2589283858 DC_MV_Komponentenfehler_145 0;
BA_ "GenSigSendType" SG_ 2589283858 DC_MV_Komponentenfehler_145 0;
BA_ "GenSigSwitchedByIgnition" SG_ 686 DCDC_01_CRC 0;
BA_ "GenSigFuncType" SG_ 686 DCDC_01_CRC 2;
BA_ "GenSigSendType" SG_ 686 DCDC_01_CRC 0;
BA_ "GenSigSwitchedByIgnition" SG_ 686 DCDC_01_BZ 0;
BA_ "GenSigFuncType" SG_ 686 DCDC_01_BZ 1;
BA_ "GenSigSendType" SG_ 686 DCDC_01_BZ 0;
BA_ "Fehlerwert" SG_ 686 DC_IstSpannung_HV 4095;
BA_ "GenSigSwitchedByIgnition" SG_ 686 DC_IstSpannung_HV 0;
BA_ "GenSigStartValue" SG_ 686 DC_IstSpannung_HV 4094;
BA_ "GenSigSendType" SG_ 686 DC_IstSpannung_HV 0;
BA_ "Fehlerwert" SG_ 686 DC_IstStrom_HV_02 1023;
BA_ "GenSigSwitchedByIgnition" SG_ 686 DC_IstStrom_HV_02 0;
BA_ "GenSigStartValue" SG_ 686 DC_IstStrom_HV_02 1022;
BA_ "GenSigSendType" SG_ 686 DC_IstStrom_HV_02 0;
BA_ "Fehlerwert" SG_ 686 DC_IstStrom_NV 1023;
BA_ "GenSigSwitchedByIgnition" SG_ 686 DC_IstStrom_NV 0;
BA_ "GenSigStartValue" SG_ 686 DC_IstStrom_NV 1022;
BA_ "GenSigSendType" SG_ 686 DC_IstStrom_NV 0;
BA_ "Fehlerwert" SG_ 686 DC_IstSpannung_NV 255;
BA_ "GenSigSwitchedByIgnition" SG_ 686 DC_IstSpannung_NV 0;
BA_ "GenSigStartValue" SG_ 686 DC_IstSpannung_NV 254;
BA_ "GenSigSendType" SG_ 686 DC_IstSpannung_NV 0;
BA_ "GenSigSwitchedByIgnition" SG_ 1012 DCDC_02_CRC 0;
BA_ "GenSigFuncType" SG_ 1012 DCDC_02_CRC 2;
BA_ "GenSigSendType" SG_ 1012 DCDC_02_CRC 0;
BA_ "GenSigSwitchedByIgnition" SG_ 1012 DCDC_02_BZ 0;
BA_ "GenSigFuncType" SG_ 1012 DCDC_02_BZ 1;
BA_ "GenSigSendType" SG_ 1012 DCDC_02_BZ 0;
BA_ "Fehlerwert" SG_ 1012 DC_HYB_iAktReserveLV 1023;
BA_ "GenSigSwitchedByIgnition" SG_ 1012 DC_HYB_iAktReserveLV 0;
BA_ "GenSigStartValue" SG_ 1012 DC_HYB_iAktReserveLV 1022;
BA_ "GenSigSendType" SG_ 1012 DC_HYB_iAktReserveLV 0;
BA_ "GenSigSwitchedByIgnition" SG_ 1012 DC_Verbrauch_Ueberlauf 0;
BA_ "GenSigSendType" SG_ 1012 DC_Verbrauch_Ueberlauf 0;
BA_ "GenSigSwitchedByIgnition" SG_ 1012 DC_Verbrauch 0;
BA_ "GenSigSendType" SG_ 1012 DC_Verbrauch 0;
BA_ "Fehlerwert" SG_ 1012 DC_Verlustleistung 63;
BA_ "GenSigSwitchedByIgnition" SG_ 1012 DC_Verlustleistung 0;
BA_ "GenSigStartValue" SG_ 1012 DC_Verlustleistung 62;
BA_ "GenSigSendType" SG_ 1012 DC_Verlustleistung 0;
BA_ "Fehlerwert" SG_ 1012 DC_HYB_Auslastungsgrad 255;
BA_ "GenSigStartValue" SG_ 1012 DC_HYB_Auslastungsgrad 254;
BA_ "GenSigSendType" SG_ 1012 DC_HYB_Auslastungsgrad 0;
BA_ "GenSigSwitchedByIgnition" SG_ 1485 DCDC_03_CRC 0;
BA_ "GenSigFuncType" SG_ 1485 DCDC_03_CRC 2;
BA_ "GenSigSendType" SG_ 1485 DCDC_03_CRC 0;
BA_ "GenSigSwitchedByIgnition" SG_ 1485 DCDC_03_BZ 0;
BA_ "GenSigFuncType" SG_ 1485 DCDC_03_BZ 1;
BA_ "GenSigSendType" SG_ 1485 DCDC_03_BZ 0;
BA_ "GenSigSwitchedByIgnition" SG_ 1485 DC_Fehlerstatus 0;
BA_ "GenSigStartValue" SG_ 1485 DC_Fehlerstatus 7;
BA_ "GenSigSendType" SG_ 1485 DC_Fehlerstatus 3;
BA_ "GenSigSwitchedByIgnition" SG_ 1485 DC_Peakstrom_verfuegbar 0;
BA_ "GenSigSendType" SG_ 1485 DC_Peakstrom_verfuegbar 3;
BA_ "GenSigSwitchedByIgnition" SG_ 1485 DC_Abregelung_Temperatur 0;
BA_ "GenSigSendType" SG_ 1485 DC_Abregelung_Temperatur 3;
BA_ "Fehlerwert" SG_ 1485 DC_IstModus_02 5;
BA_ "GenSigSwitchedByIgnition" SG_ 1485 DC_IstModus_02 0;
BA_ "GenSigStartValue" SG_ 1485 DC_IstModus_02 7;
BA_ "GenSigSendType" SG_ 1485 DC_IstModus_02 3;
BA_ "Fehlerwert" SG_ 1485 DC_HV_EKK_IstModus 5;
BA_ "GenSigSwitchedByIgnition" SG_ 1485 DC_HV_EKK_IstModus 0;
BA_ "GenSigStartValue" SG_ 1485 DC_HV_EKK_IstModus 3;
BA_ "GenSigSendType" SG_ 1485 DC_HV_EKK_IstModus 3;
BA_ "GenSigSwitchedByIgnition" SG_ 1485 DC_Status_Spgfreiheit_HV 0;
BA_ "GenSigSendType" SG_ 1485 DC_Status_Spgfreiheit_HV 3;
BA_ "GenSigSwitchedByIgnition" SG_ 1485 DC_IstSpannung_EKK_HV 0;
BA_ "GenSigStartValue" SG_ 1485 DC_IstSpannung_EKK_HV 255;
BA_ "GenSigSendType" SG_ 1485 DC_IstSpannung_EKK_HV 0;
BA_ "Fehlerwert" SG_ 1485 DC_Temperatur 255;
BA_ "GenSigSwitchedByIgnition" SG_ 1485 DC_Temperatur 0;
BA_ "GenSigStartValue" SG_ 1485 DC_Temperatur 254;
BA_ "GenSigSendType" SG_ 1485 DC_Temperatur 0;
BA_ "Fehlerwert" SG_ 2527679744 DCDC_FC_IstModus 15;
BA_ "GenSigSwitchedByIgnition" SG_ 2527679744 DCDC_FC_IstModus 0;
BA_ "GenSigStartValue" SG_ 2527679744 DCDC_FC_IstModus 14;
BA_ "GenSigSendType" SG_ 2527679744 DCDC_FC_IstModus 3;
BA_ "GenSigSwitchedByIgnition" SG_ 2527679744 DCDC_FC_Abschaltung_Ges 0;
BA_ "GenSigSendType" SG_ 2527679744 DCDC_FC_Abschaltung_Ges 3;
BA_ "GenSigSwitchedByIgnition" SG_ 2527679744 DCDC_FC_Abschaltung_Prim 0;
BA_ "GenSigSendType" SG_ 2527679744 DCDC_FC_Abschaltung_Prim 3;
BA_ "GenSigSwitchedByIgnition" SG_ 2527679744 DCDC_FC_Anf_Abschaltung_Ges 0;
BA_ "GenSigSendType" SG_ 2527679744 DCDC_FC_Anf_Abschaltung_Ges 3;
BA_ "GenSigSwitchedByIgnition" SG_ 2527679744 DCDC_FC_Anf_Abschaltung_Prim 0;
BA_ "GenSigSendType" SG_ 2527679744 DCDC_FC_Anf_Abschaltung_Prim 3;
BA_ "GenSigSwitchedByIgnition" SG_ 2527679744 DCDC_FC_Begrenz_MaxSpannung_Prim 0;
BA_ "GenSigSendType" SG_ 2527679744 DCDC_FC_Begrenz_MaxSpannung_Prim 3;
BA_ "GenSigSwitchedByIgnition" SG_ 2527679744 DCDC_FC_Begrenz_MaxSpannung_Sek 0;
BA_ "GenSigSendType" SG_ 2527679744 DCDC_FC_Begrenz_MaxSpannung_Sek 3;
BA_ "GenSigSwitchedByIgnition" SG_ 2527679744 DCDC_FC_Begrenz_MaxStrom_Prim 0;
BA_ "GenSigSendType" SG_ 2527679744 DCDC_FC_Begrenz_MaxStrom_Prim 3;
BA_ "GenSigSwitchedByIgnition" SG_ 2527679744 DCDC_FC_Begrenz_MaxStrom_Sek 0;
BA_ "GenSigSendType" SG_ 2527679744 DCDC_FC_Begrenz_MaxStrom_Sek 3;
BA_ "GenSigSwitchedByIgnition" SG_ 2527679744 DCDC_FC_Begrenz_MinSpannung_Prim 0;
BA_ "GenSigSendType" SG_ 2527679744 DCDC_FC_Begrenz_MinSpannung_Prim 3;
BA_ "GenSigSwitchedByIgnition" SG_ 2527679744 DCDC_FC_Begrenz_MinSpannung_Sek 0;
BA_ "GenSigSendType" SG_ 2527679744 DCDC_FC_Begrenz_MinSpannung_Sek 3;
BA_ "GenSigSwitchedByIgnition" SG_ 2527679744 DCDC_FC_Begrenz_MinStrom_Prim 0;
BA_ "GenSigSendType" SG_ 2527679744 DCDC_FC_Begrenz_MinStrom_Prim 3;
BA_ "GenSigSwitchedByIgnition" SG_ 2527679744 DCDC_FC_Begrenz_Temp 0;
BA_ "GenSigSendType" SG_ 2527679744 DCDC_FC_Begrenz_Temp 3;
BA_ "GenSigSwitchedByIgnition" SG_ 2527679744 DCDC_FC_Diodenbetrieb 0;
BA_ "GenSigSendType" SG_ 2527679744 DCDC_FC_Diodenbetrieb 3;
BA_ "GenSigSwitchedByIgnition" SG_ 2527679744 DCDC_FC_Fehlerstatus 0;
BA_ "GenSigSendType" SG_ 2527679744 DCDC_FC_Fehlerstatus 3;
BA_ "Fehlerwert" SG_ 2527679744 DCDC_FC_Status_HVSwitch 7;
BA_ "GenSigSwitchedByIgnition" SG_ 2527679744 DCDC_FC_Status_HVSwitch 0;
BA_ "GenSigStartValue" SG_ 2527679744 DCDC_FC_Status_HVSwitch 6;
BA_ "GenSigSendType" SG_ 2527679744 DCDC_FC_Status_HVSwitch 3;
BA_ "Fehlerwert" SG_ 2527679744 DCDC_FC_Status_Interlock 3;
BA_ "GenSigSwitchedByIgnition" SG_ 2527679744 DCDC_FC_Status_Interlock 0;
BA_ "GenSigStartValue" SG_ 2527679744 DCDC_FC_Status_Interlock 2;
BA_ "GenSigSendType" SG_ 2527679744 DCDC_FC_Status_Interlock 3;
BA_ "Fehlerwert" SG_ 2527679744 DCDC_FC_Status_Isowaechter_Netz2 7;
BA_ "GenSigSwitchedByIgnition" SG_ 2527679744 DCDC_FC_Status_Isowaechter_Netz2 0;
BA_ "GenSigStartValue" SG_ 2527679744 DCDC_FC_Status_Isowaechter_Netz2 6;
BA_ "GenSigSendType" SG_ 2527679744 DCDC_FC_Status_Isowaechter_Netz2 3;
BA_ "Fehlerwert" SG_ 2527679744 DCDC_FC_Status_Kl15c 3;
BA_ "GenSigSwitchedByIgnition" SG_ 2527679744 DCDC_FC_Status_Kl15c 0;
BA_ "GenSigStartValue" SG_ 2527679744 DCDC_FC_Status_Kl15c 2;
BA_ "GenSigSendType" SG_ 2527679744 DCDC_FC_Status_Kl15c 3;
BA_ "Fehlerwert" SG_ 2527679744 DCDC_FC_Status_Kl30C 3;
BA_ "GenSigSwitchedByIgnition" SG_ 2527679744 DCDC_FC_Status_Kl30C 0;
BA_ "GenSigStartValue" SG_ 2527679744 DCDC_FC_Status_Kl30C 2;
BA_ "GenSigSendType" SG_ 2527679744 DCDC_FC_Status_Kl30C 3;
BA_ "Fehlerwert" SG_ 2527679744 DCDC_FC_Temperatur 255;
BA_ "GenSigSwitchedByIgnition" SG_ 2527679744 DCDC_FC_Temperatur 0;
BA_ "GenSigStartValue" SG_ 2527679744 DCDC_FC_Temperatur 254;
BA_ "GenSigSendType" SG_ 2527679744 DCDC_FC_Temperatur 0;
BA_ "GenSigSwitchedByIgnition" SG_ 2589283653 DCDC_HV_02_01_CRC 0;
BA_ "GenSigFuncType" SG_ 2589283653 DCDC_HV_02_01_CRC 2;
BA_ "GenSigSendType" SG_ 2589283653 DCDC_HV_02_01_CRC 0;
BA_ "GenSigSwitchedByIgnition" SG_ 2589283653 DCDC_HV_02_01_BZ 0;
BA_ "GenSigFuncType" SG_ 2589283653 DCDC_HV_02_01_BZ 1;
BA_ "GenSigSendType" SG_ 2589283653 DCDC_HV_02_01_BZ 0;
BA_ "Fehlerwert" SG_ 2589283653 HVLB_IstModus_TN1 2;
BA_ "GenSigSwitchedByIgnition" SG_ 2589283653 HVLB_IstModus_TN1 0;
BA_ "GenSigStartValue" SG_ 2589283653 HVLB_IstModus_TN1 3;
BA_ "GenSigSendType" SG_ 2589283653 HVLB_IstModus_TN1 3;
BA_ "Fehlerwert" SG_ 2589283653 HVLB_IstSpannung_DCLS 4095;
BA_ "GenSigSwitchedByIgnition" SG_ 2589283653 HVLB_IstSpannung_DCLS 0;
BA_ "GenSigStartValue" SG_ 2589283653 HVLB_IstSpannung_DCLS 4094;
BA_ "GenSigSendType" SG_ 2589283653 HVLB_IstSpannung_DCLS 0;
BA_ "GenSigSwitchedByIgnition" SG_ 2589283653 HVLB_StatusSpgfreiheit_HV 0;
BA_ "GenSigSendType" SG_ 2589283653 HVLB_StatusSpgfreiheit_HV 0;
BA_ "Fehlerwert" SG_ 2589283653 HVLB_IstModus 4;
BA_ "GenSigSwitchedByIgnition" SG_ 2589283653 HVLB_IstModus 0;
BA_ "GenSigStartValue" SG_ 2589283653 HVLB_IstModus 7;
BA_ "GenSigSendType" SG_ 2589283653 HVLB_IstModus 3;
BA_ "Fehlerwert" SG_ 2589283653 HVLB_IstStrom_HVHS 4095;
BA_ "GenSigSwitchedByIgnition" SG_ 2589283653 HVLB_IstStrom_HVHS 0;
BA_ "GenSigStartValue" SG_ 2589283653 HVLB_IstStrom_HVHS 4094;
BA_ "GenSigSendType" SG_ 2589283653 HVLB_IstStrom_HVHS 0;
BA_ "Fehlerwert" SG_ 2589283653 HVLB_IstSpannung_HVHS 4095;
BA_ "GenSigSwitchedByIgnition" SG_ 2589283653 HVLB_IstSpannung_HVHS 0;
BA_ "GenSigStartValue" SG_ 2589283653 HVLB_IstSpannung_HVHS 4094;
BA_ "GenSigSendType" SG_ 2589283653 HVLB_IstSpannung_HVHS 0;
BA_ "GenSigSwitchedByIgnition" SG_ 2589283653 HVLB_DC_Laden_ohneBoost_verfuegb 0;
BA_ "GenSigSendType" SG_ 2589283653 HVLB_DC_Laden_ohneBoost_verfuegb 0;
BA_ "GenSigSwitchedByIgnition" SG_ 2589283653 HVLB_DC_Laden_mitBoost_verfuegb 0;
BA_ "GenSigSendType" SG_ 2589283653 HVLB_DC_Laden_mitBoost_verfuegb 0;
BA_ "GenSigSwitchedByIgnition" SG_ 2589283653 HVLB_AC_Laden_verfuegbar 0;
BA_ "GenSigSendType" SG_ 2589283653 HVLB_AC_Laden_verfuegbar 0;
BA_ "GenSigSwitchedByIgnition" SG_ 2589283653 HVLB_Warnzustand 0;
BA_ "GenSigSendType" SG_ 2589283653 HVLB_Warnzustand 0;
BA_ "GenSigSwitchedByIgnition" SG_ 2589283653 HVLB_Fehlerstatus 0;
BA_ "GenSigSendType" SG_ 2589283653 HVLB_Fehlerstatus 3;
BA_ "GenSigSwitchedByIgnition" SG_ 2463978669 DCDC_HV_02_02_CRC 0;
BA_ "GenSigFuncType" SG_ 2463978669 DCDC_HV_02_02_CRC 2;
BA_ "GenSigSendType" SG_ 2463978669 DCDC_HV_02_02_CRC 0;
BA_ "GenSigSwitchedByIgnition" SG_ 2463978669 DCDC_HV_02_02_BZ 0;
BA_ "GenSigFuncType" SG_ 2463978669 DCDC_HV_02_02_BZ 1;
BA_ "GenSigSendType" SG_ 2463978669 DCDC_HV_02_02_BZ 0;
BA_ "Fehlerwert" SG_ 2463978669 HVLB_Temperatur 255;
BA_ "GenSigSwitchedByIgnition" SG_ 2463978669 HVLB_Temperatur 0;
BA_ "GenSigStartValue" SG_ 2463978669 HVLB_Temperatur 254;
BA_ "GenSigSendType" SG_ 2463978669 HVLB_Temperatur 0;
BA_ "Fehlerwert" SG_ 2463978669 HVLB_IstSpannung_HVLS 4095;
BA_ "GenSigSwitchedByIgnition" SG_ 2463978669 HVLB_IstSpannung_HVLS 0;
BA_ "GenSigStartValue" SG_ 2463978669 HVLB_IstSpannung_HVLS 4094;
BA_ "GenSigSendType" SG_ 2463978669 HVLB_IstSpannung_HVLS 0;
BA_ "Fehlerwert" SG_ 2463978669 HVLB_MaxDynStrom_HVLS 4095;
BA_ "GenSigSwitchedByIgnition" SG_ 2463978669 HVLB_MaxDynStrom_HVLS 0;
BA_ "GenSigStartValue" SG_ 2463978669 HVLB_MaxDynStrom_HVLS 4094;
BA_ "GenSigSendType" SG_ 2463978669 HVLB_MaxDynStrom_HVLS 0;
BA_ "Fehlerwert" SG_ 2589283662 HVLB_PlanAntw_Verlustleistung 4095;
BA_ "GenSigSwitchedByIgnition" SG_ 2589283662 HVLB_PlanAntw_Verlustleistung 0;
BA_ "GenSigStartValue" SG_ 2589283662 HVLB_PlanAntw_Verlustleistung 4094;
BA_ "GenSigSendType" SG_ 2589283662 HVLB_PlanAntw_Verlustleistung 3;
BA_ "Fehlerwert" SG_ 2589283662 HVLB_PlanAntw_Zaehler 15;
BA_ "GenSigSwitchedByIgnition" SG_ 2589283662 HVLB_PlanAntw_Zaehler 0;
BA_ "GenSigStartValue" SG_ 2589283662 HVLB_PlanAntw_Zaehler 14;
BA_ "GenSigSendType" SG_ 2589283662 HVLB_PlanAntw_Zaehler 3;
BA_ "GenSigSwitchedByIgnition" SG_ 685 DCDC_MV_01_CRC 0;
BA_ "GenSigFuncType" SG_ 685 DCDC_MV_01_CRC 2;
BA_ "GenSigSendType" SG_ 685 DCDC_MV_01_CRC 0;
BA_ "GenSigSwitchedByIgnition" SG_ 685 DCDC_MV_01_BZ 0;
BA_ "GenSigFuncType" SG_ 685 DCDC_MV_01_BZ 1;
BA_ "GenSigSendType" SG_ 685 DCDC_MV_01_BZ 0;
BA_ "Fehlerwert" SG_ 685 DC_MV_IstSpannung_MV 255;
BA_ "GenSigSwitchedByIgnition" SG_ 685 DC_MV_IstSpannung_MV 0;
BA_ "GenSigStartValue" SG_ 685 DC_MV_IstSpannung_MV 254;
BA_ "GenSigSendType" SG_ 685 DC_MV_IstSpannung_MV 0;
BA_ "Fehlerwert" SG_ 685 DC_MV_IstStrom_MV 1023;
BA_ "GenSigSwitchedByIgnition" SG_ 685 DC_MV_IstStrom_MV 0;
BA_ "GenSigStartValue" SG_ 685 DC_MV_IstStrom_MV 1022;
BA_ "GenSigSendType" SG_ 685 DC_MV_IstStrom_MV 0;
BA_ "Fehlerwert" SG_ 685 DC_MV_IstStrom_NV 1023;
BA_ "GenSigSwitchedByIgnition" SG_ 685 DC_MV_IstStrom_NV 0;
BA_ "GenSigStartValue" SG_ 685 DC_MV_IstStrom_NV 1022;
BA_ "GenSigSendType" SG_ 685 DC_MV_IstStrom_NV 0;
BA_ "Fehlerwert" SG_ 685 DC_MV_IstSpannung_NV 255;
BA_ "GenSigSwitchedByIgnition" SG_ 685 DC_MV_IstSpannung_NV 0;
BA_ "GenSigStartValue" SG_ 685 DC_MV_IstSpannung_NV 254;
BA_ "GenSigSendType" SG_ 685 DC_MV_IstSpannung_NV 0;
BA_ "GenSigSwitchedByIgnition" SG_ 1018 DCDC_MV_02_CRC 0;
BA_ "GenSigFuncType" SG_ 1018 DCDC_MV_02_CRC 2;
BA_ "GenSigSendType" SG_ 1018 DCDC_MV_02_CRC 0;
BA_ "GenSigSwitchedByIgnition" SG_ 1018 DCDC_MV_02_BZ 0;
BA_ "GenSigFuncType" SG_ 1018 DCDC_MV_02_BZ 1;
BA_ "GenSigSendType" SG_ 1018 DCDC_MV_02_BZ 0;
BA_ "Fehlerwert" SG_ 1018 DC_MV_akt_Stromreserve_NV 1023;
BA_ "GenSigSwitchedByIgnition" SG_ 1018 DC_MV_akt_Stromreserve_NV 0;
BA_ "GenSigStartValue" SG_ 1018 DC_MV_akt_Stromreserve_NV 1022;
BA_ "GenSigSendType" SG_ 1018 DC_MV_akt_Stromreserve_NV 0;
BA_ "Fehlerwert" SG_ 1018 DC_MV_MaxStrom_MV 63;
BA_ "GenSigSwitchedByIgnition" SG_ 1018 DC_MV_MaxStrom_MV 0;
BA_ "GenSigStartValue" SG_ 1018 DC_MV_MaxStrom_MV 62;
BA_ "GenSigSendType" SG_ 1018 DC_MV_MaxStrom_MV 0;
BA_ "Fehlerwert" SG_ 1018 DC_MV_Auslastungsgrad 255;
BA_ "GenSigSwitchedByIgnition" SG_ 1018 DC_MV_Auslastungsgrad 0;
BA_ "GenSigStartValue" SG_ 1018 DC_MV_Auslastungsgrad 254;
BA_ "GenSigSendType" SG_ 1018 DC_MV_Auslastungsgrad 0;
BA_ "GenSigSwitchedByIgnition" SG_ 1484 DCDC_MV_03_CRC 0;
BA_ "GenSigFuncType" SG_ 1484 DCDC_MV_03_CRC 2;
BA_ "GenSigSendType" SG_ 1484 DCDC_MV_03_CRC 0;
BA_ "GenSigSwitchedByIgnition" SG_ 1484 DCDC_MV_03_BZ 0;
BA_ "GenSigFuncType" SG_ 1484 DCDC_MV_03_BZ 1;
BA_ "GenSigSendType" SG_ 1484 DCDC_MV_03_BZ 0;
BA_ "GenSigSwitchedByIgnition" SG_ 1484 DCDC_MV_Peakstrom_verfuegbar 0;
BA_ "GenSigSendType" SG_ 1484 DCDC_MV_Peakstrom_verfuegbar 3;
BA_ "GenSigSwitchedByIgnition" SG_ 1484 DC_MV_Tiefsetzen_Notbetrieb 0;
BA_ "GenSigSendType" SG_ 1484 DC_MV_Tiefsetzen_Notbetrieb 3;
BA_ "GenSigSwitchedByIgnition" SG_ 1484 DC_MV_Fehlerstatus 0;
BA_ "GenSigStartValue" SG_ 1484 DC_MV_Fehlerstatus 7;
BA_ "GenSigSendType" SG_ 1484 DC_MV_Fehlerstatus 3;
BA_ "GenSigSwitchedByIgnition" SG_ 1484 DC_MV_12V_Bordnetzstuetzung 0;
BA_ "GenSigSendType" SG_ 1484 DC_MV_12V_Bordnetzstuetzung 3;
BA_ "GenSigSwitchedByIgnition" SG_ 1484 DC_MV_Abregelung_Temperatur 0;
BA_ "GenSigSendType" SG_ 1484 DC_MV_Abregelung_Temperatur 3;
BA_ "Fehlerwert" SG_ 1484 DC_MV_IstModus 5;
BA_ "GenSigSwitchedByIgnition" SG_ 1484 DC_MV_IstModus 0;
BA_ "GenSigStartValue" SG_ 1484 DC_MV_IstModus 7;
BA_ "GenSigSendType" SG_ 1484 DC_MV_IstModus 3;
BA_ "Fehlerwert" SG_ 1484 DC_MV_IstModus_02 5;
BA_ "GenSigSwitchedByIgnition" SG_ 1484 DC_MV_IstModus_02 0;
BA_ "GenSigStartValue" SG_ 1484 DC_MV_IstModus_02 7;
BA_ "GenSigSendType" SG_ 1484 DC_MV_IstModus_02 3;
BA_ "GenSigSwitchedByIgnition" SG_ 1484 DC_MV_Dyn_MinSpannung 0;
BA_ "GenSigStartValue" SG_ 1484 DC_MV_Dyn_MinSpannung 254;
BA_ "GenSigSendType" SG_ 1484 DC_MV_Dyn_MinSpannung 0;
BA_ "GenSigSwitchedByIgnition" SG_ 1484 DC_MV_Dyn_MaxSpannung 0;
BA_ "GenSigStartValue" SG_ 1484 DC_MV_Dyn_MaxSpannung 254;
BA_ "GenSigSendType" SG_ 1484 DC_MV_Dyn_MaxSpannung 0;
BA_ "Fehlerwert" SG_ 1484 DC_MV_Temperatur 255;
BA_ "GenSigSwitchedByIgnition" SG_ 1484 DC_MV_Temperatur 0;
BA_ "GenSigStartValue" SG_ 1484 DC_MV_Temperatur 254;
BA_ "GenSigSendType" SG_ 1484 DC_MV_Temperatur 0;
BA_ "GenSigSwitchedByIgnition" SG_ 2617015040 DEV_AWC_Resp_00_Data 0;
BA_ "GenSigSwitchedByIgnition" SG_ 2617015295 DEV_AWC_Resp_FF_Data 0;
BA_ "GenSigSwitchedByIgnition" SG_ 2617078528 DEV_BattRegelung_Req_00_Data 0;
BA_ "GenSigSwitchedByIgnition" SG_ 2617078783 DEV_BattRegelung_Resp_FF_Data 0;
BA_ "GenSigSwitchedByIgnition" SG_ 2617041664 DEV_BMS_MV_Resp_00_Data 0;
BA_ "GenSigSwitchedByIgnition" SG_ 2617041919 DEV_BMS_MV_Resp_FF_Data 0;
BA_ "GenSigSwitchedByIgnition" SG_ 2617235968 DEV_BMS_Resp_00_Data 0;
BA_ "GenSigSwitchedByIgnition" SG_ 2617236223 DEV_BMS_Resp_FF_Data 0;
BA_ "GenSigSwitchedByIgnition" SG_ 2617129728 DEV_DCDC_HV_02_Req_01_Data 0;
BA_ "GenSigFuncType" SG_ 2617129728 DEV_DCDC_HV_02_Req_01_Data 9;
BA_ "GenSigSwitchedByIgnition" SG_ 2617129729 DEV_DCDC_HV_02_Resp_01_Data 0;
BA_ "GenSigFuncType" SG_ 2617129729 DEV_DCDC_HV_02_Resp_01_Data 9;
BA_ "GenSigSwitchedByIgnition" SG_ 2617129983 DEV_DCDC_HV_02_Resp_FF_Data 0;
BA_ "GenSigFuncType" SG_ 2617129983 DEV_DCDC_HV_02_Resp_FF_Data 9;
BA_ "GenSigSwitchedByIgnition" SG_ 2617096960 DEV_DCDC_HV_Resp_00_Data 0;
BA_ "GenSigSwitchedByIgnition" SG_ 2617097215 DEV_DCDC_HV_Resp_FF_Data 0;
BA_ "GenSigSwitchedByIgnition" SG_ 2617117184 DEV_DCDC_Resp_00_Data 0;
BA_ "GenSigSwitchedByIgnition" SG_ 2617117439 DEV_DCDC_Resp_FF_Data 0;
BA_ "GenSigSwitchedByIgnition" SG_ 2617092864 DEV_FCU_Req_01_Data 0;
BA_ "GenSigFuncType" SG_ 2617092864 DEV_FCU_Req_01_Data 9;
BA_ "GenSigSwitchedByIgnition" SG_ 2617093119 DEV_FCU_Resp_FF_Data 0;
BA_ "GenSigFuncType" SG_ 2617093119 DEV_FCU_Resp_FF_Data 9;
BA_ "GenSigSwitchedByIgnition" SG_ 2617193216 DEV_Ladegeraet_2_Req_01_Data 0;
BA_ "GenSigFuncType" SG_ 2617193216 DEV_Ladegeraet_2_Req_01_Data 9;
BA_ "GenSigSwitchedByIgnition" SG_ 2617193217 DEV_Ladegeraet_2_Resp_01_Data 0;
BA_ "GenSigFuncType" SG_ 2617193217 DEV_Ladegeraet_2_Resp_01_Data 9;
BA_ "GenSigSwitchedByIgnition" SG_ 2617193471 DEV_Ladegeraet_2_Resp_FF_Data 0;
BA_ "GenSigFuncType" SG_ 2617193471 DEV_Ladegeraet_2_Resp_FF_Data 9;
BA_ "GenSigSwitchedByIgnition" SG_ 2617123328 DEV_Ladegeraet_Req_01_Data 0;
BA_ "GenSigFuncType" SG_ 2617123328 DEV_Ladegeraet_Req_01_Data 9;
BA_ "GenSigSwitchedByIgnition" SG_ 2617123329 DEV_Ladegeraet_Resp_01_Data 0;
BA_ "GenSigFuncType" SG_ 2617123329 DEV_Ladegeraet_Resp_01_Data 9;
BA_ "GenSigSwitchedByIgnition" SG_ 2617123583 DEV_Ladegeraet_Resp_FF_Data 0;
BA_ "GenSigFuncType" SG_ 2617123583 DEV_Ladegeraet_Resp_FF_Data 9;
BA_ "GenSigSwitchedByIgnition" SG_ 2617238016 DEV_LEH_01_Resp_00_Data 0;
BA_ "GenSigSwitchedByIgnition" SG_ 2617238271 DEV_LEH_01_Resp_FF_Data 0;
BA_ "GenSigSwitchedByIgnition" SG_ 2617119232 DEV_TME_Resp_00_Data 0;
BA_ "GenSigSwitchedByIgnition" SG_ 2617119487 DEV_TME_Resp_FF_Data 0;
BA_ "GenSigSwitchedByIgnition" SG_ 2549880528 DIA_BJB_Req_Data 0;
BA_ "GenSigFuncType" SG_ 2549880528 DIA_BJB_Req_Data 9;
BA_ "GenSigSendType" SG_ 2549880528 DIA_BJB_Req_Data 3;
BA_ "GenSigSwitchedByIgnition" SG_ 2550011600 DIA_BJB_Resp_Data 0;
BA_ "GenSigFuncType" SG_ 2550011600 DIA_BJB_Resp_Data 9;
BA_ "GenSigSendType" SG_ 2550011600 DIA_BJB_Resp_Data 3;
BA_ "GenSigSwitchedByIgnition" SG_ 2549880529 DIA_CMC_01_Req_Data 0;
BA_ "GenSigFuncType" SG_ 2549880529 DIA_CMC_01_Req_Data 9;
BA_ "GenSigSendType" SG_ 2549880529 DIA_CMC_01_Req_Data 3;
BA_ "GenSigSwitchedByIgnition" SG_ 2550011601 DIA_CMC_01_Resp_Data 0;
BA_ "GenSigFuncType" SG_ 2550011601 DIA_CMC_01_Resp_Data 9;
BA_ "GenSigSendType" SG_ 2550011601 DIA_CMC_01_Resp_Data 3;
BA_ "GenSigSwitchedByIgnition" SG_ 2549880530 DIA_CMC_02_Req_Data 0;
BA_ "GenSigFuncType" SG_ 2549880530 DIA_CMC_02_Req_Data 9;
BA_ "GenSigSendType" SG_ 2549880530 DIA_CMC_02_Req_Data 3;
BA_ "GenSigSwitchedByIgnition" SG_ 2550011602 DIA_CMC_02_Resp_Data 0;
BA_ "GenSigFuncType" SG_ 2550011602 DIA_CMC_02_Resp_Data 9;
BA_ "GenSigSendType" SG_ 2550011602 DIA_CMC_02_Resp_Data 3;
BA_ "GenSigSwitchedByIgnition" SG_ 2549880531 DIA_CMC_03_Req_Data 0;
BA_ "GenSigFuncType" SG_ 2549880531 DIA_CMC_03_Req_Data 9;
BA_ "GenSigSendType" SG_ 2549880531 DIA_CMC_03_Req_Data 3;
BA_ "GenSigSwitchedByIgnition" SG_ 2550011603 DIA_CMC_03_Resp_Data 0;
BA_ "GenSigFuncType" SG_ 2550011603 DIA_CMC_03_Resp_Data 9;
BA_ "GenSigSendType" SG_ 2550011603 DIA_CMC_03_Resp_Data 3;
BA_ "GenSigSwitchedByIgnition" SG_ 2549880532 DIA_CMC_04_Req_Data 0;
BA_ "GenSigFuncType" SG_ 2549880532 DIA_CMC_04_Req_Data 9;
BA_ "GenSigSendType" SG_ 2549880532 DIA_CMC_04_Req_Data 3;
BA_ "GenSigSwitchedByIgnition" SG_ 2550011604 DIA_CMC_04_Resp_Data 0;
BA_ "GenSigFuncType" SG_ 2550011604 DIA_CMC_04_Resp_Data 9;
BA_ "GenSigSendType" SG_ 2550011604 DIA_CMC_04_Resp_Data 3;
BA_ "GenSigSwitchedByIgnition" SG_ 2549880533 DIA_CMC_05_Req_Data 0;
BA_ "GenSigFuncType" SG_ 2549880533 DIA_CMC_05_Req_Data 9;
BA_ "GenSigSendType" SG_ 2549880533 DIA_CMC_05_Req_Data 3;
BA_ "GenSigSwitchedByIgnition" SG_ 2550011605 DIA_CMC_05_Resp_Data 0;
BA_ "GenSigFuncType" SG_ 2550011605 DIA_CMC_05_Resp_Data 9;
BA_ "GenSigSendType" SG_ 2550011605 DIA_CMC_05_Resp_Data 3;
BA_ "GenSigSwitchedByIgnition" SG_ 2549880534 DIA_CMC_06_Req_Data 0;
BA_ "GenSigFuncType" SG_ 2549880534 DIA_CMC_06_Req_Data 9;
BA_ "GenSigSendType" SG_ 2549880534 DIA_CMC_06_Req_Data 3;
BA_ "GenSigSwitchedByIgnition" SG_ 2550011606 DIA_CMC_06_Resp_Data 0;
BA_ "GenSigFuncType" SG_ 2550011606 DIA_CMC_06_Resp_Data 9;
BA_ "GenSigSendType" SG_ 2550011606 DIA_CMC_06_Resp_Data 3;
BA_ "GenSigSwitchedByIgnition" SG_ 2549880535 DIA_CMC_07_Req_Data 0;
BA_ "GenSigFuncType" SG_ 2549880535 DIA_CMC_07_Req_Data 9;
BA_ "GenSigSendType" SG_ 2549880535 DIA_CMC_07_Req_Data 3;
BA_ "GenSigSwitchedByIgnition" SG_ 2550011607 DIA_CMC_07_Resp_Data 0;
BA_ "GenSigFuncType" SG_ 2550011607 DIA_CMC_07_Resp_Data 9;
BA_ "GenSigSendType" SG_ 2550011607 DIA_CMC_07_Resp_Data 3;
BA_ "GenSigSwitchedByIgnition" SG_ 2549880536 DIA_CMC_08_Req_Data 0;
BA_ "GenSigFuncType" SG_ 2549880536 DIA_CMC_08_Req_Data 9;
BA_ "GenSigSendType" SG_ 2549880536 DIA_CMC_08_Req_Data 3;
BA_ "GenSigSwitchedByIgnition" SG_ 2550011608 DIA_CMC_08_Resp_Data 0;
BA_ "GenSigFuncType" SG_ 2550011608 DIA_CMC_08_Resp_Data 9;
BA_ "GenSigSendType" SG_ 2550011608 DIA_CMC_08_Resp_Data 3;
BA_ "GenSigSwitchedByIgnition" SG_ 2549880537 DIA_CMC_09_Req_Data 0;
BA_ "GenSigFuncType" SG_ 2549880537 DIA_CMC_09_Req_Data 9;
BA_ "GenSigSendType" SG_ 2549880537 DIA_CMC_09_Req_Data 3;
BA_ "GenSigSwitchedByIgnition" SG_ 2550011609 DIA_CMC_09_Resp_Data 0;
BA_ "GenSigFuncType" SG_ 2550011609 DIA_CMC_09_Resp_Data 9;
BA_ "GenSigSendType" SG_ 2550011609 DIA_CMC_09_Resp_Data 3;
BA_ "GenSigSwitchedByIgnition" SG_ 2549880538 DIA_CMC_10_Req_Data 0;
BA_ "GenSigFuncType" SG_ 2549880538 DIA_CMC_10_Req_Data 9;
BA_ "GenSigSendType" SG_ 2549880538 DIA_CMC_10_Req_Data 3;
BA_ "GenSigSwitchedByIgnition" SG_ 2550011610 DIA_CMC_10_Resp_Data 0;
BA_ "GenSigFuncType" SG_ 2550011610 DIA_CMC_10_Resp_Data 9;
BA_ "GenSigSendType" SG_ 2550011610 DIA_CMC_10_Resp_Data 3;
BA_ "GenSigSwitchedByIgnition" SG_ 2549880539 DIA_CMC_11_Req_Data 0;
BA_ "GenSigFuncType" SG_ 2549880539 DIA_CMC_11_Req_Data 9;
BA_ "GenSigSendType" SG_ 2549880539 DIA_CMC_11_Req_Data 3;
BA_ "GenSigSwitchedByIgnition" SG_ 2550011611 DIA_CMC_11_Resp_Data 0;
BA_ "GenSigFuncType" SG_ 2550011611 DIA_CMC_11_Resp_Data 9;
BA_ "GenSigSendType" SG_ 2550011611 DIA_CMC_11_Resp_Data 3;
BA_ "GenSigSwitchedByIgnition" SG_ 2549880540 DIA_CMC_12_Req_Data 0;
BA_ "GenSigFuncType" SG_ 2549880540 DIA_CMC_12_Req_Data 9;
BA_ "GenSigSendType" SG_ 2549880540 DIA_CMC_12_Req_Data 3;
BA_ "GenSigSwitchedByIgnition" SG_ 2550011612 DIA_CMC_12_Resp_Data 0;
BA_ "GenSigFuncType" SG_ 2550011612 DIA_CMC_12_Resp_Data 9;
BA_ "GenSigSendType" SG_ 2550011612 DIA_CMC_12_Resp_Data 3;
BA_ "GenSigSwitchedByIgnition" SG_ 2549880561 DIA_CMC_13_Req_Data 0;
BA_ "GenSigFuncType" SG_ 2549880561 DIA_CMC_13_Req_Data 9;
BA_ "GenSigSendType" SG_ 2549880561 DIA_CMC_13_Req_Data 3;
BA_ "GenSigSwitchedByIgnition" SG_ 2550011633 DIA_CMC_13_Resp_Data 0;
BA_ "GenSigFuncType" SG_ 2550011633 DIA_CMC_13_Resp_Data 9;
BA_ "GenSigSendType" SG_ 2550011633 DIA_CMC_13_Resp_Data 3;
BA_ "GenSigSwitchedByIgnition" SG_ 2549880562 DIA_CMC_14_Req_Data 0;
BA_ "GenSigFuncType" SG_ 2549880562 DIA_CMC_14_Req_Data 9;
BA_ "GenSigSendType" SG_ 2549880562 DIA_CMC_14_Req_Data 3;
BA_ "GenSigSwitchedByIgnition" SG_ 2550011634 DIA_CMC_14_Resp_Data 0;
BA_ "GenSigFuncType" SG_ 2550011634 DIA_CMC_14_Resp_Data 9;
BA_ "GenSigSendType" SG_ 2550011634 DIA_CMC_14_Resp_Data 3;
BA_ "GenSigSwitchedByIgnition" SG_ 2549880563 DIA_CMC_15_Req_Data 0;
BA_ "GenSigFuncType" SG_ 2549880563 DIA_CMC_15_Req_Data 9;
BA_ "GenSigSendType" SG_ 2549880563 DIA_CMC_15_Req_Data 3;
BA_ "GenSigSwitchedByIgnition" SG_ 2550011635 DIA_CMC_15_Resp_Data 0;
BA_ "GenSigFuncType" SG_ 2550011635 DIA_CMC_15_Resp_Data 9;
BA_ "GenSigSendType" SG_ 2550011635 DIA_CMC_15_Resp_Data 3;
BA_ "GenSigSwitchedByIgnition" SG_ 2549880717 DIA_eBooster2_Req_Data 0;
BA_ "GenSigSendType" SG_ 2549880717 DIA_eBooster2_Req_Data 3;
BA_ "GenSigSwitchedByIgnition" SG_ 2550011789 DIA_eBooster2_Resp_Data 0;
BA_ "GenSigSendType" SG_ 2550011789 DIA_eBooster2_Resp_Data 3;
BA_ "GenSigSwitchedByIgnition" SG_ 2549880413 DIA_EKK_Req_Data 0;
BA_ "GenSigFuncType" SG_ 2549880413 DIA_EKK_Req_Data 9;
BA_ "GenSigSendType" SG_ 2549880413 DIA_EKK_Req_Data 3;
BA_ "GenSigSwitchedByIgnition" SG_ 2550011485 DIA_EKK_Resp_Data 0;
BA_ "GenSigFuncType" SG_ 2550011485 DIA_EKK_Resp_Data 9;
BA_ "GenSigSendType" SG_ 2550011485 DIA_EKK_Resp_Data 3;
BA_ "GenSigSwitchedByIgnition" SG_ 2549880512 DIA_HV_H2_Req_Data 0;
BA_ "GenSigFuncType" SG_ 2549880512 DIA_HV_H2_Req_Data 9;
BA_ "GenSigSendType" SG_ 2549880512 DIA_HV_H2_Req_Data 3;
BA_ "GenSigSwitchedByIgnition" SG_ 2550011584 DIA_HV_H2_Resp_Data 0;
BA_ "GenSigFuncType" SG_ 2550011584 DIA_HV_H2_Resp_Data 9;
BA_ "GenSigSendType" SG_ 2550011584 DIA_HV_H2_Resp_Data 3;
BA_ "GenSigSwitchedByIgnition" SG_ 2549880714 DIA_PumpKM_2_Req_Data 0;
BA_ "GenSigFuncType" SG_ 2549880714 DIA_PumpKM_2_Req_Data 9;
BA_ "GenSigSendType" SG_ 2549880714 DIA_PumpKM_2_Req_Data 3;
BA_ "GenSigSwitchedByIgnition" SG_ 2550011786 DIA_PumpKM_2_Resp_Data 0;
BA_ "GenSigFuncType" SG_ 2550011786 DIA_PumpKM_2_Resp_Data 9;
BA_ "GenSigSendType" SG_ 2550011786 DIA_PumpKM_2_Resp_Data 3;
BA_ "GenSigSwitchedByIgnition" SG_ 2549880570 DIA_PumpWSt_Req_Data 0;
BA_ "GenSigFuncType" SG_ 2549880570 DIA_PumpWSt_Req_Data 9;
BA_ "GenSigSendType" SG_ 2549880570 DIA_PumpWSt_Req_Data 3;
BA_ "GenSigSwitchedByIgnition" SG_ 2550011642 DIA_PumpWSt_Resp_Data 0;
BA_ "GenSigFuncType" SG_ 2550011642 DIA_PumpWSt_Resp_Data 9;
BA_ "GenSigSendType" SG_ 2550011642 DIA_PumpWSt_Resp_Data 3;
BA_ "Fehlerwert" SG_ 1520 DI_KL_58xd 255;
BA_ "GenSigSwitchedByIgnition" SG_ 1520 DI_KL_58xd 0;
BA_ "GenSigStartValue" SG_ 1520 DI_KL_58xd 254;
BA_ "GenSigSendType" SG_ 1520 DI_KL_58xd 3;
BA_ "Fehlerwert" SG_ 1520 DI_KL_58xs 127;
BA_ "GenSigSwitchedByIgnition" SG_ 1520 DI_KL_58xs 0;
BA_ "GenSigStartValue" SG_ 1520 DI_KL_58xs 126;
BA_ "GenSigSendType" SG_ 1520 DI_KL_58xs 3;
BA_ "GenSigSwitchedByIgnition" SG_ 1520 DI_Display_Nachtdesign 0;
BA_ "GenSigSendType" SG_ 1520 DI_Display_Nachtdesign 3;
BA_ "Fehlerwert" SG_ 1520 DI_KL_58xt 127;
BA_ "GenSigSwitchedByIgnition" SG_ 1520 DI_KL_58xt 0;
BA_ "GenSigStartValue" SG_ 1520 DI_KL_58xt 126;
BA_ "GenSigSendType" SG_ 1520 DI_KL_58xt 3;
BA_ "GenSigSwitchedByIgnition" SG_ 1520 DI_Fotosensor 0;
BA_ "GenSigSendType" SG_ 1520 DI_Fotosensor 3;
BA_ "Fehlerwert" SG_ 1520 BCM1_Stellgroesse_Kl_58s 127;
BA_ "GenSigSwitchedByIgnition" SG_ 1520 BCM1_Stellgroesse_Kl_58s 0;
BA_ "GenSigStartValue" SG_ 1520 BCM1_Stellgroesse_Kl_58s 126;
BA_ "GenSigSendType" SG_ 1520 BCM1_Stellgroesse_Kl_58s 3;
BA_ "GenSigSwitchedByIgnition" SG_ 1603 KBI_Einheit_Datum 0;
BA_ "GenSigSendType" SG_ 1603 KBI_Einheit_Datum 3;
BA_ "GenSigSwitchedByIgnition" SG_ 1603 KBI_Einheit_Druck 0;
BA_ "GenSigSendType" SG_ 1603 KBI_Einheit_Druck 3;
BA_ "GenSigSwitchedByIgnition" SG_ 1603 KBI_Einheit_Streckenanz 0;
BA_ "GenSigSendType" SG_ 1603 KBI_Einheit_Streckenanz 3;
BA_ "GenSigSwitchedByIgnition" SG_ 1603 KBI_MFA_v_Einheit_02 0;
BA_ "GenSigSendType" SG_ 1603 KBI_MFA_v_Einheit_02 3;
BA_ "GenSigSwitchedByIgnition" SG_ 1603 KBI_Einheit_Temp 0;
BA_ "GenSigSendType" SG_ 1603 KBI_Einheit_Temp 3;
BA_ "GenSigSwitchedByIgnition" SG_ 1603 KBI_Einheit_Uhrzeit 0;
BA_ "GenSigSendType" SG_ 1603 KBI_Einheit_Uhrzeit 3;
BA_ "GenSigSwitchedByIgnition" SG_ 1603 KBI_Einheit_Verbrauch 0;
BA_ "GenSigSendType" SG_ 1603 KBI_Einheit_Verbrauch 3;
BA_ "GenSigSwitchedByIgnition" SG_ 1603 KBI_Einheit_Volumen 0;
BA_ "GenSigSendType" SG_ 1603 KBI_Einheit_Volumen 3;
BA_ "GenSigSwitchedByIgnition" SG_ 1603 KBI_Einheit_Verbrauch_elektr 0;
BA_ "GenSigSendType" SG_ 1603 KBI_Einheit_Verbrauch_elektr 3;
BA_ "GenSigSwitchedByIgnition" SG_ 1603 KBI_Einheit_Sprache 0;
BA_ "GenSigSendType" SG_ 1603 KBI_Einheit_Sprache 3;
BA_ "GenSigSendType" SG_ 1603 KBI_Einheit_Verbrauch_Gas 3;
BA_ "GenSigSwitchedByIgnition" SG_ 1603 KBI_Einheit_Masse 0;
BA_ "GenSigSendType" SG_ 1603 KBI_Einheit_Masse 3;
BA_ "GenSigSwitchedByIgnition" SG_ 910 EM1_OBD_Lampe_Anf 0;
BA_ "GenSigSendType" SG_ 910 EM1_OBD_Lampe_Anf 0;
BA_ "GenSigSwitchedByIgnition" SG_ 910 EM1_FoD_Freischaltstatus_Fkt1 0;
BA_ "GenSigSendType" SG_ 910 EM1_FoD_Freischaltstatus_Fkt1 0;
BA_ "Fehlerwert" SG_ 910 EM1_Temperatur_ElMotor 255;
BA_ "GenSigSwitchedByIgnition" SG_ 910 EM1_Temperatur_ElMotor 0;
BA_ "GenSigStartValue" SG_ 910 EM1_Temperatur_ElMotor 254;
BA_ "GenSigSendType" SG_ 910 EM1_Temperatur_ElMotor 0;
BA_ "Fehlerwert" SG_ 910 EM1_Temperatur_PWR 255;
BA_ "GenSigSwitchedByIgnition" SG_ 910 EM1_Temperatur_PWR 0;
BA_ "GenSigStartValue" SG_ 910 EM1_Temperatur_PWR 254;
BA_ "GenSigSendType" SG_ 910 EM1_Temperatur_PWR 0;
BA_ "Fehlerwert" SG_ 910 EM1_Temperatur_Rotor 255;
BA_ "GenSigSwitchedByIgnition" SG_ 910 EM1_Temperatur_Rotor 0;
BA_ "GenSigStartValue" SG_ 910 EM1_Temperatur_Rotor 254;
BA_ "GenSigSendType" SG_ 910 EM1_Temperatur_Rotor 0;
BA_ "Fehlerwert" SG_ 910 EM1_Verlustleistung_02 1023;
BA_ "GenSigSwitchedByIgnition" SG_ 910 EM1_Verlustleistung_02 0;
BA_ "GenSigStartValue" SG_ 910 EM1_Verlustleistung_02 1022;
BA_ "GenSigSendType" SG_ 910 EM1_Verlustleistung_02 0;
BA_ "Fehlerwert" SG_ 910 EM1_Temperatur_KW 255;
BA_ "GenSigSwitchedByIgnition" SG_ 910 EM1_Temperatur_KW 0;
BA_ "GenSigStartValue" SG_ 910 EM1_Temperatur_KW 254;
BA_ "GenSigSendType" SG_ 910 EM1_Temperatur_KW 0;
BA_ "GenSigSwitchedByIgnition" SG_ 135 EM1_HYB_06_CRC 0;
BA_ "GenSigFuncType" SG_ 135 EM1_HYB_06_CRC 2;
BA_ "GenSigSendType" SG_ 135 EM1_HYB_06_CRC 0;
BA_ "GenSigSwitchedByIgnition" SG_ 135 EM1_HYB_06_BZ 0;
BA_ "GenSigFuncType" SG_ 135 EM1_HYB_06_BZ 1;
BA_ "GenSigSendType" SG_ 135 EM1_HYB_06_BZ 0;
BA_ "GenSigSwitchedByIgnition" SG_ 135 EM1_Istmodus 0;
BA_ "GenSigStartValue" SG_ 135 EM1_Istmodus 15;
BA_ "GenSigSendType" SG_ 135 EM1_Istmodus 0;
BA_ "GenSigSwitchedByIgnition" SG_ 135 EM1_Fehler_ElAntriebAbschaltung 0;
BA_ "GenSigSendType" SG_ 135 EM1_Fehler_ElAntriebAbschaltung 0;
BA_ "GenSigSwitchedByIgnition" SG_ 135 EM1_Fehler_ElAntriebFreilauf 0;
BA_ "GenSigSendType" SG_ 135 EM1_Fehler_ElAntriebFreilauf 0;
BA_ "GenSigSwitchedByIgnition" SG_ 135 EM1_ErwGrenzen_aktiv 0;
BA_ "GenSigSendType" SG_ 135 EM1_ErwGrenzen_aktiv 0;
BA_ "GenSigSwitchedByIgnition" SG_ 135 EM1_Init_abgeschlossen 0;
BA_ "GenSigSendType" SG_ 135 EM1_Init_abgeschlossen 0;
BA_ "Fehlerwert" SG_ 135 EM1_Max_Moment 2047;
BA_ "GenSigSwitchedByIgnition" SG_ 135 EM1_Max_Moment 0;
BA_ "GenSigStartValue" SG_ 135 EM1_Max_Moment 2046;
BA_ "GenSigSendType" SG_ 135 EM1_Max_Moment 0;
BA_ "Fehlerwert" SG_ 135 EM1_Min_Moment 2047;
BA_ "GenSigSwitchedByIgnition" SG_ 135 EM1_Min_Moment 0;
BA_ "GenSigStartValue" SG_ 135 EM1_Min_Moment 2046;
BA_ "GenSigSendType" SG_ 135 EM1_Min_Moment 0;
BA_ "Fehlerwert" SG_ 135 EM1_MaxDyn_Moment 2047;
BA_ "GenSigSwitchedByIgnition" SG_ 135 EM1_MaxDyn_Moment 0;
BA_ "GenSigStartValue" SG_ 135 EM1_MaxDyn_Moment 2046;
BA_ "GenSigSendType" SG_ 135 EM1_MaxDyn_Moment 0;
BA_ "Fehlerwert" SG_ 135 EM1_MinDyn_Moment 2047;
BA_ "GenSigSwitchedByIgnition" SG_ 135 EM1_MinDyn_Moment 0;
BA_ "GenSigStartValue" SG_ 135 EM1_MinDyn_Moment 2046;
BA_ "GenSigSendType" SG_ 135 EM1_MinDyn_Moment 0;
BA_ "Fehlerwert" SG_ 2527679504 EM1_IstStrom 2047;
BA_ "GenSigSwitchedByIgnition" SG_ 2527679504 EM1_IstStrom 0;
BA_ "GenSigStartValue" SG_ 2527679504 EM1_IstStrom 2046;
BA_ "GenSigSendType" SG_ 2527679504 EM1_IstStrom 0;
BA_ "Fehlerwert" SG_ 2527679504 EM1_IstDrehzahl_02 32767;
BA_ "GenSigSwitchedByIgnition" SG_ 2527679504 EM1_IstDrehzahl_02 0;
BA_ "GenSigStartValue" SG_ 2527679504 EM1_IstDrehzahl_02 32766;
BA_ "GenSigSendType" SG_ 2527679504 EM1_IstDrehzahl_02 0;
BA_ "Fehlerwert" SG_ 2527679504 EM1_IstMoment_02 4095;
BA_ "GenSigSwitchedByIgnition" SG_ 2527679504 EM1_IstMoment_02 0;
BA_ "GenSigStartValue" SG_ 2527679504 EM1_IstMoment_02 4094;
BA_ "GenSigSendType" SG_ 2527679504 EM1_IstMoment_02 0;
BA_ "Fehlerwert" SG_ 2527679504 EM1_Verlustleistung 255;
BA_ "GenSigSwitchedByIgnition" SG_ 2527679504 EM1_Verlustleistung 0;
BA_ "GenSigStartValue" SG_ 2527679504 EM1_Verlustleistung 254;
BA_ "GenSigSendType" SG_ 2527679504 EM1_Verlustleistung 0;
BA_ "GenSigSwitchedByIgnition" SG_ 892 EM1_HYB_11_CRC 0;
BA_ "GenSigFuncType" SG_ 892 EM1_HYB_11_CRC 2;
BA_ "GenSigSendType" SG_ 892 EM1_HYB_11_CRC 0;
BA_ "GenSigSwitchedByIgnition" SG_ 892 EM1_HYB_11_BZ 0;
BA_ "GenSigFuncType" SG_ 892 EM1_HYB_11_BZ 1;
BA_ "GenSigSendType" SG_ 892 EM1_HYB_11_BZ 0;
BA_ "GenSigSwitchedByIgnition" SG_ 892 EM1_Istmodus2 0;
BA_ "GenSigStartValue" SG_ 892 EM1_Istmodus2 15;
BA_ "GenSigSendType" SG_ 892 EM1_Istmodus2 3;
BA_ "GenSigSwitchedByIgnition" SG_ 892 EM1_Fehlerstatus 0;
BA_ "GenSigStartValue" SG_ 892 EM1_Fehlerstatus 7;
BA_ "GenSigSendType" SG_ 892 EM1_Fehlerstatus 3;
BA_ "GenSigSwitchedByIgnition" SG_ 892 EM1_Status_Spgfreiheit 0;
BA_ "GenSigSendType" SG_ 892 EM1_Status_Spgfreiheit 3;
BA_ "GenSigSwitchedByIgnition" SG_ 892 EM1_HYB_11_Sendestatus 0;
BA_ "GenSigSendType" SG_ 892 EM1_HYB_11_Sendestatus 9;
BA_ "GenSigActiveRepetitions" SG_ 892 EM1_HYB_11_Sendestatus 5;
BA_ "Fehlerwert" SG_ 892 EM1_EM_SollVolumenstrom 63;
BA_ "GenSigSwitchedByIgnition" SG_ 892 EM1_EM_SollVolumenstrom 0;
BA_ "GenSigStartValue" SG_ 892 EM1_EM_SollVolumenstrom 62;
BA_ "GenSigSendType" SG_ 892 EM1_EM_SollVolumenstrom 3;
BA_ "GenSigSwitchedByIgnition" SG_ 115 EM1_HYB_12_CRC 0;
BA_ "GenSigFuncType" SG_ 115 EM1_HYB_12_CRC 2;
BA_ "GenSigSendType" SG_ 115 EM1_HYB_12_CRC 0;
BA_ "GenSigSwitchedByIgnition" SG_ 115 EM1_HYB_12_BZ 0;
BA_ "GenSigFuncType" SG_ 115 EM1_HYB_12_BZ 1;
BA_ "GenSigSendType" SG_ 115 EM1_HYB_12_BZ 0;
BA_ "Fehlerwert" SG_ 115 EM1_IstMoment 4095;
BA_ "GenSigSwitchedByIgnition" SG_ 115 EM1_IstMoment 0;
BA_ "GenSigStartValue" SG_ 115 EM1_IstMoment 4094;
BA_ "GenSigSendType" SG_ 115 EM1_IstMoment 0;
BA_ "Fehlerwert" SG_ 115 EM1_IstDrehzahl_alt 32767;
BA_ "GenSigStartValue" SG_ 115 EM1_IstDrehzahl_alt 32766;
BA_ "GenSigSendType" SG_ 115 EM1_IstDrehzahl_alt 0;
BA_ "Fehlerwert" SG_ 115 EM1_IstDrehzahl 32767;
BA_ "GenSigSwitchedByIgnition" SG_ 115 EM1_IstDrehzahl 0;
BA_ "GenSigStartValue" SG_ 115 EM1_IstDrehzahl 32766;
BA_ "GenSigSendType" SG_ 115 EM1_IstDrehzahl 0;
BA_ "Fehlerwert" SG_ 115 EM1_MaxZul_Drehzahl 255;
BA_ "GenSigSwitchedByIgnition" SG_ 115 EM1_MaxZul_Drehzahl 0;
BA_ "GenSigStartValue" SG_ 115 EM1_MaxZul_Drehzahl 254;
BA_ "GenSigSendType" SG_ 115 EM1_MaxZul_Drehzahl 0;
BA_ "GenSigSwitchedByIgnition" SG_ 184 EM1_Freigabe_Info_WFS 0;
BA_ "GenSigSendType" SG_ 184 EM1_Freigabe_Info_WFS 0;
BA_ "GenSigSwitchedByIgnition" SG_ 184 EM1_Sperr_Info_WFS 0;
BA_ "GenSigSendType" SG_ 184 EM1_Sperr_Info_WFS 0;
BA_ "GenSigSwitchedByIgnition" SG_ 184 EM1_AR_aktiv 0;
BA_ "GenSigSendType" SG_ 184 EM1_AR_aktiv 0;
BA_ "Fehlerwert" SG_ 184 EM1_Eta_Sys 511;
BA_ "GenSigSwitchedByIgnition" SG_ 184 EM1_Eta_Sys 0;
BA_ "GenSigStartValue" SG_ 184 EM1_Eta_Sys 510;
BA_ "GenSigSendType" SG_ 184 EM1_Eta_Sys 0;
BA_ "Fehlerwert" SG_ 184 EM1_IstStrom 2047;
BA_ "GenSigSwitchedByIgnition" SG_ 184 EM1_IstStrom 0;
BA_ "GenSigStartValue" SG_ 184 EM1_IstStrom 2046;
BA_ "GenSigSendType" SG_ 184 EM1_IstStrom 0;
BA_ "GenSigSwitchedByIgnition" SG_ 184 EM1_Fehler_ElAntriebFreilauf_Anf 0;
BA_ "GenSigSendType" SG_ 184 EM1_Fehler_ElAntriebFreilauf_Anf 0;
BA_ "GenSigSwitchedByIgnition" SG_ 184 EM1_Abregelung_Temperatur 0;
BA_ "GenSigSendType" SG_ 184 EM1_Abregelung_Temperatur 0;
BA_ "GenSigSwitchedByIgnition" SG_ 184 EM1_AnlernenElMotor_Anf 0;
BA_ "GenSigSendType" SG_ 184 EM1_AnlernenElMotor_Anf 0;
BA_ "GenSigSwitchedByIgnition" SG_ 184 EM1_Moment_HVVerbraucher 0;
BA_ "GenSigStartValue" SG_ 184 EM1_Moment_HVVerbraucher 1023;
BA_ "GenSigSendType" SG_ 184 EM1_Moment_HVVerbraucher 0;
BA_ "GenSigSwitchedByIgnition" SG_ 184 EM1_Freigabe_Verfallsinfo_WFS 0;
BA_ "GenSigSendType" SG_ 184 EM1_Freigabe_Verfallsinfo_WFS 0;
BA_ "GenSigSwitchedByIgnition" SG_ 184 EM1_Parken_WFS_Status 0;
BA_ "GenSigSendType" SG_ 184 EM1_Parken_WFS_Status 0;
BA_ "GenSigSwitchedByIgnition" SG_ 184 EM1_HV_betriebsbereit 0;
BA_ "GenSigSendType" SG_ 184 EM1_HV_betriebsbereit 0;
BA_ "GenSigSwitchedByIgnition" SG_ 1106 EM1_HYB_14_CRC 0;
BA_ "GenSigFuncType" SG_ 1106 EM1_HYB_14_CRC 2;
BA_ "GenSigSendType" SG_ 1106 EM1_HYB_14_CRC 0;
BA_ "GenSigSwitchedByIgnition" SG_ 1106 EM1_HYB_14_BZ 0;
BA_ "GenSigFuncType" SG_ 1106 EM1_HYB_14_BZ 1;
BA_ "GenSigSendType" SG_ 1106 EM1_HYB_14_BZ 0;
BA_ "Fehlerwert" SG_ 1106 EM1_MaxPred_Moment 2047;
BA_ "GenSigSwitchedByIgnition" SG_ 1106 EM1_MaxPred_Moment 0;
BA_ "GenSigStartValue" SG_ 1106 EM1_MaxPred_Moment 2046;
BA_ "GenSigSendType" SG_ 1106 EM1_MaxPred_Moment 0;
BA_ "Fehlerwert" SG_ 1106 EM1_MinPred_Moment 2047;
BA_ "GenSigSwitchedByIgnition" SG_ 1106 EM1_MinPred_Moment 0;
BA_ "GenSigStartValue" SG_ 1106 EM1_MinPred_Moment 2046;
BA_ "GenSigSendType" SG_ 1106 EM1_MinPred_Moment 0;
BA_ "GenSigSwitchedByIgnition" SG_ 1106 EM1_MaxPred_Abknickdrehzahl 0;
BA_ "GenSigStartValue" SG_ 1106 EM1_MaxPred_Abknickdrehzahl 255;
BA_ "GenSigSendType" SG_ 1106 EM1_MaxPred_Abknickdrehzahl 0;
BA_ "GenSigSwitchedByIgnition" SG_ 1106 EM1_MinPred_Abknickdrehzahl 0;
BA_ "GenSigStartValue" SG_ 1106 EM1_MinPred_Abknickdrehzahl 255;
BA_ "GenSigSendType" SG_ 1106 EM1_MinPred_Abknickdrehzahl 0;
BA_ "GenSigSwitchedByIgnition" SG_ 1106 EM1_Fehler_Leistungsred 0;
BA_ "GenSigSendType" SG_ 1106 EM1_Fehler_Leistungsred 0;
BA_ "Fehlerwert" SG_ 1106 EM1_IstSpannung 4095;
BA_ "GenSigSwitchedByIgnition" SG_ 1106 EM1_IstSpannung 0;
BA_ "GenSigStartValue" SG_ 1106 EM1_IstSpannung 4094;
BA_ "GenSigSendType" SG_ 1106 EM1_IstSpannung 0;
BA_ "GenSigSwitchedByIgnition" SG_ 2527679712 EM1_RtmWarnKommunikation 0;
BA_ "GenSigSendType" SG_ 2527679712 EM1_RtmWarnKommunikation 0;
BA_ "GenSigSwitchedByIgnition" SG_ 2527679712 EM1_RtmWarnUeberdrehzahl 0;
BA_ "GenSigSendType" SG_ 2527679712 EM1_RtmWarnUeberdrehzahl 0;
BA_ "GenSigSwitchedByIgnition" SG_ 2527679712 EM1_RtmWarnUeberstrom 0;
BA_ "GenSigSendType" SG_ 2527679712 EM1_RtmWarnUeberstrom 0;
BA_ "GenSigSwitchedByIgnition" SG_ 2527679648 EM2_OBD_Lampe_Anf 0;
BA_ "GenSigSendType" SG_ 2527679648 EM2_OBD_Lampe_Anf 0;
BA_ "GenSigSwitchedByIgnition" SG_ 2527679648 EM2_FoD_Freischaltstatus_Fkt1 0;
BA_ "GenSigSendType" SG_ 2527679648 EM2_FoD_Freischaltstatus_Fkt1 0;
BA_ "Fehlerwert" SG_ 2527679648 EM2_Temperatur_ElMotor 255;
BA_ "GenSigSwitchedByIgnition" SG_ 2527679648 EM2_Temperatur_ElMotor 0;
BA_ "GenSigStartValue" SG_ 2527679648 EM2_Temperatur_ElMotor 254;
BA_ "GenSigSendType" SG_ 2527679648 EM2_Temperatur_ElMotor 0;
BA_ "Fehlerwert" SG_ 2527679648 EM2_Temperatur_PWR 255;
BA_ "GenSigSwitchedByIgnition" SG_ 2527679648 EM2_Temperatur_PWR 0;
BA_ "GenSigStartValue" SG_ 2527679648 EM2_Temperatur_PWR 254;
BA_ "GenSigSendType" SG_ 2527679648 EM2_Temperatur_PWR 0;
BA_ "Fehlerwert" SG_ 2527679648 EM2_Temperatur_Rotor 255;
BA_ "GenSigSwitchedByIgnition" SG_ 2527679648 EM2_Temperatur_Rotor 0;
BA_ "GenSigStartValue" SG_ 2527679648 EM2_Temperatur_Rotor 254;
BA_ "GenSigSendType" SG_ 2527679648 EM2_Temperatur_Rotor 0;
BA_ "Fehlerwert" SG_ 2527679648 EM2_Verlustleistung_02 1023;
BA_ "GenSigSwitchedByIgnition" SG_ 2527679648 EM2_Verlustleistung_02 0;
BA_ "GenSigStartValue" SG_ 2527679648 EM2_Verlustleistung_02 1022;
BA_ "GenSigSendType" SG_ 2527679648 EM2_Verlustleistung_02 0;
BA_ "Fehlerwert" SG_ 2527679648 EM2_Temperatur_KW 255;
BA_ "GenSigSwitchedByIgnition" SG_ 2527679648 EM2_Temperatur_KW 0;
BA_ "GenSigStartValue" SG_ 2527679648 EM2_Temperatur_KW 254;
BA_ "GenSigSendType" SG_ 2527679648 EM2_Temperatur_KW 0;
BA_ "GenSigSwitchedByIgnition" SG_ 273 EM2_HYB_06_CRC 0;
BA_ "GenSigFuncType" SG_ 273 EM2_HYB_06_CRC 2;
BA_ "GenSigSendType" SG_ 273 EM2_HYB_06_CRC 0;
BA_ "GenSigSwitchedByIgnition" SG_ 273 EM2_HYB_06_BZ 0;
BA_ "GenSigFuncType" SG_ 273 EM2_HYB_06_BZ 1;
BA_ "GenSigSendType" SG_ 273 EM2_HYB_06_BZ 0;
BA_ "GenSigSwitchedByIgnition" SG_ 273 EM2_Istmodus 0;
BA_ "GenSigStartValue" SG_ 273 EM2_Istmodus 15;
BA_ "GenSigSendType" SG_ 273 EM2_Istmodus 0;
BA_ "GenSigSwitchedByIgnition" SG_ 273 EM2_Fehler_ElAntriebAbschaltung 0;
BA_ "GenSigSendType" SG_ 273 EM2_Fehler_ElAntriebAbschaltung 0;
BA_ "GenSigSwitchedByIgnition" SG_ 273 EM2_Fehler_ElAntriebFreilauf 0;
BA_ "GenSigSendType" SG_ 273 EM2_Fehler_ElAntriebFreilauf 0;
BA_ "GenSigSwitchedByIgnition" SG_ 273 EM2_ErwGrenzen_aktiv 0;
BA_ "GenSigSendType" SG_ 273 EM2_ErwGrenzen_aktiv 0;
BA_ "GenSigSwitchedByIgnition" SG_ 273 EM2_Init_abgeschlossen 0;
BA_ "GenSigSendType" SG_ 273 EM2_Init_abgeschlossen 0;
BA_ "Fehlerwert" SG_ 273 EM2_Max_Moment 2047;
BA_ "GenSigSwitchedByIgnition" SG_ 273 EM2_Max_Moment 0;
BA_ "GenSigStartValue" SG_ 273 EM2_Max_Moment 2046;
BA_ "GenSigSendType" SG_ 273 EM2_Max_Moment 0;
BA_ "Fehlerwert" SG_ 273 EM2_Min_Moment 2047;
BA_ "GenSigSwitchedByIgnition" SG_ 273 EM2_Min_Moment 0;
BA_ "GenSigStartValue" SG_ 273 EM2_Min_Moment 2046;
BA_ "GenSigSendType" SG_ 273 EM2_Min_Moment 0;
BA_ "Fehlerwert" SG_ 273 EM2_MaxDyn_Moment 2047;
BA_ "GenSigSwitchedByIgnition" SG_ 273 EM2_MaxDyn_Moment 0;
BA_ "GenSigStartValue" SG_ 273 EM2_MaxDyn_Moment 2046;
BA_ "GenSigSendType" SG_ 273 EM2_MaxDyn_Moment 0;
BA_ "Fehlerwert" SG_ 273 EM2_MinDyn_Moment 2047;
BA_ "GenSigSwitchedByIgnition" SG_ 273 EM2_MinDyn_Moment 0;
BA_ "GenSigStartValue" SG_ 273 EM2_MinDyn_Moment 2046;
BA_ "GenSigSendType" SG_ 273 EM2_MinDyn_Moment 0;
BA_ "GenSigSwitchedByIgnition" SG_ 2463978615 EM2_HYB_11_CRC 0;
BA_ "GenSigFuncType" SG_ 2463978615 EM2_HYB_11_CRC 2;
BA_ "GenSigSendType" SG_ 2463978615 EM2_HYB_11_CRC 0;
BA_ "GenSigSwitchedByIgnition" SG_ 2463978615 EM2_HYB_11_BZ 0;
BA_ "GenSigFuncType" SG_ 2463978615 EM2_HYB_11_BZ 1;
BA_ "GenSigSendType" SG_ 2463978615 EM2_HYB_11_BZ 0;
BA_ "GenSigSwitchedByIgnition" SG_ 2463978615 EM2_Istmodus2 0;
BA_ "GenSigStartValue" SG_ 2463978615 EM2_Istmodus2 15;
BA_ "GenSigSendType" SG_ 2463978615 EM2_Istmodus2 3;
BA_ "GenSigSwitchedByIgnition" SG_ 2463978615 EM2_Fehlerstatus 0;
BA_ "GenSigStartValue" SG_ 2463978615 EM2_Fehlerstatus 7;
BA_ "GenSigSendType" SG_ 2463978615 EM2_Fehlerstatus 3;
BA_ "GenSigSwitchedByIgnition" SG_ 2463978615 EM2_Status_Spgfreiheit 0;
BA_ "GenSigSendType" SG_ 2463978615 EM2_Status_Spgfreiheit 3;
BA_ "GenSigSwitchedByIgnition" SG_ 2463978615 EM2_HYB_11_Sendestatus 0;
BA_ "GenSigSendType" SG_ 2463978615 EM2_HYB_11_Sendestatus 9;
BA_ "GenSigActiveRepetitions" SG_ 2463978615 EM2_HYB_11_Sendestatus 5;
BA_ "Fehlerwert" SG_ 2463978615 EM2_EM_SollVolumenstrom 63;
BA_ "GenSigSwitchedByIgnition" SG_ 2463978615 EM2_EM_SollVolumenstrom 0;
BA_ "GenSigStartValue" SG_ 2463978615 EM2_EM_SollVolumenstrom 62;
BA_ "GenSigSendType" SG_ 2463978615 EM2_EM_SollVolumenstrom 3;
BA_REL_ "GenSigTimeoutTime" BU_SG_REL_ Gateway SG_ 686 DCDC_01_CRC 500;
BA_REL_ "GenSigTimeoutTime" BU_SG_REL_ Gateway_PAG SG_ 686 DCDC_01_CRC 500;
BA_REL_ "GenSigTimeoutTime" BU_SG_REL_ Gateway SG_ 686 DCDC_01_BZ 500;
BA_REL_ "GenSigTimeoutTime" BU_SG_REL_ Gateway_PAG SG_ 686 DCDC_01_BZ 500;
BA_REL_ "GenSigTimeoutTime" BU_SG_REL_ BMC_MLBevo SG_ 686 DC_IstSpannung_HV 500;
BA_REL_ "GenSigTimeoutTime" BU_SG_REL_ DCDC_HV_02 SG_ 686 DC_IstSpannung_HV 500;
BA_REL_ "GenSigTimeoutTime" BU_SG_REL_ Gateway SG_ 686 DC_IstSpannung_HV 500;
BA_REL_ "GenSigTimeoutTime" BU_SG_REL_ Gateway_PAG SG_ 686 DC_IstSpannung_HV 500;
BA_REL_ "GenSigTimeoutTime" BU_SG_REL_ TME SG_ 686 DC_IstSpannung_HV 500;
BA_REL_ "GenSigTimeoutTime" BU_SG_REL_ DCDC_HV_02 SG_ 686 DC_IstStrom_HV_02 500;
BA_REL_ "GenSigTimeoutTime" BU_SG_REL_ Gateway SG_ 686 DC_IstStrom_HV_02 500;
BA_REL_ "GenSigTimeoutTime" BU_SG_REL_ Gateway_PAG SG_ 686 DC_IstStrom_HV_02 500;
BA_REL_ "GenSigTimeoutTime" BU_SG_REL_ Ladegeraet_Konzern SG_ 686 DC_IstStrom_HV_02 500;
BA_REL_ "GenSigTimeoutTime" BU_SG_REL_ TME SG_ 686 DC_IstStrom_HV_02 500;
BA_REL_ "GenSigTimeoutTime" BU_SG_REL_ Gateway SG_ 686 DC_IstStrom_NV 500;
BA_REL_ "GenSigTimeoutTime" BU_SG_REL_ Gateway_PAG SG_ 686 DC_IstStrom_NV 500;
BA_REL_ "GenSigTimeoutTime" BU_SG_REL_ AWC SG_ 686 DC_IstSpannung_NV 500;
BA_REL_ "GenSigTimeoutTime" BU_SG_REL_ Gateway SG_ 686 DC_IstSpannung_NV 500;
BA_REL_ "GenSigTimeoutTime" BU_SG_REL_ Gateway_PAG SG_ 686 DC_IstSpannung_NV 500;
BA_REL_ "GenSigTimeoutTime" BU_SG_REL_ Ladegeraet_2 SG_ 686 DC_IstSpannung_NV 500;
BA_REL_ "GenSigTimeoutTime" BU_SG_REL_ Ladegeraet_Konzern SG_ 686 DC_IstSpannung_NV 500;
BA_REL_ "GenSigTimeoutTime" BU_SG_REL_ Gateway SG_ 1012 DCDC_02_BZ 1000;
BA_REL_ "GenSigTimeoutTime" BU_SG_REL_ Gateway_PAG SG_ 1012 DCDC_02_BZ 1000;
BA_REL_ "GenSigTimeoutTime" BU_SG_REL_ Gateway SG_ 1012 DC_HYB_iAktReserveLV 1000;
BA_REL_ "GenSigTimeoutTime" BU_SG_REL_ Gateway_PAG SG_ 1012 DC_HYB_iAktReserveLV 1000;
BA_REL_ "GenSigTimeoutTime" BU_SG_REL_ Gateway SG_ 1012 DC_Verbrauch_Ueberlauf 1000;
BA_REL_ "GenSigTimeoutTime" BU_SG_REL_ Gateway_PAG SG_ 1012 DC_Verbrauch_Ueberlauf 1000;
BA_REL_ "GenSigTimeoutTime" BU_SG_REL_ Gateway SG_ 1012 DC_Verbrauch 1000;
BA_REL_ "GenSigTimeoutTime" BU_SG_REL_ Gateway_PAG SG_ 1012 DC_Verbrauch 1000;
BA_REL_ "GenSigTimeoutTime" BU_SG_REL_ TME SG_ 1012 DC_Verlustleistung 1000;
BA_REL_ "GenSigTimeoutTime" BU_SG_REL_ Gateway SG_ 1012 DC_HYB_Auslastungsgrad 1000;
BA_REL_ "GenSigTimeoutTime" BU_SG_REL_ Gateway_PAG SG_ 1012 DC_HYB_Auslastungsgrad 1000;
BA_REL_ "GenSigTimeoutTime" BU_SG_REL_ TME SG_ 1012 DC_HYB_Auslastungsgrad 1000;
BA_REL_ "GenSigTimeoutTime" BU_SG_REL_ Gateway SG_ 1485 DCDC_03_CRC 5000;
BA_REL_ "GenSigTimeoutTime" BU_SG_REL_ Gateway_PAG SG_ 1485 DCDC_03_CRC 5000;
BA_REL_ "GenSigTimeoutTime" BU_SG_REL_ Gateway SG_ 1485 DCDC_03_BZ 5000;
BA_REL_ "GenSigTimeoutTime" BU_SG_REL_ Gateway_PAG SG_ 1485 DCDC_03_BZ 5000;
BA_REL_ "GenSigTimeoutTime" BU_SG_REL_ Gateway SG_ 1485 DC_Fehlerstatus 5000;
BA_REL_ "GenSigTimeoutTime" BU_SG_REL_ Gateway_PAG SG_ 1485 DC_Fehlerstatus 5000;
BA_REL_ "GenSigTimeoutTime" BU_SG_REL_ Gateway SG_ 1485 DC_Peakstrom_verfuegbar 5000;
BA_REL_ "GenSigTimeoutTime" BU_SG_REL_ Gateway_PAG SG_ 1485 DC_Peakstrom_verfuegbar 5000;
BA_REL_ "GenSigTimeoutTime" BU_SG_REL_ TME SG_ 1485 DC_Abregelung_Temperatur 5000;
BA_REL_ "GenSigTimeoutTime" BU_SG_REL_ DCDC_HV_02 SG_ 1485 DC_IstModus_02 5000;
BA_REL_ "GenSigTimeoutTime" BU_SG_REL_ Gateway SG_ 1485 DC_IstModus_02 5000;
BA_REL_ "GenSigTimeoutTime" BU_SG_REL_ Gateway_PAG SG_ 1485 DC_IstModus_02 5000;
BA_REL_ "GenSigTimeoutTime" BU_SG_REL_ Ladegeraet_Konzern SG_ 1485 DC_IstModus_02 5000;
BA_REL_ "GenSigTimeoutTime" BU_SG_REL_ TME SG_ 1485 DC_IstModus_02 5000;
BA_REL_ "GenSigTimeoutTime" BU_SG_REL_ Gateway SG_ 1485 DC_HV_EKK_IstModus 5000;
BA_REL_ "GenSigTimeoutTime" BU_SG_REL_ Gateway_PAG SG_ 1485 DC_HV_EKK_IstModus 5000;
BA_REL_ "GenSigTimeoutTime" BU_SG_REL_ TME SG_ 1485 DC_HV_EKK_IstModus 5000;
BA_REL_ "GenSigTimeoutTime" BU_SG_REL_ Gateway SG_ 1485 DC_Status_Spgfreiheit_HV 5000;
BA_REL_ "GenSigTimeoutTime" BU_SG_REL_ Gateway_PAG SG_ 1485 DC_Status_Spgfreiheit_HV 5000;
BA_REL_ "GenSigTimeoutTime" BU_SG_REL_ Gateway SG_ 1485 DC_IstSpannung_EKK_HV 5000;
BA_REL_ "GenSigTimeoutTime" BU_SG_REL_ Gateway_PAG SG_ 1485 DC_IstSpannung_EKK_HV 5000;
BA_REL_ "GenSigTimeoutTime" BU_SG_REL_ Gateway SG_ 1485 DC_Temperatur 5000;
BA_REL_ "GenSigTimeoutTime" BU_SG_REL_ Gateway_PAG SG_ 1485 DC_Temperatur 5000;
BA_REL_ "GenSigTimeoutTime" BU_SG_REL_ TME SG_ 1485 DC_Temperatur 5000;
BA_REL_ "GenSigTimeoutTime" BU_SG_REL_ Gateway SG_ 2527679744 DCDC_FC_Status_Interlock 1000;
BA_REL_ "GenSigTimeoutTime" BU_SG_REL_ Gateway SG_ 2527679744 DCDC_FC_Status_Isowaechter_Netz2 1000;
BA_REL_ "GenSigTimeoutTime" BU_SG_REL_ TME SG_ 2527679744 DCDC_FC_Temperatur 1000;
BA_REL_ "GenSigTimeoutTime" BU_SG_REL_ Gateway SG_ 2589283653 DCDC_HV_02_01_CRC 5000;
BA_REL_ "GenSigTimeoutTime" BU_SG_REL_ Gateway_PAG SG_ 2589283653 DCDC_HV_02_01_CRC 5000;
BA_REL_ "GenSigTimeoutTime" BU_SG_REL_ Ladegeraet_Konzern SG_ 2589283653 DCDC_HV_02_01_CRC 5000;
BA_REL_ "GenSigTimeoutTime" BU_SG_REL_ Gateway SG_ 2589283653 DCDC_HV_02_01_BZ 5000;
BA_REL_ "GenSigTimeoutTime" BU_SG_REL_ Gateway_PAG SG_ 2589283653 DCDC_HV_02_01_BZ 5000;
BA_REL_ "GenSigTimeoutTime" BU_SG_REL_ Ladegeraet_Konzern SG_ 2589283653 DCDC_HV_02_01_BZ 5000;
BA_REL_ "GenSigTimeoutTime" BU_SG_REL_ Gateway SG_ 2589283653 HVLB_IstModus_TN1 5000;
BA_REL_ "GenSigTimeoutTime" BU_SG_REL_ Gateway_PAG SG_ 2589283653 HVLB_IstModus_TN1 5000;
BA_REL_ "GenSigTimeoutTime" BU_SG_REL_ Ladegeraet_Konzern SG_ 2589283653 HVLB_IstSpannung_DCLS 5000;
BA_REL_ "GenSigTimeoutTime" BU_SG_REL_ Gateway SG_ 2589283653 HVLB_StatusSpgfreiheit_HV 5000;
BA_REL_ "GenSigTimeoutTime" BU_SG_REL_ Gateway_PAG SG_ 2589283653 HVLB_StatusSpgfreiheit_HV 5000;
BA_REL_ "GenSigTimeoutTime" BU_SG_REL_ Ladegeraet_Konzern SG_ 2589283653 HVLB_IstModus 5000;
BA_REL_ "GenSigTimeoutTime" BU_SG_REL_ TME SG_ 2589283653 HVLB_IstModus 5000;
BA_REL_ "GenSigTimeoutTime" BU_SG_REL_ Ladegeraet_Konzern SG_ 2589283653 HVLB_IstStrom_HVHS 5000;
BA_REL_ "GenSigTimeoutTime" BU_SG_REL_ Gateway SG_ 2589283653 HVLB_IstSpannung_HVHS 5000;
BA_REL_ "GenSigTimeoutTime" BU_SG_REL_ Gateway_PAG SG_ 2589283653 HVLB_IstSpannung_HVHS 5000;
BA_REL_ "GenSigTimeoutTime" BU_SG_REL_ Ladegeraet_Konzern SG_ 2589283653 HVLB_IstSpannung_HVHS 5000;
BA_REL_ "GenSigTimeoutTime" BU_SG_REL_ Ladegeraet_Konzern SG_ 2589283653 HVLB_DC_Laden_ohneBoost_verfuegb 5000;
BA_REL_ "GenSigTimeoutTime" BU_SG_REL_ Ladegeraet_Konzern SG_ 2589283653 HVLB_DC_Laden_mitBoost_verfuegb 5000;
BA_REL_ "GenSigTimeoutTime" BU_SG_REL_ Ladegeraet_Konzern SG_ 2589283653 HVLB_AC_Laden_verfuegbar 5000;
BA_REL_ "GenSigTimeoutTime" BU_SG_REL_ Ladegeraet_Konzern SG_ 2589283653 HVLB_Warnzustand 5000;
BA_REL_ "GenSigTimeoutTime" BU_SG_REL_ Gateway SG_ 2589283653 HVLB_Fehlerstatus 5000;
BA_REL_ "GenSigTimeoutTime" BU_SG_REL_ Gateway_PAG SG_ 2589283653 HVLB_Fehlerstatus 5000;
BA_REL_ "GenSigTimeoutTime" BU_SG_REL_ Ladegeraet_Konzern SG_ 2589283653 HVLB_Fehlerstatus 5000;
BA_REL_ "GenSigTimeoutTime" BU_SG_REL_ Ladegeraet_Konzern SG_ 2463978669 DCDC_HV_02_02_CRC 1000;
BA_REL_ "GenSigTimeoutTime" BU_SG_REL_ Ladegeraet_Konzern SG_ 2463978669 DCDC_HV_02_02_BZ 1000;
BA_REL_ "GenSigTimeoutTime" BU_SG_REL_ TME SG_ 2463978669 HVLB_Temperatur 1000;
BA_REL_ "GenSigTimeoutTime" BU_SG_REL_ Ladegeraet_Konzern SG_ 2463978669 HVLB_IstSpannung_HVLS 1000;
BA_REL_ "GenSigTimeoutTime" BU_SG_REL_ Ladegeraet_Konzern SG_ 2463978669 HVLB_MaxDynStrom_HVLS 1000;
BA_REL_ "GenSigTimeoutTime" BU_SG_REL_ Ladegeraet_Konzern SG_ 2589283662 HVLB_PlanAntw_Verlustleistung 5000;
BA_REL_ "GenSigTimeoutTime" BU_SG_REL_ TME SG_ 2589283662 HVLB_PlanAntw_Verlustleistung 5000;
BA_REL_ "GenSigTimeoutTime" BU_SG_REL_ Ladegeraet_Konzern SG_ 2589283662 HVLB_PlanAntw_Zaehler 5000;
BA_REL_ "GenSigTimeoutTime" BU_SG_REL_ TME SG_ 2589283662 HVLB_PlanAntw_Zaehler 5000;
BA_REL_ "GenSigTimeoutTime" BU_SG_REL_ Gateway SG_ 685 DCDC_MV_01_CRC 500;
BA_REL_ "GenSigTimeoutTime" BU_SG_REL_ Gateway_PAG SG_ 685 DCDC_MV_01_CRC 500;
BA_REL_ "GenSigTimeoutTime" BU_SG_REL_ Gateway SG_ 685 DCDC_MV_01_BZ 500;
BA_REL_ "GenSigTimeoutTime" BU_SG_REL_ Gateway_PAG SG_ 685 DCDC_MV_01_BZ 500;
BA_REL_ "GenSigTimeoutTime" BU_SG_REL_ Gateway SG_ 685 DC_MV_IstSpannung_MV 500;
BA_REL_ "GenSigTimeoutTime" BU_SG_REL_ Gateway_PAG SG_ 685 DC_MV_IstSpannung_MV 500;
BA_REL_ "GenSigTimeoutTime" BU_SG_REL_ Gateway SG_ 685 DC_MV_IstStrom_MV 500;
BA_REL_ "GenSigTimeoutTime" BU_SG_REL_ Gateway_PAG SG_ 685 DC_MV_IstStrom_MV 500;
BA_REL_ "GenSigTimeoutTime" BU_SG_REL_ Gateway SG_ 685 DC_MV_IstStrom_NV 500;
BA_REL_ "GenSigTimeoutTime" BU_SG_REL_ Gateway_PAG SG_ 685 DC_MV_IstStrom_NV 500;
BA_REL_ "GenSigTimeoutTime" BU_SG_REL_ Gateway SG_ 685 DC_MV_IstSpannung_NV 500;
BA_REL_ "GenSigTimeoutTime" BU_SG_REL_ Gateway_PAG SG_ 685 DC_MV_IstSpannung_NV 500;
BA_REL_ "GenSigTimeoutTime" BU_SG_REL_ Gateway SG_ 1018 DCDC_MV_02_CRC 1000;
BA_REL_ "GenSigTimeoutTime" BU_SG_REL_ Gateway_PAG SG_ 1018 DCDC_MV_02_CRC 1000;
BA_REL_ "GenSigTimeoutTime" BU_SG_REL_ Gateway SG_ 1018 DCDC_MV_02_BZ 1000;
BA_REL_ "GenSigTimeoutTime" BU_SG_REL_ Gateway_PAG SG_ 1018 DCDC_MV_02_BZ 1000;
BA_REL_ "GenSigTimeoutTime" BU_SG_REL_ Gateway SG_ 1018 DC_MV_akt_Stromreserve_NV 1000;
BA_REL_ "GenSigTimeoutTime" BU_SG_REL_ Gateway_PAG SG_ 1018 DC_MV_akt_Stromreserve_NV 1000;
BA_REL_ "GenSigTimeoutTime" BU_SG_REL_ Gateway SG_ 1018 DC_MV_MaxStrom_MV 1000;
BA_REL_ "GenSigTimeoutTime" BU_SG_REL_ Gateway_PAG SG_ 1018 DC_MV_MaxStrom_MV 1000;
BA_REL_ "GenSigTimeoutTime" BU_SG_REL_ Gateway SG_ 1018 DC_MV_Auslastungsgrad 1000;
BA_REL_ "GenSigTimeoutTime" BU_SG_REL_ Gateway_PAG SG_ 1018 DC_MV_Auslastungsgrad 1000;
BA_REL_ "GenSigTimeoutTime" BU_SG_REL_ Gateway SG_ 1484 DCDC_MV_03_CRC 5000;
BA_REL_ "GenSigTimeoutTime" BU_SG_REL_ Gateway_PAG SG_ 1484 DCDC_MV_03_CRC 5000;
BA_REL_ "GenSigTimeoutTime" BU_SG_REL_ Gateway SG_ 1484 DCDC_MV_03_BZ 5000;
BA_REL_ "GenSigTimeoutTime" BU_SG_REL_ Gateway_PAG SG_ 1484 DCDC_MV_03_BZ 5000;
BA_REL_ "GenSigTimeoutTime" BU_SG_REL_ Gateway SG_ 1484 DCDC_MV_Peakstrom_verfuegbar 5000;
BA_REL_ "GenSigTimeoutTime" BU_SG_REL_ Gateway_PAG SG_ 1484 DCDC_MV_Peakstrom_verfuegbar 5000;
BA_REL_ "GenSigTimeoutTime" BU_SG_REL_ Gateway SG_ 1484 DC_MV_Tiefsetzen_Notbetrieb 5000;
BA_REL_ "GenSigTimeoutTime" BU_SG_REL_ Gateway_PAG SG_ 1484 DC_MV_Tiefsetzen_Notbetrieb 5000;
BA_REL_ "GenSigTimeoutTime" BU_SG_REL_ Gateway SG_ 1484 DC_MV_Fehlerstatus 5000;
BA_REL_ "GenSigTimeoutTime" BU_SG_REL_ Gateway_PAG SG_ 1484 DC_MV_Fehlerstatus 5000;
BA_REL_ "GenSigTimeoutTime" BU_SG_REL_ Gateway SG_ 1484 DC_MV_12V_Bordnetzstuetzung 5000;
BA_REL_ "GenSigTimeoutTime" BU_SG_REL_ Gateway_PAG SG_ 1484 DC_MV_12V_Bordnetzstuetzung 5000;
BA_REL_ "GenSigTimeoutTime" BU_SG_REL_ TME SG_ 1484 DC_MV_Abregelung_Temperatur 5000;
BA_REL_ "GenSigTimeoutTime" BU_SG_REL_ Gateway SG_ 1484 DC_MV_IstModus 5000;
BA_REL_ "GenSigTimeoutTime" BU_SG_REL_ Gateway_PAG SG_ 1484 DC_MV_IstModus 5000;
BA_REL_ "GenSigTimeoutTime" BU_SG_REL_ Gateway SG_ 1484 DC_MV_IstModus_02 5000;
BA_REL_ "GenSigTimeoutTime" BU_SG_REL_ Gateway SG_ 1484 DC_MV_Dyn_MinSpannung 5000;
BA_REL_ "GenSigTimeoutTime" BU_SG_REL_ Gateway_PAG SG_ 1484 DC_MV_Dyn_MinSpannung 5000;
BA_REL_ "GenSigTimeoutTime" BU_SG_REL_ Gateway SG_ 1484 DC_MV_Dyn_MaxSpannung 5000;
BA_REL_ "GenSigTimeoutTime" BU_SG_REL_ Gateway_PAG SG_ 1484 DC_MV_Dyn_MaxSpannung 5000;
BA_REL_ "GenSigTimeoutTime" BU_SG_REL_ TME SG_ 1484 DC_MV_Temperatur 5000;
BA_REL_ "GenSigTimeoutTime" BU_SG_REL_ Ladegeraet_Konzern SG_ 1520 DI_KL_58xd 2000;
BA_REL_ "GenSigTimeoutTime" BU_SG_REL_ Ladegeraet_Konzern SG_ 1520 DI_KL_58xs 2000;
BA_REL_ "GenSigTimeoutTime" BU_SG_REL_ Ladegeraet_Konzern SG_ 1520 DI_KL_58xt 2000;
BA_REL_ "GenSigTimeoutTime" BU_SG_REL_ Ladegeraet_Konzern SG_ 1603 KBI_Einheit_Streckenanz 5000;
BA_REL_ "GenSigTimeoutTime" BU_SG_REL_ TME SG_ 1603 KBI_Einheit_Temp 5000;
BA_REL_ "GenSigTimeoutTime" BU_SG_REL_ Ladegeraet_Konzern SG_ 1603 KBI_Einheit_Uhrzeit 5000;
BA_REL_ "GenSigTimeoutTime" BU_SG_REL_ TME SG_ 910 EM1_Temperatur_ElMotor 3200;
BA_REL_ "GenSigTimeoutTime" BU_SG_REL_ TME SG_ 910 EM1_Temperatur_PWR 3200;
BA_REL_ "GenSigTimeoutTime" BU_SG_REL_ TME SG_ 910 EM1_Temperatur_Rotor 3200;
BA_REL_ "GenSigTimeoutTime" BU_SG_REL_ TME SG_ 910 EM1_Verlustleistung_02 3200;
BA_REL_ "GenSigTimeoutTime" BU_SG_REL_ TME SG_ 2527679504 EM1_IstStrom 3200;
BA_REL_ "GenSigTimeoutTime" BU_SG_REL_ BMC_MLBevo SG_ 2527679504 EM1_IstDrehzahl_02 3200;
BA_REL_ "GenSigTimeoutTime" BU_SG_REL_ TME SG_ 2527679504 EM1_IstDrehzahl_02 3200;
BA_REL_ "GenSigTimeoutTime" BU_SG_REL_ TME SG_ 2527679504 EM1_IstMoment_02 3200;
BA_REL_ "GenSigTimeoutTime" BU_SG_REL_ TME SG_ 2527679504 EM1_Verlustleistung 3200;
BA_REL_ "GenSigTimeoutTime" BU_SG_REL_ Gateway SG_ 892 EM1_HYB_11_CRC 4800;
BA_REL_ "GenSigTimeoutTime" BU_SG_REL_ Gateway_PAG SG_ 892 EM1_HYB_11_CRC 4800;
BA_REL_ "GenSigTimeoutTime" BU_SG_REL_ Gateway SG_ 892 EM1_HYB_11_BZ 4800;
BA_REL_ "GenSigTimeoutTime" BU_SG_REL_ Gateway_PAG SG_ 892 EM1_HYB_11_BZ 4800;
BA_REL_ "GenSigTimeoutTime" BU_SG_REL_ BMC_MLBevo SG_ 892 EM1_Istmodus2 4800;
BA_REL_ "GenSigTimeoutTime" BU_SG_REL_ Ladegeraet_Konzern SG_ 892 EM1_Istmodus2 4800;
BA_REL_ "GenSigTimeoutTime" BU_SG_REL_ TME SG_ 892 EM1_Istmodus2 4800;
BA_REL_ "GenSigTimeoutTime" BU_SG_REL_ Gateway SG_ 892 EM1_Fehlerstatus 4800;
BA_REL_ "GenSigTimeoutTime" BU_SG_REL_ Gateway_PAG SG_ 892 EM1_Fehlerstatus 4800;
BA_REL_ "GenSigTimeoutTime" BU_SG_REL_ Gateway SG_ 892 EM1_Status_Spgfreiheit 4800;
BA_REL_ "GenSigTimeoutTime" BU_SG_REL_ Gateway_PAG SG_ 892 EM1_Status_Spgfreiheit 4800;
BA_REL_ "GenSigTimeoutTime" BU_SG_REL_ TME SG_ 892 EM1_EM_SollVolumenstrom 4800;
BA_REL_ "GenSigTimeoutTime" BU_SG_REL_ TME SG_ 2527679648 EM2_Temperatur_ElMotor 3200;
BA_REL_ "GenSigTimeoutTime" BU_SG_REL_ TME SG_ 2527679648 EM2_Temperatur_PWR 3200;
BA_REL_ "GenSigTimeoutTime" BU_SG_REL_ TME SG_ 2527679648 EM2_Temperatur_Rotor 3200;
BA_REL_ "GenSigTimeoutTime" BU_SG_REL_ TME SG_ 2527679648 EM2_Verlustleistung_02 3200;
BA_REL_ "GenSigTimeoutTime" BU_SG_REL_ Gateway SG_ 2463978615 EM2_HYB_11_CRC 4800;
BA_REL_ "GenSigTimeoutTime" BU_SG_REL_ Gateway SG_ 2463978615 EM2_HYB_11_BZ 4800;
BA_REL_ "GenSigTimeoutTime" BU_SG_REL_ TME SG_ 2463978615 EM2_Istmodus2 4800;
BA_REL_ "GenSigTimeoutTime" BU_SG_REL_ Gateway SG_ 2463978615 EM2_Fehlerstatus 4800;
BA_REL_ "GenSigTimeoutTime" BU_SG_REL_ Gateway SG_ 2463978615 EM2_Status_Spgfreiheit 4800;
BA_REL_ "GenSigTimeoutTime" BU_SG_REL_ TME SG_ 2463978615 EM2_EM_SollVolumenstrom 4800;
VAL_ 2589283856 DC_MV_Komponentenfehler_63 0 "TstNotComplThisOpCycle_Init" 1 "TstComplThisOpCycle_Pass" 2 "TstCmplThisCycle_Pass_TimeElapse" 3 "TstComplThisOpCycle_FAIL" ;
VAL_ 2589283856 DC_MV_Komponentenfehler_64 0 "TstNotComplThisOpCycle_Init" 1 "TstComplThisOpCycle_Pass" 2 "TstCmplThisCycle_Pass_TimeElapse" 3 "TstComplThisOpCycle_FAIL" ;
VAL_ 2589283856 DC_MV_Komponentenfehler_65 0 "TstNotComplThisOpCycle_Init" 1 "TstComplThisOpCycle_Pass" 2 "TstCmplThisCycle_Pass_TimeElapse" 3 "TstComplThisOpCycle_FAIL" ;
VAL_ 2589283856 DC_MV_Komponentenfehler_66 0 "TstNotComplThisOpCycle_Init" 1 "TstComplThisOpCycle_Pass" 2 "TstCmplThisCycle_Pass_TimeElapse" 3 "TstComplThisOpCycle_FAIL" ;
VAL_ 2589283856 DC_MV_Komponentenfehler_67 0 "TstNotComplThisOpCycle_Init" 1 "TstComplThisOpCycle_Pass" 2 "TstCmplThisCycle_Pass_TimeElapse" 3 "TstComplThisOpCycle_FAIL" ;
VAL_ 2589283856 DC_MV_Komponentenfehler_68 0 "TstNotComplThisOpCycle_Init" 1 "TstComplThisOpCycle_Pass" 2 "TstCmplThisCycle_Pass_TimeElapse" 3 "TstComplThisOpCycle_FAIL" ;
VAL_ 2589283856 DC_MV_Komponentenfehler_69 0 "TstNotComplThisOpCycle_Init" 1 "TstComplThisOpCycle_Pass" 2 "TstCmplThisCycle_Pass_TimeElapse" 3 "TstComplThisOpCycle_FAIL" ;
VAL_ 2589283856 DC_MV_Komponentenfehler_70 0 "TstNotComplThisOpCycle_Init" 1 "TstComplThisOpCycle_Pass" 2 "TstCmplThisCycle_Pass_TimeElapse" 3 "TstComplThisOpCycle_FAIL" ;
VAL_ 2589283856 DC_MV_Komponentenfehler_71 0 "TstNotComplThisOpCycle_Init" 1 "TstComplThisOpCycle_Pass" 2 "TstCmplThisCycle_Pass_TimeElapse" 3 "TstComplThisOpCycle_FAIL" ;
VAL_ 2589283856 DC_MV_Komponentenfehler_72 0 "TstNotComplThisOpCycle_Init" 1 "TstComplThisOpCycle_Pass" 2 "TstCmplThisCycle_Pass_TimeElapse" 3 "TstComplThisOpCycle_FAIL" ;
VAL_ 2589283856 DC_MV_Komponentenfehler_73 0 "TstNotComplThisOpCycle_Init" 1 "TstComplThisOpCycle_Pass" 2 "TstCmplThisCycle_Pass_TimeElapse" 3 "TstComplThisOpCycle_FAIL" ;
VAL_ 2589283856 DC_MV_Komponentenfehler_74 0 "TstNotComplThisOpCycle_Init" 1 "TstComplThisOpCycle_Pass" 2 "TstCmplThisCycle_Pass_TimeElapse" 3 "TstComplThisOpCycle_FAIL" ;
VAL_ 2589283856 DC_MV_Komponentenfehler_75 0 "TstNotComplThisOpCycle_Init" 1 "TstComplThisOpCycle_Pass" 2 "TstCmplThisCycle_Pass_TimeElapse" 3 "TstComplThisOpCycle_FAIL" ;
VAL_ 2589283856 DC_MV_Komponentenfehler_76 0 "TstNotComplThisOpCycle_Init" 1 "TstComplThisOpCycle_Pass" 2 "TstCmplThisCycle_Pass_TimeElapse" 3 "TstComplThisOpCycle_FAIL" ;
VAL_ 2589283856 DC_MV_Komponentenfehler_77 0 "TstNotComplThisOpCycle_Init" 1 "TstComplThisOpCycle_Pass" 2 "TstCmplThisCycle_Pass_TimeElapse" 3 "TstComplThisOpCycle_FAIL" ;
VAL_ 2589283856 DC_MV_Komponentenfehler_78 0 "TstNotComplThisOpCycle_Init" 1 "TstComplThisOpCycle_Pass" 2 "TstCmplThisCycle_Pass_TimeElapse" 3 "TstComplThisOpCycle_FAIL" ;
VAL_ 2589283856 DC_MV_Komponentenfehler_79 0 "TstNotComplThisOpCycle_Init" 1 "TstComplThisOpCycle_Pass" 2 "TstCmplThisCycle_Pass_TimeElapse" 3 "TstComplThisOpCycle_FAIL" ;
VAL_ 2589283856 DC_MV_Komponentenfehler_80 0 "TstNotComplThisOpCycle_Init" 1 "TstComplThisOpCycle_Pass" 2 "TstCmplThisCycle_Pass_TimeElapse" 3 "TstComplThisOpCycle_FAIL" ;
VAL_ 2589283856 DC_MV_Komponentenfehler_81 0 "TstNotComplThisOpCycle_Init" 1 "TstComplThisOpCycle_Pass" 2 "TstCmplThisCycle_Pass_TimeElapse" 3 "TstComplThisOpCycle_FAIL" ;
VAL_ 2589283856 DC_MV_Komponentenfehler_82 0 "TstNotComplThisOpCycle_Init" 1 "TstComplThisOpCycle_Pass" 2 "TstCmplThisCycle_Pass_TimeElapse" 3 "TstComplThisOpCycle_FAIL" ;
VAL_ 2589283856 DC_MV_Komponentenfehler_83 0 "TstNotComplThisOpCycle_Init" 1 "TstComplThisOpCycle_Pass" 2 "TstCmplThisCycle_Pass_TimeElapse" 3 "TstComplThisOpCycle_FAIL" ;
VAL_ 2589283856 DC_MV_Komponentenfehler_84 0 "TstNotComplThisOpCycle_Init" 1 "TstComplThisOpCycle_Pass" 2 "TstCmplThisCycle_Pass_TimeElapse" 3 "TstComplThisOpCycle_FAIL" ;
VAL_ 2589283856 DC_MV_Komponentenfehler_85 0 "TstNotComplThisOpCycle_Init" 1 "TstComplThisOpCycle_Pass" 2 "TstCmplThisCycle_Pass_TimeElapse" 3 "TstComplThisOpCycle_FAIL" ;
VAL_ 2589283856 DC_MV_Komponentenfehler_86 0 "TstNotComplThisOpCycle_Init" 1 "TstComplThisOpCycle_Pass" 2 "TstCmplThisCycle_Pass_TimeElapse" 3 "TstComplThisOpCycle_FAIL" ;
VAL_ 2589283856 DC_MV_Komponentenfehler_87 0 "TstNotComplThisOpCycle_Init" 1 "TstComplThisOpCycle_Pass" 2 "TstCmplThisCycle_Pass_TimeElapse" 3 "TstComplThisOpCycle_FAIL" ;
VAL_ 2589283856 DC_MV_Komponentenfehler_88 0 "TstNotComplThisOpCycle_Init" 1 "TstComplThisOpCycle_Pass" 2 "TstCmplThisCycle_Pass_TimeElapse" 3 "TstComplThisOpCycle_FAIL" ;
VAL_ 2589283856 DC_MV_Komponentenfehler_89 0 "TstNotComplThisOpCycle_Init" 1 "TstComplThisOpCycle_Pass" 2 "TstCmplThisCycle_Pass_TimeElapse" 3 "TstComplThisOpCycle_FAIL" ;
VAL_ 2589283856 DC_MV_Komponentenfehler_90 0 "TstNotComplThisOpCycle_Init" 1 "TstComplThisOpCycle_Pass" 2 "TstCmplThisCycle_Pass_TimeElapse" 3 "TstComplThisOpCycle_FAIL" ;
VAL_ 2589283856 DC_MV_Komponentenfehler_91 0 "TstNotComplThisOpCycle_Init" 1 "TstComplThisOpCycle_Pass" 2 "TstCmplThisCycle_Pass_TimeElapse" 3 "TstComplThisOpCycle_FAIL" ;
VAL_ 2589283856 DC_MV_Komponentenfehler_92 0 "TstNotComplThisOpCycle_Init" 1 "TstComplThisOpCycle_Pass" 2 "TstCmplThisCycle_Pass_TimeElapse" 3 "TstComplThisOpCycle_FAIL" ;
VAL_ 2589283856 DC_MV_Komponentenfehler_93 0 "TstNotComplThisOpCycle_Init" 1 "TstComplThisOpCycle_Pass" 2 "TstCmplThisCycle_Pass_TimeElapse" 3 "TstComplThisOpCycle_FAIL" ;
VAL_ 2589283857 DC_MV_Komponentenfehler_94 0 "TstNotComplThisOpCycle_Init" 1 "TstComplThisOpCycle_Pass" 2 "TstCmplThisCycle_Pass_TimeElapse" 3 "TstComplThisOpCycle_FAIL" ;
VAL_ 2589283857 DC_MV_Komponentenfehler_95 0 "TstNotComplThisOpCycle_Init" 1 "TstComplThisOpCycle_Pass" 2 "TstCmplThisCycle_Pass_TimeElapse" 3 "TstComplThisOpCycle_FAIL" ;
VAL_ 2589283857 DC_MV_Komponentenfehler_96 0 "TstNotComplThisOpCycle_Init" 1 "TstComplThisOpCycle_Pass" 2 "TstCmplThisCycle_Pass_TimeElapse" 3 "TstComplThisOpCycle_FAIL" ;
VAL_ 2589283857 DC_MV_Komponentenfehler_97 0 "TstNotComplThisOpCycle_Init" 1 "TstComplThisOpCycle_Pass" 2 "TstCmplThisCycle_Pass_TimeElapse" 3 "TstComplThisOpCycle_FAIL" ;
VAL_ 2589283857 DC_MV_Komponentenfehler_98 0 "TstNotComplThisOpCycle_Init" 1 "TstComplThisOpCycle_Pass" 2 "TstCmplThisCycle_Pass_TimeElapse" 3 "TstComplThisOpCycle_FAIL" ;
VAL_ 2589283857 DC_MV_Komponentenfehler_99 0 "TstNotComplThisOpCycle_Init" 1 "TstComplThisOpCycle_Pass" 2 "TstCmplThisCycle_Pass_TimeElapse" 3 "TstComplThisOpCycle_FAIL" ;
VAL_ 2589283857 DC_MV_Komponentenfehler_100 0 "TstNotComplThisOpCycle_Init" 1 "TstComplThisOpCycle_Pass" 2 "TstCmplThisCycle_Pass_TimeElapse" 3 "TstComplThisOpCycle_FAIL" ;
VAL_ 2589283857 DC_MV_Komponentenfehler_101 0 "TstNotComplThisOpCycle_Init" 1 "TstComplThisOpCycle_Pass" 2 "TstCmplThisCycle_Pass_TimeElapse" 3 "TstComplThisOpCycle_FAIL" ;
VAL_ 2589283857 DC_MV_Komponentenfehler_102 0 "TstNotComplThisOpCycle_Init" 1 "TstComplThisOpCycle_Pass" 2 "TstCmplThisCycle_Pass_TimeElapse" 3 "TstComplThisOpCycle_FAIL" ;
VAL_ 2589283857 DC_MV_Komponentenfehler_103 0 "TstNotComplThisOpCycle_Init" 1 "TstComplThisOpCycle_Pass" 2 "TstCmplThisCycle_Pass_TimeElapse" 3 "TstComplThisOpCycle_FAIL" ;
VAL_ 2589283857 DC_MV_Komponentenfehler_104 0 "TstNotComplThisOpCycle_Init" 1 "TstComplThisOpCycle_Pass" 2 "TstCmplThisCycle_Pass_TimeElapse" 3 "TstComplThisOpCycle_FAIL" ;
VAL_ 2589283857 DC_MV_Komponentenfehler_105 0 "TstNotComplThisOpCycle_Init" 1 "TstComplThisOpCycle_Pass" 2 "TstCmplThisCycle_Pass_TimeElapse" 3 "TstComplThisOpCycle_FAIL" ;
VAL_ 2589283857 DC_MV_Komponentenfehler_106 0 "TstNotComplThisOpCycle_Init" 1 "TstComplThisOpCycle_Pass" 2 "TstCmplThisCycle_Pass_TimeElapse" 3 "TstComplThisOpCycle_FAIL" ;
VAL_ 2589283857 DC_MV_Komponentenfehler_107 0 "TstNotComplThisOpCycle_Init" 1 "TstComplThisOpCycle_Pass" 2 "TstCmplThisCycle_Pass_TimeElapse" 3 "TstComplThisOpCycle_FAIL" ;
VAL_ 2589283857 DC_MV_Komponentenfehler_108 0 "TstNotComplThisOpCycle_Init" 1 "TstComplThisOpCycle_Pass" 2 "TstCmplThisCycle_Pass_TimeElapse" 3 "TstComplThisOpCycle_FAIL" ;
VAL_ 2589283857 DC_MV_Komponentenfehler_109 0 "TstNotComplThisOpCycle_Init" 1 "TstComplThisOpCycle_Pass" 2 "TstCmplThisCycle_Pass_TimeElapse" 3 "TstComplThisOpCycle_FAIL" ;
VAL_ 2589283857 DC_MV_Komponentenfehler_110 0 "TstNotComplThisOpCycle_Init" 1 "TstComplThisOpCycle_Pass" 2 "TstCmplThisCycle_Pass_TimeElapse" 3 "TstComplThisOpCycle_FAIL" ;
VAL_ 2589283857 DC_MV_Komponentenfehler_111 0 "TstNotComplThisOpCycle_Init" 1 "TstComplThisOpCycle_Pass" 2 "TstCmplThisCycle_Pass_TimeElapse" 3 "TstComplThisOpCycle_FAIL" ;
VAL_ 2589283857 DC_MV_Komponentenfehler_112 0 "TstNotComplThisOpCycle_Init" 1 "TstComplThisOpCycle_Pass" 2 "TstCmplThisCycle_Pass_TimeElapse" 3 "TstComplThisOpCycle_FAIL" ;
VAL_ 2589283857 DC_MV_Komponentenfehler_113 0 "TstNotComplThisOpCycle_Init" 1 "TstComplThisOpCycle_Pass" 2 "TstCmplThisCycle_Pass_TimeElapse" 3 "TstComplThisOpCycle_FAIL" ;
VAL_ 2589283857 DC_MV_Komponentenfehler_114 0 "TstNotComplThisOpCycle_Init" 1 "TstComplThisOpCycle_Pass" 2 "TstCmplThisCycle_Pass_TimeElapse" 3 "TstComplThisOpCycle_FAIL" ;
VAL_ 2589283857 DC_MV_Komponentenfehler_115 0 "TstNotComplThisOpCycle_Init" 1 "TstComplThisOpCycle_Pass" 2 "TstCmplThisCycle_Pass_TimeElapse" 3 "TstComplThisOpCycle_FAIL" ;
VAL_ 2589283857 DC_MV_Komponentenfehler_116 0 "TstNotComplThisOpCycle_Init" 1 "TstComplThisOpCycle_Pass" 2 "TstCmplThisCycle_Pass_TimeElapse" 3 "TstComplThisOpCycle_FAIL" ;
VAL_ 2589283857 DC_MV_Komponentenfehler_117 0 "TstNotComplThisOpCycle_Init" 1 "TstComplThisOpCycle_Pass" 2 "TstCmplThisCycle_Pass_TimeElapse" 3 "TstComplThisOpCycle_FAIL" ;
VAL_ 2589283857 DC_MV_Komponentenfehler_118 0 "TstNotComplThisOpCycle_Init" 1 "TstComplThisOpCycle_Pass" 2 "TstCmplThisCycle_Pass_TimeElapse" 3 "TstComplThisOpCycle_FAIL" ;
VAL_ 2589283857 DC_MV_Komponentenfehler_119 0 "TstNotComplThisOpCycle_Init" 1 "TstComplThisOpCycle_Pass" 2 "TstCmplThisCycle_Pass_TimeElapse" 3 "TstComplThisOpCycle_FAIL" ;
VAL_ 2589283857 DC_MV_Komponentenfehler_120 0 "TstNotComplThisOpCycle_Init" 1 "TstComplThisOpCycle_Pass" 2 "TstCmplThisCycle_Pass_TimeElapse" 3 "TstComplThisOpCycle_FAIL" ;
VAL_ 2589283857 DC_MV_Komponentenfehler_121 0 "TstNotComplThisOpCycle_Init" 1 "TstComplThisOpCycle_Pass" 2 "TstCmplThisCycle_Pass_TimeElapse" 3 "TstComplThisOpCycle_FAIL" ;
VAL_ 2589283857 DC_MV_Komponentenfehler_122 0 "TstNotComplThisOpCycle_Init" 1 "TstComplThisOpCycle_Pass" 2 "TstCmplThisCycle_Pass_TimeElapse" 3 "TstComplThisOpCycle_FAIL" ;
VAL_ 2589283857 DC_MV_Komponentenfehler_123 0 "TstNotComplThisOpCycle_Init" 1 "TstComplThisOpCycle_Pass" 2 "TstCmplThisCycle_Pass_TimeElapse" 3 "TstComplThisOpCycle_FAIL" ;
VAL_ 2589283857 DC_MV_Komponentenfehler_124 0 "TstNotComplThisOpCycle_Init" 1 "TstComplThisOpCycle_Pass" 2 "TstCmplThisCycle_Pass_TimeElapse" 3 "TstComplThisOpCycle_FAIL" ;
VAL_ 2589283858 DC_MV_Komponentenfehler_125 0 "TstNotComplThisOpCycle_Init" 1 "TstComplThisOpCycle_Pass" 2 "TstCmplThisCycle_Pass_TimeElapse" 3 "TstComplThisOpCycle_FAIL" ;
VAL_ 2589283858 DC_MV_Komponentenfehler_126 0 "TstNotComplThisOpCycle_Init" 1 "TstComplThisOpCycle_Pass" 2 "TstCmplThisCycle_Pass_TimeElapse" 3 "TstComplThisOpCycle_FAIL" ;
VAL_ 2589283858 DC_MV_Komponentenfehler_127 0 "TstNotComplThisOpCycle_Init" 1 "TstComplThisOpCycle_Pass" 2 "TstCmplThisCycle_Pass_TimeElapse" 3 "TstComplThisOpCycle_FAIL" ;
VAL_ 2589283858 DC_MV_Komponentenfehler_128 0 "TstNotComplThisOpCycle_Init" 1 "TstComplThisOpCycle_Pass" 2 "TstCmplThisCycle_Pass_TimeElapse" 3 "TstComplThisOpCycle_FAIL" ;
VAL_ 2589283858 DC_MV_Komponentenfehler_129 0 "TstNotComplThisOpCycle_Init" 1 "TstComplThisOpCycle_Pass" 2 "TstCmplThisCycle_Pass_TimeElapse" 3 "TstComplThisOpCycle_FAIL" ;
VAL_ 2589283858 DC_MV_Komponentenfehler_130 0 "TstNotComplThisOpCycle_Init" 1 "TstComplThisOpCycle_Pass" 2 "TstCmplThisCycle_Pass_TimeElapse" 3 "TstComplThisOpCycle_FAIL" ;
VAL_ 2589283858 DC_MV_Komponentenfehler_131 0 "TstNotComplThisOpCycle_Init" 1 "TstComplThisOpCycle_Pass" 2 "TstCmplThisCycle_Pass_TimeElapse" 3 "TstComplThisOpCycle_FAIL" ;
VAL_ 2589283858 DC_MV_Komponentenfehler_132 0 "TstNotComplThisOpCycle_Init" 1 "TstComplThisOpCycle_Pass" 2 "TstCmplThisCycle_Pass_TimeElapse" 3 "TstComplThisOpCycle_FAIL" ;
VAL_ 2589283858 DC_MV_Komponentenfehler_133 0 "TstNotComplThisOpCycle_Init" 1 "TstComplThisOpCycle_Pass" 2 "TstCmplThisCycle_Pass_TimeElapse" 3 "TstComplThisOpCycle_FAIL" ;
VAL_ 2589283858 DC_MV_Komponentenfehler_134 0 "TstNotComplThisOpCycle_Init" 1 "TstComplThisOpCycle_Pass" 2 "TstCmplThisCycle_Pass_TimeElapse" 3 "TstComplThisOpCycle_FAIL" ;
VAL_ 2589283858 DC_MV_Komponentenfehler_135 0 "TstNotComplThisOpCycle_Init" 1 "TstComplThisOpCycle_Pass" 2 "TstCmplThisCycle_Pass_TimeElapse" 3 "TstComplThisOpCycle_FAIL" ;
VAL_ 2589283858 DC_MV_Komponentenfehler_136 0 "TstNotComplThisOpCycle_Init" 1 "TstComplThisOpCycle_Pass" 2 "TstCmplThisCycle_Pass_TimeElapse" 3 "TstComplThisOpCycle_FAIL" ;
VAL_ 2589283858 DC_MV_Komponentenfehler_137 0 "TstNotComplThisOpCycle_Init" 1 "TstComplThisOpCycle_Pass" 2 "TstCmplThisCycle_Pass_TimeElapse" 3 "TstComplThisOpCycle_FAIL" ;
VAL_ 2589283858 DC_MV_Komponentenfehler_138 0 "TstNotComplThisOpCycle_Init" 1 "TstComplThisOpCycle_Pass" 2 "TstCmplThisCycle_Pass_TimeElapse" 3 "TstComplThisOpCycle_FAIL" ;
VAL_ 2589283858 DC_MV_Komponentenfehler_139 0 "TstNotComplThisOpCycle_Init" 1 "TstComplThisOpCycle_Pass" 2 "TstCmplThisCycle_Pass_TimeElapse" 3 "TstComplThisOpCycle_FAIL" ;
VAL_ 2589283858 DC_MV_Komponentenfehler_140 0 "TstNotComplThisOpCycle_Init" 1 "TstComplThisOpCycle_Pass" 2 "TstCmplThisCycle_Pass_TimeElapse" 3 "TstComplThisOpCycle_FAIL" ;
VAL_ 2589283858 DC_MV_Komponentenfehler_141 0 "TstNotComplThisOpCycle_Init" 1 "TstComplThisOpCycle_Pass" 2 "TstCmplThisCycle_Pass_TimeElapse" 3 "TstComplThisOpCycle_FAIL" ;
VAL_ 2589283858 DC_MV_Komponentenfehler_142 0 "TstNotComplThisOpCycle_Init" 1 "TstComplThisOpCycle_Pass" 2 "TstCmplThisCycle_Pass_TimeElapse" 3 "TstComplThisOpCycle_FAIL" ;
VAL_ 2589283858 DC_MV_Komponentenfehler_143 0 "TstNotComplThisOpCycle_Init" 1 "TstComplThisOpCycle_Pass" 2 "TstCmplThisCycle_Pass_TimeElapse" 3 "TstComplThisOpCycle_FAIL" ;
VAL_ 2589283858 DC_MV_Komponentenfehler_144 0 "TstNotComplThisOpCycle_Init" 1 "TstComplThisOpCycle_Pass" 2 "TstCmplThisCycle_Pass_TimeElapse" 3 "TstComplThisOpCycle_FAIL" ;
VAL_ 2589283858 DC_MV_Komponentenfehler_145 0 "TstNotComplThisOpCycle_Init" 1 "TstComplThisOpCycle_Pass" 2 "TstCmplThisCycle_Pass_TimeElapse" 3 "TstComplThisOpCycle_FAIL" ;
VAL_ 686 DC_IstSpannung_HV 4094 "Init" 4095 "Fehler" ;
VAL_ 686 DC_IstStrom_HV_02 1022 "Init" 1023 "Fehler" ;
VAL_ 686 DC_IstStrom_NV 1022 "Init" 1023 "Fehler" ;
VAL_ 686 DC_IstSpannung_NV 254 "Init" 255 "Fehler" ;
VAL_ 1012 DC_HYB_iAktReserveLV 1022 "Init" 1023 "Fehler" ;
VAL_ 1012 DC_Verbrauch_Ueberlauf 0 "kein_Ueberlauf" 1 "Ueberlauf" ;
VAL_ 1012 DC_Verlustleistung 62 "Init" 63 "Fehler" ;
VAL_ 1012 DC_HYB_Auslastungsgrad 254 "Init" 255 "Fehler" ;
VAL_ 1485 DC_Fehlerstatus 0 "Komponente_IO" 1 "Eingeschr_KompFkt_Entlad_defekt" 3 "Eingeschr_KompFkt_Interlock" 6 "Keine_Komponentenfunktion" 7 "Init" ;
VAL_ 1485 DC_Peakstrom_verfuegbar 0 "Peakstrom_nicht_verfuegbar" 1 "Peakstrom_verfuegbar" ;
VAL_ 1485 DC_Abregelung_Temperatur 0 "keine_Abregelung" 1 "Abregelung_Temp" ;
VAL_ 1485 DC_IstModus_02 0 "Standby" 1 "HV_On_Vorladen" 2 "Tiefsetzen" 3 "Hochsetzen" 4 "Pruefimpuls_12V" 5 "Fehler" 7 "Initialisierung" ;
VAL_ 1485 DC_HV_EKK_IstModus 0 "Standby" 2 "Tiefsetzen" 3 "Hochsetzen" 5 "Fehler" 7 "Initialisierung" ;
VAL_ 1485 DC_Status_Spgfreiheit_HV 0 "Init" 1 "HV_Komponente_spannungsfrei" 2 "HV_Komp_nicht_spannungsfrei" 3 "Fehler_nicht_spannungsfrei" ;
VAL_ 1485 DC_IstSpannung_EKK_HV 255 "Init" ;
VAL_ 1485 DC_Temperatur 254 "Init" 255 "Fehler" ;
VAL_ 2527679744 DCDC_FC_IstModus 0 "DCDC_Standby" 1 "DCDC_StromRegelung_Prim" 2 "DCDC_SpannungsRegelung_Prim" 3 "DCDC_StromRegelung_Sek" 4 "DCDC_SpannungsRegelung_Sek" 5 "DCDC_Passiv" 6 "DCDC_Kurzschluss" 7 "reserviert" 8 "reserviert" 9 "reserviert" 10 "reserviert" 11 "reserviert" 12 "reserviert" 13 "reserviert" 14 "Init" 15 "Fehler" ;
VAL_ 2527679744 DCDC_FC_Abschaltung_Ges 0 "inaktiv" 1 "aktiv" ;
VAL_ 2527679744 DCDC_FC_Abschaltung_Prim 0 "inaktiv" 1 "aktiv" ;
VAL_ 2527679744 DCDC_FC_Anf_Abschaltung_Ges 0 "inaktiv" 1 "aktiv" ;
VAL_ 2527679744 DCDC_FC_Anf_Abschaltung_Prim 0 "inaktiv" 1 "aktiv" ;
VAL_ 2527679744 DCDC_FC_Begrenz_MaxSpannung_Prim 0 "inaktiv" 1 "aktiv" ;
VAL_ 2527679744 DCDC_FC_Begrenz_MaxSpannung_Sek 0 "inaktiv" 1 "aktiv" ;
VAL_ 2527679744 DCDC_FC_Begrenz_MaxStrom_Prim 0 "inaktiv" 1 "aktiv" ;
VAL_ 2527679744 DCDC_FC_Begrenz_MaxStrom_Sek 0 "inaktiv" 1 "aktiv" ;
VAL_ 2527679744 DCDC_FC_Begrenz_MinSpannung_Prim 0 "inaktiv" 1 "aktiv" ;
VAL_ 2527679744 DCDC_FC_Begrenz_MinSpannung_Sek 0 "inaktiv" 1 "aktiv" ;
VAL_ 2527679744 DCDC_FC_Begrenz_MinStrom_Prim 0 "inaktiv" 1 "aktiv" ;
VAL_ 2527679744 DCDC_FC_Begrenz_Temp 0 "inaktiv" 1 "aktiv" ;
VAL_ 2527679744 DCDC_FC_Diodenbetrieb 0 "inaktiv" 1 "aktiv" ;
VAL_ 2527679744 DCDC_FC_Fehlerstatus 0 "kein_Fehler" 1 "Fehler_Endstufe" 2 "Fehler_Schaltelemente" 3 "Fehler_Sicherung" 4 "Fehler_Kommunikation" 5 "Fehler_Regelung" 6 "Fehler_Sensoren" 7 "reserviert" ;
VAL_ 2527679744 DCDC_FC_Status_HVSwitch 0 "HV_Schaltelemente_offen" 1 "HV_Schaltelemente_geschlossen" 2 "Vorladung_aktiv" 3 "reserviert" 4 "reserviert" 5 "reserviert" 6 "Init" 7 "Fehler" ;
VAL_ 2527679744 DCDC_FC_Status_Interlock 0 "Interlock_geschlossen" 1 "Interlock_unterbrochen" 2 "Init" 3 "Fehler" ;
VAL_ 2527679744 DCDC_FC_Status_Isowaechter_Netz2 0 "Isowaechter_Standby" 1 "Messung_aktiv" 2 "Messung_beendet" 3 "Messung_nicht_verfuegbar" 4 "Isowaechter_defekt" 5 "reserviert" 6 "Init" 7 "Fehler" ;
VAL_ 2527679744 DCDC_FC_Status_Kl15c 0 "Kl15c_inaktiv" 1 "Kl15c_aktiv" 2 "Init" 3 "Fehler" ;
VAL_ 2527679744 DCDC_FC_Status_Kl30C 0 "Kl30C_geschlossen" 1 "Kl30C_unterbrochen" 2 "Init" 3 "Fehler" ;
VAL_ 2527679744 DCDC_FC_Temperatur 254 "Init" 255 "Fehler" ;
VAL_ 2589283653 HVLB_IstModus_TN1 0 "HV_Off" 1 "HV_On" 2 "Fehler" 3 "Initialisierung" ;
VAL_ 2589283653 HVLB_IstSpannung_DCLS 4094 "Init" 4095 "Fehler" ;
VAL_ 2589283653 HVLB_StatusSpgfreiheit_HV 0 "Init" 1 "HV_Komponente_spannungsfrei" 2 "HV_Komp_nicht_spannungsfrei" 3 "Fehler_nicht_Spannungsfrei" ;
VAL_ 2589283653 HVLB_IstModus 0 "Standby" 1 "Laden_DC_ohne_Boost" 2 "Laden_DC_mit_Boost" 3 "Laden_AC" 4 "Fehler" 5 "Laden_DC_ohneBoost_ohneVorladung" 6 "Laden_DC_mitBoost_ohneVorladung" 7 "Init" ;
VAL_ 2589283653 HVLB_IstStrom_HVHS 4094 "Init" 4095 "Fehler" ;
VAL_ 2589283653 HVLB_IstSpannung_HVHS 4094 "Init" 4095 "Fehler" ;
VAL_ 2589283653 HVLB_DC_Laden_ohneBoost_verfuegb 0 "nicht_verfuegbar" 1 "verfuegbar" ;
VAL_ 2589283653 HVLB_DC_Laden_mitBoost_verfuegb 0 "nicht_verfuegbar" 1 "verfuegbar" ;
VAL_ 2589283653 HVLB_AC_Laden_verfuegbar 0 "nicht_verfuegbar" 1 "verfuegbar" ;
VAL_ 2589283653 HVLB_Warnzustand 0 "keine_Warnung" 1 "Derating_aktiv" 2 "SollModus_unplausibel" 3 "Spannungsdifferenz_zu_gross" ;
VAL_ 2589283653 HVLB_Fehlerstatus 0 "Komponente_IO" 1 "Eingeschr_KompFkt_IntFehler" 3 "Eingeschr_KompFkt_Interlock" 6 "Keine_Komponentenfunktion" 7 "Init" ;
VAL_ 2463978669 HVLB_Temperatur 254 "Init" 255 "Fehler" ;
VAL_ 2463978669 HVLB_IstSpannung_HVLS 4094 "Init" 4095 "Fehler" ;
VAL_ 2463978669 HVLB_MaxDynStrom_HVLS 4094 "Init" 4095 "Fehler" ;
VAL_ 2589283662 HVLB_PlanAntw_Verlustleistung 4094 "Init" 4095 "Fehler" ;
VAL_ 2589283662 HVLB_PlanAntw_Zaehler 14 "Init" 15 "Fehler" ;
VAL_ 685 DC_MV_IstSpannung_MV 254 "Init" 255 "Fehler" ;
VAL_ 685 DC_MV_IstStrom_MV 1022 "Init" 1023 "Fehler" ;
VAL_ 685 DC_MV_IstStrom_NV 1022 "Init" 1023 "Fehler" ;
VAL_ 685 DC_MV_IstSpannung_NV 254 "Init" 255 "Fehler" ;
VAL_ 1018 DC_MV_akt_Stromreserve_NV 1022 "Init" 1023 "Fehler" ;
VAL_ 1018 DC_MV_MaxStrom_MV 62 "Init" 63 "Fehler" ;
VAL_ 1018 DC_MV_Auslastungsgrad 254 "Init" 255 "Fehler" ;
VAL_ 1484 DCDC_MV_Peakstrom_verfuegbar 0 "Peakstrom_nicht_verfuegbar" 1 "Peakstrom_verfuegbar" ;
VAL_ 1484 DC_MV_Tiefsetzen_Notbetrieb 0 "Init" 1 "aktiv" ;
VAL_ 1484 DC_MV_Fehlerstatus 0 "Komponente_IO" 6 "Keine_Komponentenfunktion" 7 "Init" ;
VAL_ 1484 DC_MV_12V_Bordnetzstuetzung 0 "Init" 1 "aktiv" ;
VAL_ 1484 DC_MV_Abregelung_Temperatur 0 "keine_Abregelung" 1 "Abregelung_Temp" ;
VAL_ 1484 DC_MV_IstModus 0 "Standby" 1 "MV_On" 2 "Tiefsetzen" 3 "Hochsetzen" 4 "Startunterstuetzung_48V" 5 "Fehler" 6 "Startunterstuetzung_12V" 7 "Init" ;
VAL_ 1484 DC_MV_IstModus_02 0 "Standby" 1 "MV_On" 2 "Tiefsetzen" 3 "Hochsetzen" 4 "Startunterstuetzung_48V" 5 "Fehler" 6 "Startunterstuetzung_12V" 7 "Init" 9 "MV_On_Notbetrieb" 10 "Tiefsetzen_Notbetrieb" 11 "Pruefpuls_12V" ;
VAL_ 1484 DC_MV_Dyn_MinSpannung 254 "Init" ;
VAL_ 1484 DC_MV_Dyn_MaxSpannung 254 "Init" ;
VAL_ 1484 DC_MV_Temperatur 254 "Init" 255 "Fehler" ;
VAL_ 1520 DI_KL_58xd 254 "Init" 255 "Fehler" ;
VAL_ 1520 DI_KL_58xs 126 "Init" 127 "Fehler" ;
VAL_ 1520 DI_KL_58xt 126 "Init" 127 "Fehler" ;
VAL_ 1520 BCM1_Stellgroesse_Kl_58s 125 "Nicht_verbaut" 126 "Init" 127 "Fehler" ;
VAL_ 1603 KBI_Einheit_Datum 0 "Tag/Monat/Jahr" 1 "Monat/Tag/Jahr" 2 "Jahr/Monat/Tag" 3 "reserviert" ;
VAL_ 1603 KBI_Einheit_Druck 0 "Druckangabe in bar" 1 "Druckangabe in psi" 2 "Druckangabe in kPa" 3 "tbd." ;
VAL_ 1603 KBI_Einheit_Streckenanz 0 "Kilometer" 1 "Meilen" ;
VAL_ 1603 KBI_MFA_v_Einheit_02 0 "kmh" 1 "mph" ;
VAL_ 1603 KBI_Einheit_Temp 0 "Grad Celsius °C" 1 "Grad Fahrenheit °F" ;
VAL_ 1603 KBI_Einheit_Uhrzeit 0 "24h" 1 " 12h AM/PM" ;
VAL_ 1603 KBI_Einheit_Verbrauch 0 "mpg UK" 1 "mpg USA" 2 "Liter/100km" 3 "km/Liter" ;
VAL_ 1603 KBI_Einheit_Volumen 0 "Liter" 1 "Gallonen UK" 2 "Gallonen USA" 3 "reserviert" ;
VAL_ 1603 KBI_Einheit_Verbrauch_elektr 0 "kWh_pro_100km" 1 "km_pro_kWh" 2 "kWh_pro_100mls" 3 "mls_pro_kWh" 4 "MPGe" ;
VAL_ 1603 KBI_Einheit_Verbrauch_Gas 0 "kg_per_100km" 1 "km_per_kg" 2 "m3_per_100km" 3 "km_per_m3" 4 "miles_per_lbs" 5 "miles_per_yard3" 6 "miles_per_kg" 7 "miles_per_m3" 8 "miles_per_gallon_equivalent_US" ;
VAL_ 1603 KBI_Einheit_Masse 0 "kg" 1 "lbs" 2 "reserviert" ;
VAL_ 910 EM1_OBD_Lampe_Anf 0 "kein_MIL_Request" 1 "MIL_Request" ;
VAL_ 910 EM1_FoD_Freischaltstatus_Fkt1 0 "keine_FoD_Freischaltung" 1 "FoD_Freischaltung_PerformanzP" ;
VAL_ 910 EM1_Temperatur_ElMotor 254 "Init" 255 "Fehler" ;
VAL_ 910 EM1_Temperatur_PWR 254 "Init" 255 "Fehler" ;
VAL_ 910 EM1_Temperatur_Rotor 254 "Init" 255 "Fehler" ;
VAL_ 910 EM1_Verlustleistung_02 1022 "Init" 1023 "Fehler" ;
VAL_ 910 EM1_Temperatur_KW 254 "Init" 255 "Fehler" ;
VAL_ 135 EM1_Istmodus 0 "Standby" 1 "Momentenreg" 2 "Int_Drehzahlreg" 3 "Spannungsreg" 4 "Ext_Drehzahlreg" 5 "Inverter_Fehler" 6 "Kalibrierung" 7 "Sonderbremsbetrieb" 8 "Freilauf" 15 "Initialisierung" ;
VAL_ 135 EM1_Fehler_ElAntriebAbschaltung 0 "Init" 1 "Abschaltung" ;
VAL_ 135 EM1_Fehler_ElAntriebFreilauf 0 "Init" 1 "Fehler__EM_im_Freilauf" ;
VAL_ 135 EM1_ErwGrenzen_aktiv 0 "kein_extended_Range" 1 "extended_Range" ;
VAL_ 135 EM1_Init_abgeschlossen 0 "Init" 1 "Ready_Init" ;
VAL_ 135 EM1_Max_Moment 2046 "Init" 2047 "Fehler" ;
VAL_ 135 EM1_Min_Moment 2046 "Init" 2047 "Fehler" ;
VAL_ 135 EM1_MaxDyn_Moment 2046 "Init" 2047 "Fehler" ;
VAL_ 135 EM1_MinDyn_Moment 2046 "Init" 2047 "Fehler" ;
VAL_ 2527679504 EM1_IstStrom 2046 "Init" 2047 "Fehler" ;
VAL_ 2527679504 EM1_IstDrehzahl_02 32766 "Init" 32767 "Fehler" ;
VAL_ 2527679504 EM1_IstMoment_02 4094 "Init" 4095 "Fehler" ;
VAL_ 2527679504 EM1_Verlustleistung 254 "Init" 255 "Fehler" ;
VAL_ 892 EM1_Istmodus2 0 "Standby" 1 "Momentenreg" 2 "Int_Drehzahlreg" 3 "Spannungsreg" 4 "Ext_Drehzahlreg" 5 "Inverter_Fehler" 6 "Kalibrierung" 8 "Freilauf" 15 "Initialisierung" ;
VAL_ 892 EM1_Fehlerstatus 0 "Komponente_IO" 1 "Eingeschr_KompFkt_Entlad_defekt" 2 "Eingeschr_KompFkt_Phasenabriss" 3 "Eingeschr_KompFkt_Interlock" 4 "Eingeschr_KompFkt_res" 6 "Keine_Komponentenfunktion" 7 "Init" ;
VAL_ 892 EM1_Status_Spgfreiheit 0 "Init" 1 "HV_Komponente_spannungsfrei" 2 "HV_Komp_nicht_spannungsfrei" 3 "Fehler_nicht_spannungsfrei" ;
VAL_ 892 EM1_HYB_11_Sendestatus 0 "EM1_HYB_11_wird_mit_500ms_gesendet" 1 "EM1_HYB_11_wird_mit_50ms_gesendet" ;
VAL_ 892 EM1_EM_SollVolumenstrom 62 "Init" 63 "Fehler" ;
VAL_ 115 EM1_IstMoment 4094 "Init" 4095 "Fehler" ;
VAL_ 115 EM1_IstDrehzahl_alt 32766 "Init" 32767 "Fehler" ;
VAL_ 115 EM1_IstDrehzahl 32766 "Init" 32767 "Fehler" ;
VAL_ 115 EM1_MaxZul_Drehzahl 254 "Init" 255 "Fehler" ;
VAL_ 184 EM1_Freigabe_Info_WFS 0 "ungueltig" 1 "gueltig" ;
VAL_ 184 EM1_Sperr_Info_WFS 0 "nicht_gesperrt" 1 "gesperrt" ;
VAL_ 184 EM1_AR_aktiv 0 "Init" 1 "Ruckeldaempfer_aktiv" ;
VAL_ 184 EM1_Eta_Sys 510 "Init" 511 "Fehler" ;
VAL_ 184 EM1_IstStrom 2046 "Init" 2047 "Fehler" ;
VAL_ 184 EM1_Fehler_ElAntriebFreilauf_Anf 0 "Init" 1 "Fehler_EM_im_Freilauf" ;
VAL_ 184 EM1_Abregelung_Temperatur 0 "Init" 1 "Abregelung_Temperatur" ;
VAL_ 184 EM1_AnlernenElMotor_Anf 0 "kein_Diagnose_Request" 1 "Diagnose_Request" ;
VAL_ 184 EM1_Moment_HVVerbraucher 1023 "Init" ;
VAL_ 184 EM1_Freigabe_Verfallsinfo_WFS 0 "Aus" 1 "Ein" ;
VAL_ 184 EM1_Parken_WFS_Status 0 "Limitierung_Inaktiv" 1 "Limitierung_Aktiv" 2 "Abbruch" ;
VAL_ 184 EM1_HV_betriebsbereit 0 "Init" 1 "Ready_HV" ;
VAL_ 1106 EM1_MaxPred_Moment 2046 "Init" 2047 "Fehler" ;
VAL_ 1106 EM1_MinPred_Moment 2046 "Init" 2047 "Fehler" ;
VAL_ 1106 EM1_MaxPred_Abknickdrehzahl 255 "Init" ;
VAL_ 1106 EM1_MinPred_Abknickdrehzahl 255 "Init" ;
VAL_ 1106 EM1_Fehler_Leistungsred 0 "Init" 1 "Leistungsreduzierung" ;
VAL_ 1106 EM1_IstSpannung 4094 "Init" 4095 "Fehler" ;
VAL_ 2527679712 EM1_RtmWarnKommunikation 0 "kein_Fehler" 1 "Fehler_Stufe_1" 2 "Fehler_Stufe_2" 3 "Fehler_Stufe_3" 4 "reserviert" 5 "reserviert" 6 "reserviert" 7 "reserviert" ;
VAL_ 2527679712 EM1_RtmWarnUeberdrehzahl 0 "kein_Fehler" 1 "Fehler_Stufe_1" 2 "Fehler_Stufe_2" 3 "Fehler_Stufe_3" 4 "reserviert" 5 "reserviert" 6 "reserviert" 7 "reserviert" ;
VAL_ 2527679712 EM1_RtmWarnUeberstrom 0 "kein_Fehler" 1 "Fehler_Stufe_1" 2 "Fehler_Stufe_2" 3 "Fehler_Stufe_3" 4 "reserviert" 5 "reserviert" 6 "reserviert" 7 "reserviert" ;
VAL_ 2527679648 EM2_OBD_Lampe_Anf 0 "kein_MIL_Request" 1 "MIL_Request" ;
VAL_ 2527679648 EM2_FoD_Freischaltstatus_Fkt1 0 "keine_FoD_Freischaltung" 1 "FoD_Freischaltung_PerformanzP" ;
VAL_ 2527679648 EM2_Temperatur_ElMotor 254 "Init" 255 "Fehler" ;
VAL_ 2527679648 EM2_Temperatur_PWR 254 "Init" 255 "Fehler" ;
VAL_ 2527679648 EM2_Temperatur_Rotor 254 "Init" 255 "Fehler" ;
VAL_ 2527679648 EM2_Verlustleistung_02 1022 "Init" 1023 "Fehler" ;
VAL_ 2527679648 EM2_Temperatur_KW 254 "Init" 255 "Fehler" ;
VAL_ 273 EM2_Istmodus 0 "Standby" 1 "Momentenreg" 2 "Int_Drehzahlreg" 3 "Spannungsreg" 4 "Ext_Drehzahlreg" 5 "Inverter_Fehler" 6 "Kalibrierung" 7 "Sonderbremsbetrieb" 8 "Freilauf" 15 "Initialisierung" ;
VAL_ 273 EM2_Fehler_ElAntriebAbschaltung 0 "Init" 1 "Abschaltung" ;
VAL_ 273 EM2_Fehler_ElAntriebFreilauf 0 "Init" 1 "Fehler__EM_im_Freilauf" ;
VAL_ 273 EM2_ErwGrenzen_aktiv 0 "kein_extended_Range" 1 "extended_Range" ;
VAL_ 273 EM2_Init_abgeschlossen 0 "Init" 1 "Ready_Init" ;
VAL_ 273 EM2_Max_Moment 2046 "Init" 2047 "Fehler" ;
VAL_ 273 EM2_Min_Moment 2046 "Init" 2047 "Fehler" ;
VAL_ 273 EM2_MaxDyn_Moment 2046 "Init" 2047 "Fehler" ;
VAL_ 273 EM2_MinDyn_Moment 2046 "Init" 2047 "Fehler" ;
VAL_ 2463978615 EM2_Istmodus2 0 "Standby" 1 "Momentenreg" 2 "Int_Drehzahlreg" 3 "Spannungsreg" 4 "Ext_Drehzahlreg" 5 "Inverter_Fehler" 6 "Kalibrierung" 8 "Freilauf" 15 "Initialisierung" ;
VAL_ 2463978615 EM2_Fehlerstatus 0 "Komponente_IO" 1 "Eingeschr_KompFkt_Entlad_defekt" 2 "Eingeschr_KompFkt_Phasenabriss" 3 "Eingeschr_KompFkt_Interlock" 4 "Eingeschr_KompFkt_res" 6 "Keine_Komponentenfunktion" 7 "Init" ;
VAL_ 2463978615 EM2_Status_Spgfreiheit 0 "Init" 1 "HV_Komponente_spannungsfrei" 2 "HV_Komp_nicht_spannungsfrei" 3 "Fehler_nicht_spannungsfrei" ;
VAL_ 2463978615 EM2_HYB_11_Sendestatus 0 "EM2_HYB_11_wird_mit_500ms_gesendet" 1 "EM2_HYB_11_wird_mit_50ms_gesendet" ;
VAL_ 2463978615 EM2_EM_SollVolumenstrom 62 "Init" 63 "Fehler" ;
